VERSION ""

NS_ :

BS_:

BU_: ETH

BO_ 946 BMS_log2: 8 Vector__XXX
 SG_ BMS_log2MuxId M : 0|7@1+ (1,0) [0|0] "" Vector__XXX
 SG_ BMS_acRippleConfigNvramValid m18 : 7|1@1+ (1,0) [0|0] "" Vector__XXX
 SG_ BMS_acRippleHeatingDesired m28 : 7|1@1+ (1,0) [0|0] "" Vector__XXX
 SG_ BMS_acRippleStopTemperatureMax m19 : 7|9@1+ (0.25,-25) [0|0] "" Vector__XXX
 SG_ BMS_alphaAlertLimitingEnabled m68 : 7|1@1+ (1,0) [0|0] "" Vector__XXX
 SG_ BMS_alphaSoc1SnapshotState m34 : 7|1@1+ (1,0) [0|0] "" Vector__XXX
 SG_ BMS_lifeModelNoCurrentStorageCapacityLoss m54 : 7|9@1+ (0.1,0) [0|0] "" Vector__XXX
 SG_ BMS_maxChargeRestartNeededByVoltage m0 : 7|1@1+ (1,0) [0|0] "" Vector__XXX
 SG_ BMS_spmeElyteModelValidFlag m48 : 7|1@1+ (1,0) [0|0] "" Vector__XXX
 SG_ BMS_tempVsSocTotalChgEnergy m31 : 7|25@1+ (0.0001490116163793688,0) [0|0] "" Vector__XXX
 SG_ BMS_tempVsSocTotalTime m30 : 7|25@1+ (0.01,0) [0|0] "" Vector__XXX
 SG_ BMS_tempVsVoltageTotalDcChgEnergy m32 : 7|25@1+ (0.0001490116163793688,0) [0|0] "" Vector__XXX
 SG_ BMS_unexpectedLossOfLvPcsMia m57 : 7|1@1+ (1,0) [0|0] "" Vector__XXX
 SG_ BMS_100HzTask_avgExecTime m8 : 8|14@1+ (1,0) [0|0] "" Vector__XXX
 SG_ BMS_10HzTask_avgExecTime m7 : 8|17@1+ (1,0) [0|0] "" Vector__XXX
 SG_ BMS_1HzTask_avgExecTime m6 : 8|20@1+ (1,0) [0|0] "" Vector__XXX
 SG_ BMS_ahChargeTotal m5 : 8|24@1+ (0.1,0) [0|0] "" Vector__XXX
 SG_ BMS_alphaConfigNvramValid m68 : 8|1@1+ (1,0) [0|0] "" Vector__XXX
 SG_ BMS_avgRawCacForSpread m62 : 8|12@1+ (0.1,0) [0|0] "" Vector__XXX
 SG_ BMS_brick1SocCorrectionMagnitude m74 : 8|11@1- (0.1,0) [0|0] "" Vector__XXX
 SG_ BMS_brickBleedByAhTarget m36 : 8|13@1+ (0.1,0) [0|0] "" Vector__XXX
 SG_ BMS_brickBleedChargeMin m34 : 8|16@1+ (0.1,0) [0|0] "" Vector__XXX
 SG_ BMS_brickBleedChargeRef m35 : 8|16@1+ (0.1,0) [0|0] "" Vector__XXX
 SG_ BMS_brickBleedExcessChargeMin m37 : 8|16@1+ (0.1,0) [0|0] "" Vector__XXX
 SG_ BMS_brickCacSpreadErrorStdDeviation m61 : 8|10@1+ (0.01,0) [0|0] "" Vector__XXX
 SG_ BMS_cacAgedLowerBoundEstBrick1 m59 : 8|13@1+ (0.1,0) [0|0] "" Vector__XXX
 SG_ BMS_cacAgedUpdateShuntAhError m58 : 8|9@1+ (0.1,-10) [0|0] "" Vector__XXX
 SG_ BMS_cacAvg m0 : 8|13@1+ (0.1,0) [0|0] "" Vector__XXX
 SG_ BMS_cacMetadataNvramIsValid m2 : 8|1@1+ (1,0) [0|0] "" Vector__XXX
 SG_ BMS_cacMinLowerBoundEst m1 : 8|13@1+ (0.1,0) [0|0] "" Vector__XXX
 SG_ BMS_cacMinSocByOcvStart m22 : 8|10@1+ (0.1,0) [0|0] "" Vector__XXX
 SG_ BMS_cacRawImbalanceEstimate m44 : 8|10@1+ (0.1,0) [0|0] "" Vector__XXX
 SG_ BMS_cellAttributesGeneralAttributes m85 : 8|32@1+ (1,0) [0|0] "" Vector__XXX
 SG_ BMS_chargeEnergyCounter m86 : 8|8@1+ (1,0) [0|0] "" Vector__XXX
 SG_ BMS_cumulativeBleedTime m39 : 8|24@1+ (1,0) [0|0] "" Vector__XXX
 SG_ BMS_cumulativeBleedTimeDaily m47 : 8|24@1+ (1,0) [0|0] "" Vector__XXX
 SG_ BMS_cumulativeBrickBleedTimeMax m41 : 8|32@1+ (1,0) [0|0] "" Vector__XXX
 SG_ BMS_cumulativeBrickBleedTimeMin m40 : 8|32@1+ (1,0) [0|0] "" Vector__XXX
 SG_ BMS_dSocMaxAlphaSocBleedMargin m42 : 8|12@1+ (0.0030517578125,0) [0|0] "" Vector__XXX
 SG_ BMS_dSocNormalizedMin m33 : 8|12@1+ (0.0030517578125,-12.4969482421875) [0|0] "" Vector__XXX
 SG_ BMS_energyLowestChgBrickSoc m87 : 8|10@1+ (0.1,0) [0|0] "" Vector__XXX
 SG_ BMS_energyVariableChgRequested m21 : 8|1@1+ (1,0) [0|0] "" Vector__XXX
 SG_ BMS_energyWalkCounter m83 : 8|8@1+ (1,0) [0|0] "" Vector__XXX
 SG_ BMS_epochTimeEstimate m29 : 8|32@1+ (1,0) [0|0] "" Vector__XXX
 SG_ BMS_fcLinkTestDecayTime m20 : 8|10@1+ (2,0) [0|0] "" Vector__XXX
 SG_ BMS_histStartEpochTime m28 : 8|32@1+ (1,0) [0|0] "" Vector__XXX
 SG_ BMS_hvChain_useLeakyBucket m18 : 8|1@1+ (1,0) [0|0] "" Vector__XXX
 SG_ BMS_hvacCoolingChargeCurrentLimit m88 : 8|10@1+ (1,0) [0|0] "" Vector__XXX
 SG_ BMS_isoResistanceIntPositive m43 : 8|10@1+ (10,0) [0|0] "" Vector__XXX
 SG_ BMS_largestCacSpreadErrorBrickId m63 : 8|7@1+ (1,1) [0|0] "" Vector__XXX
 SG_ BMS_largestCacSpreadErrorLower m64 : 8|12@1+ (0.1,0) [0|0] "" Vector__XXX
 SG_ BMS_largestDerivedCacErrorBrickId m67 : 8|8@1+ (1,1) [0|0] "" Vector__XXX
 SG_ BMS_largestSynchronizedCacErrorPctInWindow m81 : 8|8@1+ (0.1,0) [0|0] "" Vector__XXX
 SG_ BMS_lifeModelAvgTempSeverity m55 : 8|5@1+ (0.1,0) [0|0] "" Vector__XXX
 SG_ BMS_lifeModelMaxCacBrickId m65 : 8|8@1+ (1,1) [0|0] "" Vector__XXX
 SG_ BMS_lifeModelSpreadMinOffset m60 : 8|10@1- (0.1,0) [0|0] "" Vector__XXX
 SG_ BMS_lifeModelStorageTemperatureSeverityMax m78 : 8|7@1+ (0.1,0) [0|0] "" Vector__XXX
 SG_ BMS_limpChargeCurrentLimit m89 : 8|10@1+ (1,0) [0|0] "" Vector__XXX
 SG_ BMS_loadReg_output m4 : 8|11@1- (0.1,0) [0|0] "" Vector__XXX
 SG_ BMS_maxSocChange m24 : 8|11@1- (0.1,0) [0|0] "" Vector__XXX
 SG_ BMS_maxSpreadCacChange m75 : 8|10@1- (0.1,0) [0|0] "" Vector__XXX
 SG_ BMS_maxSpreadChangeSocEnd m76 : 8|10@1+ (0.1,0) [0|0] "" Vector__XXX
 SG_ BMS_minBrickAhDischargedAfterZero m70 : 8|16@1+ (0.1,0) [0|0] "" Vector__XXX
 SG_ BMS_minCapacityLoss m38 : 8|10@1+ (0.1,0) [0|0] "" Vector__XXX
 SG_ BMS_negCtrCommonModeRejError m17 : 8|13@1- (2.442592959e-05,0) [0|0] "" Vector__XXX
 SG_ BMS_negCtrDeviationFiltMin m15 : 8|13@1- (0.001221299164314,0) [0|0] "" Vector__XXX
 SG_ BMS_negCtrDeviationMin m14 : 8|13@1- (0.001221299164314,0) [0|0] "" Vector__XXX
 SG_ BMS_negCtrDropCorrectedMin m16 : 8|13@1- (0.001221299164314,0) [0|0] "" Vector__XXX
 SG_ BMS_nominalFullPackEnergyRaw m56 : 8|16@1+ (0.02,0) [0|0] "" Vector__XXX
 SG_ BMS_posCtrCommonModeRejError m13 : 8|13@1- (2.4425983286e-05,0) [0|0] "" Vector__XXX
 SG_ BMS_posCtrDeviationFiltMin m11 : 8|13@1- (0.001221299164314,0) [0|0] "" Vector__XXX
 SG_ BMS_posCtrDeviationMin m10 : 8|13@1- (0.001221299164314,0) [0|0] "" Vector__XXX
 SG_ BMS_posCtrDropCorrectedMin m12 : 8|13@1- (0.001221299164314,0) [0|0] "" Vector__XXX
 SG_ BMS_posCtrResistance m9 : 8|13@1- (2.442598329e-06,0) [0|0] "" Vector__XXX
 SG_ BMS_restingPointCacMaxBrickId m66 : 8|8@1+ (1,1) [0|0] "" Vector__XXX
 SG_ BMS_rubberBandingConfigMaxBlendRate m72 : 8|13@1+ (0.01,0) [0|0] "" Vector__XXX
 SG_ BMS_sleepCurrentSampleMin m84 : 8|15@1- (0.2,0) [0|0] "" Vector__XXX
 SG_ BMS_socByDeltaVEnabled m90 : 8|1@1+ (1,0) [0|0] "" Vector__XXX
 SG_ BMS_socByDvMaxSocByAhRaw m91 : 8|10@1+ (0.1,0) [0|0] "" Vector__XXX
 SG_ BMS_socByOcvEst m69 : 8|10@1+ (0.1,0) [0|0] "" Vector__XXX
 SG_ BMS_socCorrectionCycleFlag m73 : 8|1@1+ (1,0) [0|0] "" Vector__XXX
 SG_ BMS_sohEnergy m79 : 8|11@1+ (0.1,0) [0|0] "" Vector__XXX
 SG_ BMS_sohLowSocPointMinPackTemp m82 : 8|9@1+ (0.25,-25) [0|0] "" Vector__XXX
 SG_ BMS_sohTestStateInternal m45 : 8|4@1+ (1,0) [0|0] "" Vector__XXX
 SG_ BMS_spmeBrick1BrickSocNominal m50 : 8|10@1+ (0.1,0) [0|0] "" Vector__XXX
 SG_ BMS_spmeBrick1ElectrolyteVoltage m49 : 8|13@1- (0.001,0) [0|0] "" Vector__XXX
 SG_ BMS_spmeMaxSocBrickId m53 : 8|8@1+ (1,1) [0|0] "" Vector__XXX
 SG_ BMS_spmeMinBrickModel0Cost m51 : 8|12@1+ (1e-05,0) [0|0] "" Vector__XXX
 SG_ BMS_spmeMinSocBrickId m52 : 8|8@1+ (1,1) [0|0] "" Vector__XXX
 SG_ BMS_spmeModelRunning m48 : 8|1@1+ (1,0) [0|0] "" Vector__XXX
 SG_ BMS_stateOfHealthAvgCacByFreshOcv m77 : 8|13@1+ (0.1,0) [0|0] "" Vector__XXX
 SG_ BMS_stateOfHealthMinCac m80 : 8|13@1+ (0.1,0) [0|0] "" Vector__XXX
 SG_ BMS_synchronizedCacMaxRaw m71 : 8|12@1+ (0.1,0) [0|0] "" Vector__XXX
 SG_ BMS_tempVsSocTimeWeightedAvgSoc m46 : 8|14@1+ (0.01,0) [0|0] "" Vector__XXX
 SG_ BMS_unexpectedLossOfLvPcsDcDcLvSupportStatus m57 : 8|2@1+ (1,0) [0|0] "" Vector__XXX
 SG_ BMS_vChangeWindowMaxVChange m23 : 8|7@1- (0.0025,0) [0|0] "" Vector__XXX
 SG_ BMS_vshResMaxIndex1 m25 : 8|6@1+ (1,0) [0|0] "" Vector__XXX
 SG_ BMS_vshResMaxIndex4 m27 : 8|6@1+ (1,0) [0|0] "" Vector__XXX
 SG_ BMS_vshResMinIndex2 m26 : 8|6@1+ (1,0) [0|0] "" Vector__XXX
 SG_ BMS_vshTestMaxDeltaV m3 : 8|16@1- (0.0002,0) [0|0] "" Vector__XXX
 SG_ BMS_alphaAlertThreshold m68 : 9|12@1+ (0.0030517578125,-12.4969482421875) [0|0] "" Vector__XXX
 SG_ BMS_cacNvramIsValid m2 : 9|1@1+ (1,0) [0|0] "" Vector__XXX
 SG_ BMS_hvChain_iLimit m18 : 9|14@1+ (0.2,0) [0|0] "" Vector__XXX
 SG_ BMS_minBrickSocCorrectionType m73 : 9|2@1+ (1,0) [0|0] "" Vector__XXX
 SG_ BMS_packRestTime m21 : 9|12@1+ (0.01758241758,0) [0|0] "" Vector__XXX
 SG_ BMS_socByDvMaxSocLimit m90 : 9|10@1+ (0.1,0) [0|0] "" Vector__XXX
 SG_ BMS_spmeNominalAhThroughput m48 : 9|16@1+ (0.1,0) [0|0] "" Vector__XXX
 SG_ BMS_floodPortState1 m2 : 10|3@1+ (1,0) [0|0] "" Vector__XXX
 SG_ BMS_stateOfHealthAvgCac m57 : 10|13@1+ (0.1,0) [0|0] "" Vector__XXX
 SG_ BMS_minBrickSocCorrectionMagnitude m73 : 11|11@1- (0.1,0) [0|0] "" Vector__XXX
 SG_ BMS_kwhDchAtSohCapture m45 : 12|32@1+ (1,0) [0|0] "" Vector__XXX
 SG_ BMS_floodPortState2 m2 : 13|3@1+ (1,0) [0|0] "" Vector__XXX
 SG_ BMS_vshResMinIndex4 m27 : 14|6@1+ (1,0) [0|0] "" Vector__XXX
 SG_ BMS_energyLatchedMaxChargePower m86 : 16|9@1+ (1,0) [0|0] "" Vector__XXX
 SG_ BMS_energyReserveMin m19 : 16|16@1+ (0.001,0) [0|0] "" Vector__XXX
 SG_ BMS_energyWalkTimeoutCounter m83 : 16|8@1+ (1,0) [0|0] "" Vector__XXX
 SG_ BMS_floodPortV1 m2 : 16|16@1+ (0.001,0) [0|0] "" Vector__XXX
 SG_ BMS_largestCacSpreadErrorBrickStartSoc m63 : 16|10@1+ (0.1,0) [0|0] "" Vector__XXX
 SG_ BMS_largestDerivedCacError m67 : 16|10@1- (0.01,0) [0|0] "" Vector__XXX
 SG_ BMS_lifeModelDepthOfDischargeSeverity m55 : 16|8@1+ (0.01,0) [0|0] "" Vector__XXX
 SG_ BMS_lifeModelMaxCac m65 : 16|12@1+ (0.1,0) [0|0] "" Vector__XXX
 SG_ BMS_lifeModelShortDcr m54 : 16|8@1+ (0.01,0) [0|0] "" Vector__XXX
 SG_ BMS_lifeModelStorageDcr1TemperatureSeverityMax m78 : 16|7@1+ (0.1,0) [0|0] "" Vector__XXX
 SG_ BMS_maxZScoreInTimeWindow m81 : 16|6@1+ (0.1,0) [0|0] "" Vector__XXX
 SG_ BMS_restingPointCacMax m66 : 16|12@1+ (0.1,0) [0|0] "" Vector__XXX
 SG_ BMS_spmeMaxSocLowestCost m53 : 16|10@1+ (0.1,0) [0|0] "" Vector__XXX
 SG_ BMS_spmeMinSocLowestCost m52 : 16|10@1+ (0.1,0) [0|0] "" Vector__XXX
 SG_ BMS_vChangeWindowMaxVChangeId m23 : 16|7@1+ (1,1) [0|0] "" Vector__XXX
 SG_ BMS_vshResMax1 m25 : 16|12@1+ (0.002,0) [0|0] "" Vector__XXX
 SG_ BMS_vshResMin2 m26 : 16|12@1+ (0.002,0) [0|0] "" Vector__XXX
 SG_ BMS_cacMinAgedLowerBoundEst m58 : 17|13@1+ (0.1,0) [0|0] "" Vector__XXX
 SG_ BMS_sohHighSocPointMinPackTemp m82 : 17|9@1+ (0.25,-25) [0|0] "" Vector__XXX
 SG_ BMS_cacMinSocByOcvEnd m22 : 18|10@1+ (0.1,0) [0|0] "" Vector__XXX
 SG_ BMS_cacRawImbalanceUpperBound m44 : 18|10@1+ (0.1,0) [0|0] "" Vector__XXX
 SG_ BMS_configChargeCurrentLimit m88 : 18|10@1+ (1,0) [0|0] "" Vector__XXX
 SG_ BMS_energyLowestChgBrickCac m87 : 18|13@1+ (0.1,0) [0|0] "" Vector__XXX
 SG_ BMS_energyRemainingDisplayError m89 : 18|10@1- (0.1,0) [0|0] "" Vector__XXX
 SG_ BMS_fcLinkTestTimeSinceLastRun m20 : 18|12@1+ (0.01758241758,0) [0|0] "" Vector__XXX
 SG_ BMS_firstSynchronizedCacUpdateTime m76 : 18|32@1+ (1,0) [0|0] "" Vector__XXX
 SG_ BMS_isoResistanceIntNegative m43 : 18|10@1+ (10,0) [0|0] "" Vector__XXX
 SG_ BMS_lifeModelSpreadMaxOffset m60 : 18|10@1- (0.1,0) [0|0] "" Vector__XXX
 SG_ BMS_maxCapacityLoss m38 : 18|10@1+ (0.1,0) [0|0] "" Vector__XXX
 SG_ BMS_maxSpreadChangeBrickId m75 : 18|8@1+ (1,1) [0|0] "" Vector__XXX
 SG_ BMS_minCacBrickBiasedSpreadAhError m61 : 18|10@1+ (0.01,0) [0|0] "" Vector__XXX
 SG_ BMS_socByOcvMax m69 : 18|10@1+ (0.1,0) [0|0] "" Vector__XXX
 SG_ BMS_spmeBrick1SocLowestCost m50 : 18|10@1+ (0.1,0) [0|0] "" Vector__XXX
 SG_ BMS_voltageInstabilityExcessNoiseLog m91 : 18|12@1+ (0.1,0) [0|0] "" Vector__XXX
 SG_ BMS_brick1SocCorrectionFinalSoc m74 : 19|10@1+ (0.1,0) [0|0] "" Vector__XXX
 SG_ BMS_fullCapacitySohEnergy m79 : 19|11@1+ (0.1,0) [0|0] "" Vector__XXX
 SG_ BMS_offsetReg_output m4 : 19|14@1- (0.1,0) [0|0] "" Vector__XXX
 SG_ BMS_socByDvVoltageChangeOverAh m90 : 19|9@1+ (0.002,0) [0|0] "" Vector__XXX
 SG_ BMS_vChangeWindowNumOutlierChanges m24 : 19|5@1+ (1,0) [0|0] "" Vector__XXX
 SG_ BMS_dSocNormalizedFiltMin m33 : 20|12@1+ (0.0030517578125,-12.4969482421875) [0|0] "" Vector__XXX
 SG_ BMS_largestSyncCacErrorBrickId m62 : 20|7@1+ (1,1) [0|0] "" Vector__XXX
 SG_ BMS_lifeModelAverageCac m64 : 20|12@1+ (0.1,0) [0|0] "" Vector__XXX
 SG_ BMS_spmeMinBrickModel5Cost m51 : 20|12@1+ (1e-05,0) [0|0] "" Vector__XXX
 SG_ BMS_synchronizedCacMinRaw m71 : 20|12@1+ (0.1,0) [0|0] "" Vector__XXX
 SG_ BMS_vshResMax4 m27 : 20|12@1+ (0.002,0) [0|0] "" Vector__XXX
 SG_ BMS_alphaSnapshotExpirationTime m68 : 21|4@1+ (1,0) [0|0] "" Vector__XXX
 SG_ BMS_idealEnergyFloor m21 : 21|10@1+ (0.1,0) [0|0] "" Vector__XXX
 SG_ BMS_maxChargeNearComplete m0 : 21|1@1+ (1,0) [0|0] "" Vector__XXX
 SG_ BMS_rubberBandingConfigMaxPctErrorForReset m72 : 21|10@1+ (0.1,0) [0|0] "" Vector__XXX
 SG_ BMS_spmeBrick1AnodeBulkConcentration m49 : 21|10@1+ (0.001,0) [0|0] "" Vector__XXX
 SG_ BMS_stateOfHealthByFreshOcv m77 : 21|13@1+ (0.1,0) [0|0] "" Vector__XXX
 SG_ BMS_minBrickSocCorrectionFinalSoc m73 : 22|10@1+ (0.1,0) [0|0] "" Vector__XXX
 SG_ BMS_tempVsSocTimeWeightedAvgTemp m46 : 22|14@1- (0.1,0) [0|0] "" Vector__XXX
 SG_ BMS_hvChain_limitingState m18 : 23|9@1+ (1,1) [0|0] "" Vector__XXX
 SG_ BMS_sleepCurrentSampleMax m84 : 23|15@1- (0.2,0) [0|0] "" Vector__XXX
 SG_ BMS_1kHzTask_avgExecTime m8 : 24|11@1+ (1,0) [0|0] "" Vector__XXX
 SG_ BMS_balanceTimeThisCycle m35 : 24|16@1+ (0.5,0) [0|0] "" Vector__XXX
 SG_ BMS_brick1AhDischargedAfterZero m70 : 24|16@1+ (0.1,0) [0|0] "" Vector__XXX
 SG_ BMS_brickBleedByAhMin m36 : 24|13@1+ (0.1,0) [0|0] "" Vector__XXX
 SG_ BMS_brickBleedChargeMax m34 : 24|16@1+ (0.1,0) [0|0] "" Vector__XXX
 SG_ BMS_brickBleedExcessChargeMax m37 : 24|16@1+ (0.1,0) [0|0] "" Vector__XXX
 SG_ BMS_cacAgedRawEstimateBrick1 m59 : 24|13@1+ (0.1,0) [0|0] "" Vector__XXX
 SG_ BMS_cacMin m0 : 24|13@1+ (0.1,0) [0|0] "" Vector__XXX
 SG_ BMS_cacMinRawEstimate m1 : 24|13@1+ (0.1,0) [0|0] "" Vector__XXX
 SG_ BMS_cacMinSocByAgedOcvStart m57 : 24|10@1+ (0.1,0) [0|0] "" Vector__XXX
 SG_ BMS_dSocMaxAlphaBrickID m42 : 24|7@1+ (1,1) [0|0] "" Vector__XXX
 SG_ BMS_dynamicCcvEnabled m83 : 24|1@1+ (1,0) [0|0] "" Vector__XXX
 SG_ BMS_lifeModelHistogramCapacityLoss m55 : 24|9@1+ (0.1,0) [0|0] "" Vector__XXX
 SG_ BMS_lifeModelLongDcr m54 : 24|13@1- (0.1,309.6) [0|0] "" Vector__XXX
 SG_ BMS_lifeModelStorageDcr2TemperatureSeverityMin m78 : 24|7@1+ (0.025,0) [0|0] "" Vector__XXX
 SG_ BMS_lifeModelStorageLossPackAge m80 : 24|14@1+ (1,0) [0|0] "" Vector__XXX
 SG_ BMS_maxSocChangeBrickId m24 : 24|7@1+ (1,1) [0|0] "" Vector__XXX
 SG_ BMS_minZScoreInTimeWindow m81 : 24|6@1+ (0.1,0) [0|0] "" Vector__XXX
 SG_ BMS_negCtrCommonModeRejErrorConf m17 : 24|13@1+ (1.221001071916841,0) [0|0] "" Vector__XXX
 SG_ BMS_negCtrDeviationFiltMax m15 : 24|13@1- (0.001221299164314,0) [0|0] "" Vector__XXX
 SG_ BMS_negCtrDeviationMax m14 : 24|13@1- (0.001221299164314,0) [0|0] "" Vector__XXX
 SG_ BMS_negCtrDropCorrectedMax m16 : 24|13@1- (0.001221299164314,0) [0|0] "" Vector__XXX
 SG_ BMS_nominalEnergyRemainingBuffered m56 : 24|16@1+ (0.02,0) [0|0] "" Vector__XXX
 SG_ BMS_posCtrCommonModeRejErrorConf m13 : 24|13@1+ (1.221001071916841,0) [0|0] "" Vector__XXX
 SG_ BMS_posCtrDeviationFiltMax m11 : 24|13@1- (0.001221299164314,0) [0|0] "" Vector__XXX
 SG_ BMS_posCtrDeviationMax m10 : 24|13@1- (0.001221299164314,0) [0|0] "" Vector__XXX
 SG_ BMS_posCtrDropCorrectedMax m12 : 24|13@1- (0.001221299164314,0) [0|0] "" Vector__XXX
 SG_ BMS_posCtrResistanceConfidence m9 : 24|13@1+ (12.21001071916841,0) [0|0] "" Vector__XXX
 SG_ BMS_vChangeWindowMinBrickVId m23 : 24|7@1+ (1,1) [0|0] "" Vector__XXX
 SG_ BMS_vshTestMaxDeltaVBrickID m3 : 24|7@1+ (1,1) [0|0] "" Vector__XXX
 SG_ BMS_chargeTargetLookupSoc m83 : 25|10@1+ (0.1,0) [0|0] "" Vector__XXX
 SG_ BMS_energyLatchedMaxChargeCurrent m86 : 25|12@1+ (1,0) [0|0] "" Vector__XXX
 SG_ BMS_socChangeByAgedOcvTempCorrectedVoltage m68 : 25|12@1+ (0.001,1) [0|0] "" Vector__XXX
 SG_ BMS_spmeRestAhThroughput m48 : 25|16@1+ (0.1,0) [0|0] "" Vector__XXX
 SG_ BMS_largestCacSpreadErrorBrickEndSoc m63 : 26|10@1+ (0.1,0) [0|0] "" Vector__XXX
 SG_ BMS_maxSpreadChangeCacRaw m75 : 26|12@1+ (0.1,0) [0|0] "" Vector__XXX
 SG_ BMS_packCalibrationBirthDateBinned m67 : 26|32@1+ (1,0) [0|0] "" Vector__XXX
 SG_ BMS_sohCacMinSocByOcvEnd m82 : 26|10@1+ (0.1,0) [0|0] "" Vector__XXX
 SG_ BMS_spmeMaxSocLowerBound m53 : 26|10@1+ (0.1,0) [0|0] "" Vector__XXX
 SG_ BMS_spmeMinSocLowerBound m52 : 26|10@1+ (0.1,0) [0|0] "" Vector__XXX
 SG_ BMS_largestSyncCacErrorRaw m62 : 27|12@1+ (0.1,0) [0|0] "" Vector__XXX
 SG_ BMS_avgCapacityLoss m38 : 28|10@1+ (0.1,0) [0|0] "" Vector__XXX
 SG_ BMS_cacMinDeltaAh m22 : 28|11@1- (0.5,0) [0|0] "" Vector__XXX
 SG_ BMS_cacRawImbalanceLowerBound m44 : 28|10@1+ (0.1,0) [0|0] "" Vector__XXX
 SG_ BMS_cacsSynchronizedForAvgUpdate m61 : 28|1@1+ (1,0) [0|0] "" Vector__XXX
 SG_ BMS_energyRemainingTDisplayError m89 : 28|10@1- (0.1,0) [0|0] "" Vector__XXX
 SG_ BMS_fuseChargeCurrentLimit m88 : 28|10@1+ (1,0) [0|0] "" Vector__XXX
 SG_ BMS_isoResistanceExtPositive m43 : 28|10@1+ (10,0) [0|0] "" Vector__XXX
 SG_ BMS_lifeModelMinCacBrickId m65 : 28|8@1+ (1,1) [0|0] "" Vector__XXX
 SG_ BMS_lifeModelSpreadAvgOffset m60 : 28|10@1- (0.1,0) [0|0] "" Vector__XXX
 SG_ BMS_socByDvMaxSocByAhCorrected m90 : 28|10@1+ (0.1,0) [0|0] "" Vector__XXX
 SG_ BMS_socByOcvMin m69 : 28|10@1+ (0.1,0) [0|0] "" Vector__XXX
 SG_ BMS_spmeBrick1SocLowerBound m50 : 28|10@1+ (0.1,0) [0|0] "" Vector__XXX
 SG_ BMS_vshResMaxIndex3 m26 : 28|6@1+ (1,0) [0|0] "" Vector__XXX
 SG_ BMS_vshResMinIndex1 m25 : 28|6@1+ (1,0) [0|0] "" Vector__XXX
 SG_ BMS_cacsSynchronizedForSpreadUpdate m61 : 29|1@1+ (1,0) [0|0] "" Vector__XXX
 SG_ BMS_cacMinAgedRawEstimate m58 : 30|13@1+ (0.1,0) [0|0] "" Vector__XXX
 SG_ BMS_cacStartPointSocSpread m61 : 30|10@1+ (0.1,0) [0|0] "" Vector__XXX
 SG_ BMS_calibratedCapacitySohEnergy m79 : 30|11@1+ (0.1,0) [0|0] "" Vector__XXX
 SG_ BMS_maxModelThermistorTempDelta m91 : 30|10@1- (0.1,0) [0|0] "" Vector__XXX
 SG_ BMS_pcsPrechargeRequest m20 : 30|2@1+ (1,0) [0|0] "" Vector__XXX
 SG_ BMS_percentCacAvgOffsetUpdatesInTimeWindow m81 : 30|10@1+ (0.1,0) [0|0] "" Vector__XXX
 SG_ BMS_energyLowestDchBrickSoc m87 : 31|10@1+ (0.1,0) [0|0] "" Vector__XXX
 SG_ BMS_thmGradientSlopeCondition m21 : 31|1@1+ (1,0) [0|0] "" Vector__XXX
 SG_ BMS_10HzTask_maxExecTime m7 : 32|17@1+ (1,0) [0|0] "" Vector__XXX
 SG_ BMS_1HzTask_maxExecTime m6 : 32|20@1+ (1,0) [0|0] "" Vector__XXX
 SG_ BMS_ahDischargeTotal m5 : 32|24@1+ (0.1,0) [0|0] "" Vector__XXX
 SG_ BMS_brick1SocCorrectionSpmeCost m74 : 32|12@1+ (1e-05,0) [0|0] "" Vector__XXX
 SG_ BMS_cumulativeAvailableBleedTime m39 : 32|24@1+ (1,0) [0|0] "" Vector__XXX
 SG_ BMS_cumulativeAvailableBleedTimeDaily m47 : 32|24@1+ (1,0) [0|0] "" Vector__XXX
 SG_ BMS_cumulativeBrickBleedTimeAvg m42 : 32|32@1+ (1,0) [0|0] "" Vector__XXX
 SG_ BMS_dSocMinAlpha m33 : 32|12@1+ (0.0030517578125,-12.4969482421875) [0|0] "" Vector__XXX
 SG_ BMS_energyReserveMax m19 : 32|16@1+ (0.001,0) [0|0] "" Vector__XXX
 SG_ BMS_floodPortV2 m2 : 32|16@1+ (0.001,0) [0|0] "" Vector__XXX
 SG_ BMS_hvChain_limitingStateTemperature m18 : 32|13@1- (0.1,367.6) [0|0] "" Vector__XXX
 SG_ BMS_largestSyncCacErrorStartSoc m71 : 32|10@1+ (0.1,0) [0|0] "" Vector__XXX
 SG_ BMS_lifeModelCacBrick1 m64 : 32|12@1+ (0.1,0) [0|0] "" Vector__XXX
 SG_ BMS_lifeModelThroughputTemperatureSeverityMax m78 : 32|6@1+ (0.1,0) [0|0] "" Vector__XXX
 SG_ BMS_minBrickSocCorrectionSpmeCost m73 : 32|12@1+ (1e-05,0) [0|0] "" Vector__XXX
 SG_ BMS_pcsPrechargeTargetVoltage m20 : 32|16@1- (0.1,0) [0|0] "" Vector__XXX
 SG_ BMS_powerVsVoltageTotalChgEnergy m31 : 32|25@1+ (0.0001490116163793688,0) [0|0] "" Vector__XXX
 SG_ BMS_recentSlopeConditon m21 : 32|1@1+ (1,0) [0|0] "" Vector__XXX
 SG_ BMS_restingPointCacMinBrickId m66 : 32|8@1+ (1,1) [0|0] "" Vector__XXX
 SG_ BMS_runtimeSocResetThresholdInSupport m72 : 32|10@1+ (0.1,0) [0|0] "" Vector__XXX
 SG_ BMS_socChangeSocByOcvMin m24 : 32|10@1+ (0.1,0) [0|0] "" Vector__XXX
 SG_ BMS_socTopVsSocBottomTotalDchEnergy m32 : 32|25@1+ (0.0001490116163793688,0) [0|0] "" Vector__XXX
 SG_ BMS_spmeBrick1AnodeSurfaceConcentration m49 : 32|10@1+ (0.001,0) [0|0] "" Vector__XXX
 SG_ BMS_spmeMinBrickModel10Cost m51 : 32|12@1+ (1e-05,0) [0|0] "" Vector__XXX
 SG_ BMS_tempVsSocTotalDchEnergy m30 : 32|25@1+ (0.0001490116163793688,0) [0|0] "" Vector__XXX
 SG_ BMS_vChangeWindowChangeInitV m23 : 32|12@1+ (0.002,0) [0|0] "" Vector__XXX
 SG_ BMS_vshResMin4 m27 : 32|12@1+ (0.002,0) [0|0] "" Vector__XXX
 SG_ BMS_vshTestMinDeltaV m3 : 32|16@1+ (0.0002,0) [0|0] "" Vector__XXX
 SG_ BMS_chargeNeededState m4 : 33|3@1+ (1,0) [0|0] "" Vector__XXX
 SG_ BMS_dynamicEnergyBuffer m21 : 33|10@1+ (0.1,0) [0|0] "" Vector__XXX
 SG_ BMS_lifeModelHistogramBrickCapacity m55 : 33|13@1+ (0.1,0) [0|0] "" Vector__XXX
 SG_ BMS_cacMinSocByAgedOcvEnd m57 : 34|10@1+ (0.1,0) [0|0] "" Vector__XXX
 SG_ BMS_lifeModelStorageDcrGrowthPercent m77 : 34|14@1- (0.1,200) [0|0] "" Vector__XXX
 SG_ BMS_vshResMax3 m26 : 34|12@1+ (0.002,0) [0|0] "" Vector__XXX
 SG_ BMS_vshResMin1 m25 : 34|12@1+ (0.002,0) [0|0] "" Vector__XXX
 SG_ BMS_100HzTask_maxExecTime m8 : 35|14@1+ (1,0) [0|0] "" Vector__XXX
 SG_ BMS_stateOfHealth m83 : 35|10@1+ (0.1,0) [0|0] "" Vector__XXX
 SG_ BMS_largestCacSpreadErrorRaw m63 : 36|12@1+ (0.1,0) [0|0] "" Vector__XXX
 SG_ BMS_lifeModelMinCac m65 : 36|12@1+ (0.1,0) [0|0] "" Vector__XXX
 SG_ BMS_maxDcCurrentAvailable m4 : 36|11@1+ (0.5,0) [0|0] "" Vector__XXX
 SG_ BMS_sohCacMinSocByOcvStart m82 : 36|10@1+ (0.1,0) [0|0] "" Vector__XXX
 SG_ BMS_spmeMaxSocUpperBound m53 : 36|10@1+ (0.1,0) [0|0] "" Vector__XXX
 SG_ BMS_spmeMinSocUpperBound m52 : 36|10@1+ (0.1,0) [0|0] "" Vector__XXX
 SG_ BMS_tempVsSocChgAndDchWeightedAvgTemp m46 : 36|14@1- (0.1,0) [0|0] "" Vector__XXX
 SG_ BMS_acRippleCurrentAmplitudeIdeal m68 : 37|10@1+ (1,0) [0|0] "" Vector__XXX
 SG_ BMS_cacAgedUpperBoundEstBrick1 m59 : 37|13@1+ (0.1,0) [0|0] "" Vector__XXX
 SG_ BMS_cacMinBrickId m0 : 37|7@1+ (1,1) [0|0] "" Vector__XXX
 SG_ BMS_lifeModelStorageCapacityLoss m54 : 37|9@1+ (0.1,0) [0|0] "" Vector__XXX
 SG_ BMS_negCtrDeviationConfidenceMin m14 : 37|13@1+ (0.000122100107192,0) [0|0] "" Vector__XXX
 SG_ BMS_negCtrDeviationFiltConfMin m15 : 37|13@1+ (0.000122100107192,0) [0|0] "" Vector__XXX
 SG_ BMS_negCtrDropCorrectedFiltMin m16 : 37|13@1- (0.001221299164314,0) [0|0] "" Vector__XXX
 SG_ BMS_negCtrOffsetError m17 : 37|13@1- (0.001221299164314,0) [0|0] "" Vector__XXX
 SG_ BMS_negCtrResistance m9 : 37|13@1- (2.442598329e-06,0) [0|0] "" Vector__XXX
 SG_ BMS_posCtrDeviationConfidenceMin m10 : 37|13@1+ (0.000122100107192,0) [0|0] "" Vector__XXX
 SG_ BMS_posCtrDeviationFiltConfMin m11 : 37|13@1+ (0.000122100107192,0) [0|0] "" Vector__XXX
 SG_ BMS_posCtrDropCorrectedFiltMin m12 : 37|13@1- (0.001221299164314,0) [0|0] "" Vector__XXX
 SG_ BMS_posCtrOffsetError m13 : 37|13@1- (0.001221299164314,0) [0|0] "" Vector__XXX
 SG_ BMS_predictedEnergyCharged m86 : 37|11@1+ (0.1,0) [0|0] "" Vector__XXX
 SG_ BMS_isoResistanceExtNegative m43 : 38|10@1+ (10,0) [0|0] "" Vector__XXX
 SG_ BMS_maxSpreadChangeCacPrev m75 : 38|12@1+ (0.1,0) [0|0] "" Vector__XXX
 SG_ BMS_missingCellCurrentLimit m88 : 38|10@1+ (1,0) [0|0] "" Vector__XXX
 SG_ BMS_numOfThermistors m89 : 38|5@1+ (1,0) [0|0] "" Vector__XXX
 SG_ BMS_shuntAsicCurrentOffset m84 : 38|15@1- (0.2,0) [0|0] "" Vector__XXX
 SG_ BMS_spmeBrick1SocUpperBound m50 : 38|10@1+ (0.1,0) [0|0] "" Vector__XXX
 SG_ BMS_cacMinUpdateAhError m22 : 39|9@1- (0.05,0) [0|0] "" Vector__XXX
 SG_ BMS_largestSyncCacErrorUpper m62 : 39|12@1+ (0.1,0) [0|0] "" Vector__XXX
 SG_ BMS_activeCoolCellTargetT m91 : 40|9@1+ (0.25,-25) [0|0] "" Vector__XXX
 SG_ BMS_brickBleedByAhTargetBrickId m36 : 40|7@1+ (1,1) [0|0] "" Vector__XXX
 SG_ BMS_brickBleedByVoltageTarget m35 : 40|16@1+ (0.0001,0) [0|0] "" Vector__XXX
 SG_ BMS_brickBleedChargeMinBrickId m34 : 40|7@1+ (1,1) [0|0] "" Vector__XXX
 SG_ BMS_brickBleedExcessChargeMinBrickId m37 : 40|7@1+ (1,1) [0|0] "" Vector__XXX
 SG_ BMS_cacAvgOffsetUpdateStartPointSocSpread m81 : 40|10@1+ (0.1,0) [0|0] "" Vector__XXX
 SG_ BMS_cacEndPointSocSpread m61 : 40|10@1+ (0.1,0) [0|0] "" Vector__XXX
 SG_ BMS_cacMinUpperBoundEst m1 : 40|13@1+ (0.1,0) [0|0] "" Vector__XXX
 SG_ BMS_cellAttributesPackManufacturingLocation m85 : 40|3@1+ (1,0) [0|0] "" Vector__XXX
 SG_ BMS_cumulativeBrickBleedTimeMaxBrickId m41 : 40|10@1+ (1,1) [0|0] "" Vector__XXX
 SG_ BMS_cumulativeBrickBleedTimeMinBrickId m40 : 40|10@1+ (1,1) [0|0] "" Vector__XXX
 SG_ BMS_energyChgWhWhPerDayTotalTime m28 : 40|24@1+ (0.05,0) [0|0] "" Vector__XXX
 SG_ BMS_energyDcChgWhWhPerDayTotalTime m29 : 40|24@1+ (0.05,0) [0|0] "" Vector__XXX
 SG_ BMS_idealEnergyRemainingBuffered m56 : 40|16@1+ (0.02,0) [0|0] "" Vector__XXX
 SG_ BMS_lifeModelThroughputCycleCount m80 : 40|12@1+ (1,0) [0|0] "" Vector__XXX
 SG_ BMS_lifeModelThroughputDcrTemperatureSeverityMax m78 : 40|7@1+ (0.1,0) [0|0] "" Vector__XXX
 SG_ BMS_minCapacityLossModuleId m38 : 40|5@1+ (1,1) [0|0] "" Vector__XXX
 SG_ BMS_pctTimeAtHighSoc m70 : 40|14@1+ (0.01,0) [0|0] "" Vector__XXX
 SG_ BMS_restingPointCacMin m66 : 40|12@1+ (0.1,0) [0|0] "" Vector__XXX
 SG_ BMS_shuntMeasurementSoloWakeCount m44 : 40|12@1+ (1,0) [0|0] "" Vector__XXX
 SG_ BMS_socByDvMaxBrickVoltage m90 : 40|12@1+ (0.002,0) [0|0] "" Vector__XXX
 SG_ BMS_synchronizedCacRawAverage m60 : 40|13@1+ (0.1,0) [0|0] "" Vector__XXX
 SG_ BMS_tempVsVoltageDcChgWeightedAvgTemp m69 : 40|14@1- (0.1,0) [0|0] "" Vector__XXX
 SG_ BMS_energyLowestDchBrickCac m87 : 41|13@1+ (0.1,0) [0|0] "" Vector__XXX
 SG_ BMS_estimatedCapacitySohEnergy m79 : 41|11@1+ (0.1,0) [0|0] "" Vector__XXX
 SG_ BMS_spmeAhDischargedAfterZero m48 : 41|16@1+ (0.1,0) [0|0] "" Vector__XXX
 SG_ BMS_largestSyncCacErrorEndSoc m71 : 42|10@1+ (0.1,0) [0|0] "" Vector__XXX
 SG_ BMS_runtimeSocMinCorrectionThresholdInDrive m72 : 42|10@1+ (0.1,0) [0|0] "" Vector__XXX
 SG_ BMS_socChangeSocByOcvMax m24 : 42|10@1+ (0.1,0) [0|0] "" Vector__XXX
 SG_ BMS_spmeBrick1CathodeBulkConcentration m49 : 42|10@1+ (0.001,0) [0|0] "" Vector__XXX
 SG_ BMS_cacMinAgedUpperBoundEst m58 : 43|13@1+ (0.1,0) [0|0] "" Vector__XXX
 SG_ BMS_cellAttributesRemanufacturedPack m85 : 43|1@1+ (1,0) [0|0] "" Vector__XXX
 SG_ BMS_numOfBricks m89 : 43|8@1+ (1,0) [0|0] "" Vector__XXX
 SG_ BMS_temperatureCondition m21 : 43|1@1+ (1,0) [0|0] "" Vector__XXX
 SG_ BMS_brick1SocCorrectionSpmeUpperBound m74 : 44|10@1+ (0.1,0) [0|0] "" Vector__XXX
 SG_ BMS_brick1SocCorrectionType m73 : 44|2@1+ (1,0) [0|0] "" Vector__XXX
 SG_ BMS_cacBlendPercentPerDayLowerBound m27 : 44|10@1+ (0.001,0) [0|0] "" Vector__XXX
 SG_ BMS_cacMax m0 : 44|13@1+ (0.1,0) [0|0] "" Vector__XXX
 SG_ BMS_cellAttributesConfigNvramValid m85 : 44|1@1+ (1,0) [0|0] "" Vector__XXX
 SG_ BMS_dSocMaxLowAlphaCounter m33 : 44|4@1+ (1,0) [0|0] "" Vector__XXX
 SG_ BMS_lifeModelAverageOffset m64 : 44|10@1- (0.1,0) [0|0] "" Vector__XXX
 SG_ BMS_sohTestEndMode m45 : 44|4@1+ (1,0) [0|0] "" Vector__XXX
 SG_ BMS_spmeBrick1ModelVsNominalSocOffset m51 : 44|11@1- (0.1,0) [0|0] "" Vector__XXX
 SG_ BMS_thmGradientSlope m21 : 44|10@1- (0.01,0) [0|0] "" Vector__XXX
 SG_ BMS_userChargeCalibratingReason m57 : 44|2@1+ (1,0) [0|0] "" Vector__XXX
 SG_ BMS_vChangeWindowMinBrickV m23 : 44|12@1+ (0.002,0) [0|0] "" Vector__XXX
 SG_ BMS_acRippleIsSupported m18 : 45|1@1+ (1,0) [0|0] "" Vector__XXX
 SG_ BMS_acRippleStartTemperatureMax m18 : 46|9@1+ (0.25,-25) [0|0] "" Vector__XXX
 SG_ BMS_lifeModelThroughputCapacityLoss m54 : 46|9@1+ (0.1,0) [0|0] "" Vector__XXX
 SG_ BMS_sohMinCacConfidenceBound m82 : 46|10@1+ (0.1,0) [0|0] "" Vector__XXX
 SG_ BMS_spmeMaxSocBestFitCost m53 : 46|12@1+ (1e-05,0) [0|0] "" Vector__XXX
 SG_ BMS_spmeMinSocBestFitCost m52 : 46|12@1+ (1e-05,0) [0|0] "" Vector__XXX
 SG_ BMS_vshResMaxIndex2 m25 : 46|6@1+ (1,0) [0|0] "" Vector__XXX
 SG_ BMS_vshResMinIndex3 m26 : 46|6@1+ (1,0) [0|0] "" Vector__XXX
 SG_ BMS_brickBleedByAhMinBrickId m36 : 47|7@1+ (1,1) [0|0] "" Vector__XXX
 SG_ BMS_brickBleedChargeMaxBrickId m34 : 47|7@1+ (1,1) [0|0] "" Vector__XXX
 SG_ BMS_brickBleedExcessChargeMaxBrickId m37 : 47|7@1+ (1,1) [0|0] "" Vector__XXX
 SG_ BMS_currentReg_targetI m4 : 47|11@1+ (0.5,0) [0|0] "" Vector__XXX
 SG_ BMS_powerVsVoltageChgEnergyWeightedAvgPower m68 : 47|9@1+ (0.01,0) [0|0] "" Vector__XXX
 SG_ BMS_avgShuntAsicCurrentOffset m83 : 48|15@1- (0.2,0) [0|0] "" Vector__XXX
 SG_ BMS_capacityImbalancePct m22 : 48|10@1+ (0.1,0) [0|0] "" Vector__XXX
 SG_ BMS_cellAttributesCellType m85 : 48|6@1+ (1,0) [0|0] "" Vector__XXX
 SG_ BMS_chargeTimeEstimate m86 : 48|14@1+ (0.1,0) [0|0] "" Vector__XXX
 SG_ BMS_dSocMinAlphaBrickID m33 : 48|7@1+ (1,1) [0|0] "" Vector__XXX
 SG_ BMS_dcrBlendingEnabled m43 : 48|1@1+ (1,0) [0|0] "" Vector__XXX
 SG_ BMS_energyReserveAvg m19 : 48|16@1+ (0.001,0) [0|0] "" Vector__XXX
 SG_ BMS_largestCacSpreadErrorUpper m63 : 48|12@1+ (0.1,0) [0|0] "" Vector__XXX
 SG_ BMS_latchedFullPackEnergyError m88 : 48|10@1- (0.1,0) [0|0] "" Vector__XXX
 SG_ BMS_lifeModelDcrGrowthPercent m55 : 48|14@1- (0.1,200) [0|0] "" Vector__XXX
 SG_ BMS_lifeModelThroughputDcrGrowthPercent m77 : 48|14@1- (0.1,200) [0|0] "" Vector__XXX
 SG_ BMS_maxCapacityLossModuleId m38 : 48|5@1+ (1,1) [0|0] "" Vector__XXX
 SG_ BMS_maxPossibleDcChargePower m2 : 48|8@1+ (1,0) [0|0] "" Vector__XXX
 SG_ BMS_maxSocChangeWindowed m73 : 48|11@1- (0.1,0) [0|0] "" Vector__XXX
 SG_ BMS_recentOvUvAlert m20 : 48|1@1+ (1,0) [0|0] "" Vector__XXX
 SG_ BMS_restingPointCacAvg m65 : 48|12@1+ (0.1,0) [0|0] "" Vector__XXX
 SG_ BMS_sohTestBlockReason m45 : 48|3@1+ (1,0) [0|0] "" Vector__XXX
 SG_ BMS_spmeBrick1BestFitCost m50 : 48|12@1+ (1e-05,0) [0|0] "" Vector__XXX
 SG_ BMS_stateOfHealthMinCacLowerBound m78 : 48|13@1+ (0.1,0) [0|0] "" Vector__XXX
 SG_ BMS_unexpectedLossOfLvCounter m57 : 48|6@1+ (1,0) [0|0] "" Vector__XXX
 SG_ BMS_vshTestMinDeltaVBrickID m3 : 48|7@1+ (1,1) [0|0] "" Vector__XXX
 SG_ BMS_1kHzTask_maxExecTime m8 : 49|11@1+ (1,0) [0|0] "" Vector__XXX
 SG_ BMS_cellTempTargetMode m91 : 49|4@1+ (1,0) [0|0] "" Vector__XXX
 SG_ BMS_dcrBlendFactorPerCycle m43 : 49|10@1+ (0.001,0) [0|0] "" Vector__XXX
 SG_ BMS_recentIsoAlert m20 : 49|1@1+ (1,0) [0|0] "" Vector__XXX
 SG_ BMS_cacAvgAgedRawEstimate m59 : 50|13@1+ (0.1,0) [0|0] "" Vector__XXX
 SG_ BMS_cacAvgOffsetUpdateEndPointSocSpread m81 : 50|10@1+ (0.1,0) [0|0] "" Vector__XXX
 SG_ BMS_cacTransitionBlendOffset m40 : 50|10@1- (0.1,0) [0|0] "" Vector__XXX
 SG_ BMS_cacUpdateDeltaSocByAhSpread m61 : 50|11@1- (0.01,0) [0|0] "" Vector__XXX
 SG_ BMS_dSocMinAlphaSocBleedMargin m41 : 50|12@1+ (0.0030517578125,0) [0|0] "" Vector__XXX
 SG_ BMS_maxSpreadChangeSocStart m75 : 50|10@1+ (0.1,0) [0|0] "" Vector__XXX
 SG_ BMS_negCtrDeviationConfidenceMax m14 : 50|13@1+ (0.000122100107192,0) [0|0] "" Vector__XXX
 SG_ BMS_negCtrDeviationFiltConfMax m15 : 50|13@1+ (0.000122100107192,0) [0|0] "" Vector__XXX
 SG_ BMS_negCtrDropCorrectedFiltMax m16 : 50|13@1- (0.001221299164314,0) [0|0] "" Vector__XXX
 SG_ BMS_negCtrOffsetErrorConf m17 : 50|13@1+ (0.000122100107192,0) [0|0] "" Vector__XXX
 SG_ BMS_negCtrResistanceConfidence m9 : 50|13@1+ (12.21001071916841,0) [0|0] "" Vector__XXX
 SG_ BMS_posCtrDeviationConfidenceMax m10 : 50|13@1+ (0.000122100107192,0) [0|0] "" Vector__XXX
 SG_ BMS_posCtrDeviationFiltConfMax m11 : 50|13@1+ (0.000122100107192,0) [0|0] "" Vector__XXX
 SG_ BMS_posCtrDropCorrectedFiltMax m12 : 50|13@1- (0.001221299164314,0) [0|0] "" Vector__XXX
 SG_ BMS_posCtrOffsetErrorConf m13 : 50|13@1+ (0.000122100107192,0) [0|0] "" Vector__XXX
 SG_ BMS_recentBmbMiaAlert m20 : 50|1@1+ (1,0) [0|0] "" Vector__XXX
 SG_ BMS_rubberBandingConfigDischargeTargetPct m76 : 50|10@1+ (0.1,0) [0|0] "" Vector__XXX
 SG_ BMS_socTopVsSocBtmDchWeightedAvgDepthOfDischarge m46 : 50|14@1+ (0.01,0) [0|0] "" Vector__XXX
 SG_ BMS_cacBlendingConfigNvramValid m20 : 51|1@1+ (1,0) [0|0] "" Vector__XXX
 SG_ BMS_cellChargeDcCurrentLimit m89 : 51|12@1+ (0.5,0) [0|0] "" Vector__XXX
 SG_ BMS_largestSyncCacErrorLower m62 : 51|12@1+ (0.1,0) [0|0] "" Vector__XXX
 SG_ BMS_lowCurrentInterruptionReason m45 : 51|2@1+ (1,0) [0|0] "" Vector__XXX
 SG_ BMS_cacBlendingEnabled m20 : 52|1@1+ (1,0) [0|0] "" Vector__XXX
 SG_ BMS_dSocNoiseMargin m24 : 52|10@1+ (0.0030517578125,0) [0|0] "" Vector__XXX
 SG_ BMS_lifeModelThroughputDcrCycleCount m80 : 52|12@1+ (1,0) [0|0] "" Vector__XXX
 SG_ BMS_prevUserFacingSohEnergy m79 : 52|11@1+ (0.1,0) [0|0] "" Vector__XXX
 SG_ BMS_restingPointCacBrick1 m66 : 52|12@1+ (0.1,0) [0|0] "" Vector__XXX
 SG_ BMS_runtimeSocConfigNvramValid m71 : 52|1@1+ (1,0) [0|0] "" Vector__XXX
 SG_ BMS_runtimeSocElectrolyteVoltageResetThreshold m72 : 52|10@1- (0.001,-0.5) [0|0] "" Vector__XXX
 SG_ BMS_soloWakeCount m44 : 52|12@1+ (1,0) [0|0] "" Vector__XXX
 SG_ BMS_spmeBrick1CathodeSurfaceConcentration m49 : 52|10@1+ (0.001,0) [0|0] "" Vector__XXX
 SG_ BMS_vshResMax2 m25 : 52|12@1+ (0.002,0) [0|0] "" Vector__XXX
 SG_ BMS_vshResMin3 m26 : 52|12@1+ (0.002,0) [0|0] "" Vector__XXX
 SG_ BMS_cacBlendPercentPerCycle m20 : 53|10@1+ (0.001,0) [0|0] "" Vector__XXX
 SG_ BMS_cacImbalanceCurrentAdjustmentPct m38 : 53|10@1+ (0.1,0) [0|0] "" Vector__XXX
 SG_ BMS_cacMaxKalmanError m1 : 53|10@1+ (0.01,0) [0|0] "" Vector__XXX
 SG_ BMS_diNodeModelTemp m60 : 53|11@1+ (0.1,-50) [0|0] "" Vector__XXX
 SG_ BMS_lowCurrentInterruptionCurrent m45 : 53|9@1- (0.1,0) [0|0] "" Vector__XXX
 SG_ BMS_runtimeSocCorrectionsEnabled m71 : 53|1@1+ (1,0) [0|0] "" Vector__XXX
 SG_ BMS_shuntOffsetCalibrationTemp m84 : 53|11@1- (0.05,0) [0|0] "" Vector__XXX
 SG_ BMS_acRippleMaxSocAllowed m36 : 54|10@1+ (0.1,0) [0|0] "" Vector__XXX
 SG_ BMS_acRippleMinSocAllowed m37 : 54|10@1+ (0.1,0) [0|0] "" Vector__XXX
 SG_ BMS_brick1SocCorrectionSpmeLowerBound m74 : 54|10@1+ (0.1,0) [0|0] "" Vector__XXX
 SG_ BMS_cacBlendPercentPerDayUpperBound m27 : 54|10@1+ (0.001,0) [0|0] "" Vector__XXX
 SG_ BMS_cellAttributesAutocloseAndScrapPackOnFieldReturn m85 : 54|1@1+ (1,0) [0|0] "" Vector__XXX
 SG_ BMS_continuousDcrBlendFactor m34 : 54|10@1+ (0.001,0) [0|0] "" Vector__XXX
 SG_ BMS_dcrBlendFactorPerDayUpperBound m57 : 54|10@1+ (0.001,0) [0|0] "" Vector__XXX
 SG_ BMS_energyChargeSocTarget m87 : 54|10@1+ (0.1,0) [0|0] "" Vector__XXX
 SG_ BMS_percentCacUpdatesInTimeWindow m64 : 54|10@1+ (0.1,0) [0|0] "" Vector__XXX
 SG_ BMS_rubberBandingEnabled m71 : 54|1@1+ (1,0) [0|0] "" Vector__XXX
 SG_ BMS_acRippleStartTemperatureMin m18 : 55|9@1+ (0.25,-25) [0|0] "" Vector__XXX
 SG_ BMS_cellAttributesShipPackForFailureAnalysis m85 : 55|1@1+ (1,0) [0|0] "" Vector__XXX
 SG_ BMS_dSocCacMargin m33 : 55|9@1+ (0.0030517578125,0) [0|0] "" Vector__XXX
 SG_ BMS_passiveCoolCellTargetT m54 : 55|9@1+ (0.25,-25) [0|0] "" Vector__XXX
 SG_ BMS_rubberBandingConfigNvramValid m71 : 55|1@1+ (1,0) [0|0] "" Vector__XXX
 SG_ BMS_spmeInitCountSinceReset m51 : 55|8@1+ (1,0) [0|0] "" Vector__XXX
 SG_ BMS_brickBleedByVoltageTargetBrickId m35 : 56|7@1+ (1,1) [0|0] "" Vector__XXX
 SG_ BMS_cacNvramEstimationSource m2 : 56|2@1+ (1,0) [0|0] "" Vector__XXX
 SG_ BMS_largestSynchronizedCacErrorPct m56 : 56|8@1+ (0.1,0) [0|0] "" Vector__XXX
 SG_ BMS_minPackTempForChargeToStart m91 : 56|7@1+ (0.5,-40) [0|0] "" Vector__XXX
 SG_ BMS_numBricksRestingForCac m58 : 56|8@1+ (1,0) [0|0] "" Vector__XXX
 SG_ BMS_peakRegenCurrentLimitMode m3 : 56|4@1+ (1,0) [0|0] "" Vector__XXX
 SG_ BMS_powerVsVoltageChgEnergyWeightedAvgVoltage m68 : 56|8@1+ (0.01,2) [0|0] "" Vector__XXX
 SG_ BMS_runtimeSocMinTempForModel m71 : 56|6@1+ (0.5,0) [0|0] "" Vector__XXX
 SG_ BMS_socByDvMaxBrickId m90 : 56|8@1+ (1,1) [0|0] "" Vector__XXX
 SG_ BMS_socImbalancePct m82 : 56|8@1+ (0.1,0) [0|0] "" Vector__XXX
 SG_ BMS_tempVsVoltageDcChgWeightedAvgVoltage m69 : 56|8@1+ (0.01,2) [0|0] "" Vector__XXX
 SG_ BMS_thmGradient m21 : 56|8@1+ (0.1,0) [0|0] "" Vector__XXX
 SG_ BMS_vChangeWindowTimeAfterWake m23 : 56|7@1+ (0.1,0) [0|0] "" Vector__XXX
 SG_ BMS_cacMaxBrickId m0 : 57|7@1+ (1,1) [0|0] "" Vector__XXX
 SG_ BMS_histogramStartTimeIrrational m30 : 57|1@1+ (1,0) [0|0] "" Vector__XXX
 SG_ BMS_lifeModelOutputsAreTrustworthy m31 : 57|1@1+ (1,0) [0|0] "" Vector__XXX
 SG_ BMS_spmeLastReInitReason m48 : 57|2@1+ (1,0) [0|0] "" Vector__XXX
 SG_ BMS_cpUserChargeStatus m4 : 58|3@1+ (1,0) [0|0] "" Vector__XXX
 SG_ BMS_histogramDischargeThroughputIrrational m30 : 58|1@1+ (1,0) [0|0] "" Vector__XXX
 SG_ BMS_hvChainConfig m2 : 58|3@1+ (1,0) [0|0] "" Vector__XXX
 SG_ BMS_packCalibrationBirthDateBinnedValid m67 : 58|1@1+ (1,0) [0|0] "" Vector__XXX
 SG_ BMS_spmeMaxSocLowestCostIndex m53 : 58|4@1+ (1,0) [0|0] "" Vector__XXX
 SG_ BMS_spmeMinSocLowestCostIndex m52 : 58|4@1+ (1,0) [0|0] "" Vector__XXX
 SG_ BMS_histogramChargeThroughputIrrational m30 : 59|1@1+ (1,0) [0|0] "" Vector__XXX
 SG_ BMS_maxSocCorrectionTypeWindowed m73 : 59|2@1+ (1,0) [0|0] "" Vector__XXX
 SG_ BMS_cacEstimationSource m65 : 60|2@1+ (1,0) [0|0] "" Vector__XXX
 SG_ BMS_histogramTotalTimeIrrational m30 : 60|1@1+ (1,0) [0|0] "" Vector__XXX
 SG_ BMS_lifeModelNvramIsValid m63 : 60|1@1+ (1,0) [0|0] "" Vector__XXX
 SG_ BMS_spmeBrick1LowestCostIndex m50 : 60|4@1+ (1,0) [0|0] "" Vector__XXX
 SG_ BMS_histogramStorageDataIsLow m30 : 61|1@1+ (1,0) [0|0] "" Vector__XXX
 SG_ BMS_sampleChargePower m4 : 61|1@1+ (1,0) [0|0] "" Vector__XXX
 SG_ BMS_energyBufferConfigNvramValid m71 : 62|1@1+ (1,0) [0|0] "" Vector__XXX
 SG_ BMS_histogramTemperatureIrrational m30 : 62|1@1+ (1,0) [0|0] "" Vector__XXX
 SG_ BMS_spmeMaxBrickValidForCorrection m53 : 62|1@1+ (1,0) [0|0] "" Vector__XXX
 SG_ BMS_spmeMinBrickValidForCorrection m52 : 62|1@1+ (1,0) [0|0] "" Vector__XXX
 SG_ BMS_cacAgedMinRawIsValid m1 : 63|1@1+ (1,0) [0|0] "" Vector__XXX
 SG_ BMS_spmeBrick1ValidForCorrection m51 : 63|1@1+ (1,0) [0|0] "" Vector__XXX
 SG_ BMS_thermalEvent1pDetectConfigDisabled m71 : 63|1@1+ (1,0) [0|0] "" Vector__XXX
 SG_ BMS_vChangeWindowChangeIsOutlier m23 : 63|1@1+ (1,0) [0|0] "" Vector__XXX

BO_ 947 UI_vehicleControl2: 8 Vector__XXX
 SG_ UI_gloveboxRequest : 0|1@1+ (1,0) [0|0] "" Vector__XXX
 SG_ UI_trunkRequest : 1|1@1+ (1,0) [0|0] "" Vector__XXX
 SG_ UI_UMCUpdateInhibit : 2|1@1+ (1,0) [0|0] "" Vector__XXX
 SG_ UI_WCUpdateInhibit : 3|1@1+ (1,0) [0|0] "" Vector__XXX
 SG_ UI_soundHornOnLock : 4|1@1+ (1,0) [0|0] "" Vector__XXX
 SG_ UI_locksPanelActive : 5|1@1+ (1,0) [0|0] "" Vector__XXX
 SG_ UI_PINToDriveEnabled : 6|1@1+ (1,0) [0|0] "" Vector__XXX
 SG_ UI_PINToDrivePassed : 7|1@1+ (1,0) [0|0] "" Vector__XXX
 SG_ UI_disableMirrorAutoDim : 8|1@1+ (1,0) [0|0] "" Vector__XXX
 SG_ UI_lightSwitch : 9|3@1+ (1,0) [0|0] "" Vector__XXX
 SG_ UI_readyToAddKey : 12|1@1+ (1,0) [0|0] "" Vector__XXX
 SG_ UI_alarmTriggerRequest : 13|1@1+ (1,0) [0|0] "" Vector__XXX
 SG_ UI_VCSECFeature1 : 14|1@1+ (1,0) [0|0] "" Vector__XXX
 SG_ UI_VCLEFTFeature1 : 15|1@1+ (1,0) [0|0] "" Vector__XXX
 SG_ UI_summonState : 16|2@1+ (1,0) [0|0] "" Vector__XXX
 SG_ UI_displayOnForUser : 18|1@1+ (1,0) [0|0] "" Vector__XXX
 SG_ UI_freeRollModeRequest : 19|1@1+ (1,0) [0|0] "" Vector__XXX
 SG_ UI_BLEPushNotificationRequest : 20|1@1+ (1,0) [0|0] "" Vector__XXX
 SG_ UI_pairKeyQRCodeDisplaying : 21|1@1+ (1,0) [0|0] "" Vector__XXX
 SG_ UI_keepAutopilotAwake : 22|1@1+ (1,0) [0|0] "" Vector__XXX
 SG_ UI_batteryPreconditioningRequest : 23|1@1+ (1,0) [0|0] "" Vector__XXX
 SG_ UI_coastDownMode : 24|1@1+ (1,0) [0|0] "" Vector__XXX
 SG_ UI_autopilotPowerStateRequest : 25|2@1+ (1,0) [0|0] "" Vector__XXX
 SG_ UI_shorted12VCellTestMode : 27|2@1+ (1,0) [0|0] "" Vector__XXX
 SG_ UI_autoRollWindowsOnLockEnable : 29|1@1+ (1,0) [0|0] "" Vector__XXX
 SG_ UI_virtualPitchSensorOverrideOKForAim : 30|1@1+ (1,0) [0|0] "" Vector__XXX
 SG_ UI_conditionalLoggingEnabledVCSEC : 31|1@1+ (1,0) [0|0] "" Vector__XXX
 SG_ UI_WC3UpdateInhibit : 32|1@1+ (1,0) [0|0] "" Vector__XXX
 SG_ UI_steeringWheelHeatReq : 33|1@1+ (1,0) [0|0] "" Vector__XXX
 SG_ UI_disableHorn : 34|1@1+ (1,0) [0|0] "" Vector__XXX
 SG_ UI_frontRightSeatAutoClimateReq : 39|1@1+ (1,0) [0|0] "" Vector__XXX
 SG_ UI_sleepFeature1 : 51|1@1+ (1,0) [0|0] "" Vector__XXX
 SG_ UI_dcr12VThreshold : 52|4@1+ (1,0) [0|0] "" Vector__XXX
 SG_ UI_frontLeftSeatAutoClimateReq : 56|1@1+ (1,0) [0|0] "" Vector__XXX
 SG_ UI_wiperHeaterReq : 57|1@1+ (1,0) [0|0] "" Vector__XXX
 SG_ UI_tireSeason : 59|1@1+ (1,0) [0|0] "" Vector__XXX
 SG_ UI_saveTireConfigReq : 60|1@1+ (1,0) [0|0] "" Vector__XXX
 SG_ UI_silentAlarm : 61|1@1+ (1,0) [0|0] "" Vector__XXX
 SG_ UI_sleepFeature2 : 63|1@1+ (1,0) [0|0] "" Vector__XXX

BO_ 949 DIR_alertMatrix2: 8 Vector__XXX
 SG_ DIR_a065_canHardwareBusB : 0|1@1+ (1,0) [0|0] "" Vector__XXX
 SG_ DIR_a066_canDataBusB : 1|1@1+ (1,0) [0|0] "" Vector__XXX
 SG_ DIR_a067_canOverrunBusB : 2|1@1+ (1,0) [0|0] "" Vector__XXX
 SG_ DIR_a069_rotorTempLimit : 4|1@1+ (1,0) [0|0] "" Vector__XXX
 SG_ DIR_a070_udsTransactionInitiated : 5|1@1+ (1,0) [0|0] "" Vector__XXX
 SG_ DIR_a071_busDisconnected : 6|1@1+ (1,0) [0|0] "" Vector__XXX
 SG_ DIR_a072_gateDriveFaultCounter : 7|1@1+ (1,0) [0|0] "" Vector__XXX
 SG_ DIR_a073_motorSpeed : 8|1@1+ (1,0) [0|0] "" Vector__XXX
 SG_ DIR_a074_motorEncoder : 9|1@1+ (1,0) [0|0] "" Vector__XXX
 SG_ DIR_a075_motorSpeedMismatch : 10|1@1+ (1,0) [0|0] "" Vector__XXX
 SG_ DIR_a076_lvSupplyOV : 11|1@1+ (1,0) [0|0] "" Vector__XXX
 SG_ DIR_a077_lvSupplyUV : 12|1@1+ (1,0) [0|0] "" Vector__XXX
 SG_ DIR_a078_adcRefLow : 13|1@1+ (1,0) [0|0] "" Vector__XXX
 SG_ DIR_a079_adcRefHigh : 14|1@1+ (1,0) [0|0] "" Vector__XXX
 SG_ DIR_a084_eccTestData0 : 19|1@1+ (1,0) [0|0] "" Vector__XXX
 SG_ DIR_a086_activeDischargeOn : 21|1@1+ (1,0) [0|0] "" Vector__XXX
 SG_ DIR_a087_gtwMIA : 22|1@1+ (1,0) [0|0] "" Vector__XXX
 SG_ DIR_a088_uiMIA : 23|1@1+ (1,0) [0|0] "" Vector__XXX
 SG_ DIR_a090_pmMIA : 25|1@1+ (1,0) [0|0] "" Vector__XXX
 SG_ DIR_a091_espMIA : 26|1@1+ (1,0) [0|0] "" Vector__XXX
 SG_ DIR_a092_bmsMIA : 27|1@1+ (1,0) [0|0] "" Vector__XXX
 SG_ DIR_a093_canHardwareBusA : 28|1@1+ (1,0) [0|0] "" Vector__XXX
 SG_ DIR_a094_canDataBusA : 29|1@1+ (1,0) [0|0] "" Vector__XXX
 SG_ DIR_a095_canOverrunBusA : 30|1@1+ (1,0) [0|0] "" Vector__XXX
 SG_ DIR_a096_memoryError : 31|1@1+ (1,0) [0|0] "" Vector__XXX
 SG_ DIR_a097_eepromError : 32|1@1+ (1,0) [0|0] "" Vector__XXX
 SG_ DIR_a098_intTimeTooLong : 33|1@1+ (1,0) [0|0] "" Vector__XXX
 SG_ DIR_a099_threadOverrun : 34|1@1+ (1,0) [0|0] "" Vector__XXX
 SG_ DIR_a100_assertion : 35|1@1+ (1,0) [0|0] "" Vector__XXX
 SG_ DIR_a101_eccTestData1 : 36|1@1+ (1,0) [0|0] "" Vector__XXX
 SG_ DIR_a103_lowFlow : 38|1@1+ (1,0) [0|0] "" Vector__XXX
 SG_ DIR_a107_fpgaError : 42|1@1+ (1,0) [0|0] "" Vector__XXX
 SG_ DIR_a108_stateTrans : 43|1@1+ (1,0) [0|0] "" Vector__XXX
 SG_ DIR_a110_brakeMIA : 45|1@1+ (1,0) [0|0] "" Vector__XXX
 SG_ DIR_a111_badPhaseSensorCalib : 46|1@1+ (1,0) [0|0] "" Vector__XXX
 SG_ DIR_a112_noPhaseCurrent : 47|1@1+ (1,0) [0|0] "" Vector__XXX
 SG_ DIR_a113_noFuncHeatsinkSensor : 48|1@1+ (1,0) [0|0] "" Vector__XXX
 SG_ DIR_a117_diMIA : 52|1@1+ (1,0) [0|0] "" Vector__XXX
 SG_ DIR_a119_hvpMIA : 54|1@1+ (1,0) [0|0] "" Vector__XXX
 SG_ DIR_a120_hvlinkMIA : 55|1@1+ (1,0) [0|0] "" Vector__XXX
 SG_ DIR_a121_motorControlRegulation : 56|1@1+ (1,0) [0|0] "" Vector__XXX
 SG_ DIR_a122_highStackUsage : 57|1@1+ (1,0) [0|0] "" Vector__XXX
 SG_ DIR_a123_lossMotorControl : 58|1@1+ (1,0) [0|0] "" Vector__XXX
 SG_ DIR_a126_limpMode : 61|1@1+ (1,0) [0|0] "" Vector__XXX
 SG_ DIR_a127_gracefulPowerOff : 62|1@1+ (1,0) [0|0] "" Vector__XXX
 SG_ DIR_a128_fpgaVersionMismatch : 63|1@1+ (1,0) [0|0] "" Vector__XXX

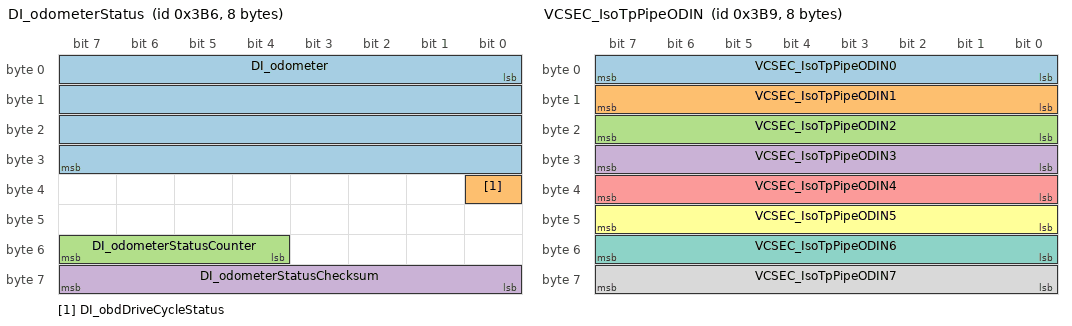
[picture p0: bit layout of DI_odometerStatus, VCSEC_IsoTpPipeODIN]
BO_ 950 DI_odometerStatus: 8 Vector__XXX
 SG_ DI_odometer : 0|32@1+ (0.001,0) [0|0] "" Vector__XXX
 SG_ DI_obdDriveCycleStatus : 32|1@1+ (1,0) [0|0] "" Vector__XXX
 SG_ DI_odometerStatusCounter : 52|4@1+ (1,0) [0|0] "" Vector__XXX
 SG_ DI_odometerStatusChecksum : 56|8@1+ (1,0) [0|0] "" Vector__XXX

BO_ 953 VCSEC_IsoTpPipeODIN: 8 Vector__XXX
 SG_ VCSEC_IsoTpPipeODIN0 : 0|8@1+ (1,0) [0|0] "" Vector__XXX
 SG_ VCSEC_IsoTpPipeODIN1 : 8|8@1+ (1,0) [0|0] "" Vector__XXX
 SG_ VCSEC_IsoTpPipeODIN2 : 16|8@1+ (1,0) [0|0] "" Vector__XXX
 SG_ VCSEC_IsoTpPipeODIN3 : 24|8@1+ (1,0) [0|0] "" Vector__XXX
 SG_ VCSEC_IsoTpPipeODIN4 : 32|8@1+ (1,0) [0|0] "" Vector__XXX
 SG_ VCSEC_IsoTpPipeODIN5 : 40|8@1+ (1,0) [0|0] "" Vector__XXX
 SG_ VCSEC_IsoTpPipeODIN6 : 48|8@1+ (1,0) [0|0] "" Vector__XXX
 SG_ VCSEC_IsoTpPipeODIN7 : 56|8@1+ (1,0) [0|0] "" Vector__XXX

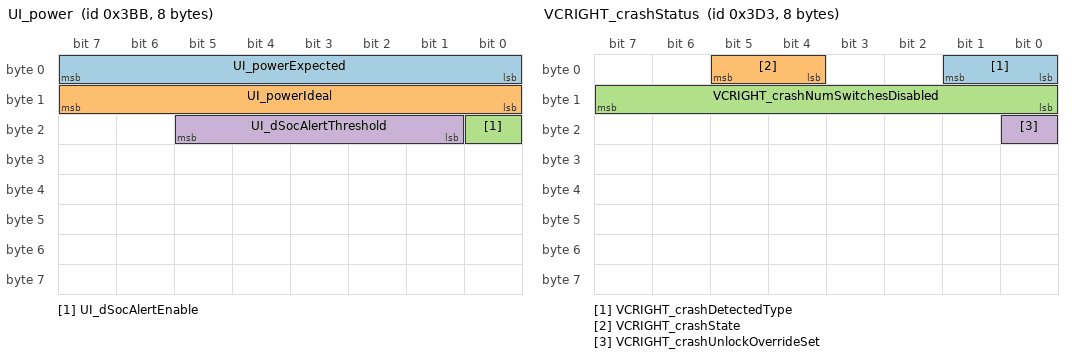
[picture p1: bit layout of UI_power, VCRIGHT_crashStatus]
BO_ 955 UI_power: 8 Vector__XXX
 SG_ UI_powerExpected : 0|8@1+ (1,0) [0|0] "" Vector__XXX
 SG_ UI_powerIdeal : 8|8@1+ (1,0) [0|0] "" Vector__XXX
 SG_ UI_dSocAlertEnable : 16|1@1+ (1,0) [0|0] "" Vector__XXX
 SG_ UI_dSocAlertThreshold : 17|5@1+ (0.1,-3) [0|0] "" Vector__XXX

BO_ 956 UI_tpmsRCPsetting: 8 Vector__XXX
 SG_ UI_setRCPFront : 16|8@1+ (0.025,0) [0|0] "" Vector__XXX
 SG_ UI_setRCPRear : 24|8@1+ (0.025,0) [0|0] "" Vector__XXX

BO_ 957 VCFRONT_parkedEnergyLoss: 8 Vector__XXX
 SG_ VCFRONT_energyLossIndex M : 0|3@1+ (1,0) [0|0] "" Vector__XXX
 SG_ VCFRONT_parkedEnergyLossState m0 : 3|3@1+ (1,0) [0|0] "" Vector__XXX
 SG_ VCFRONT_currentEnergyLossReason m0 : 8|3@1+ (1,0) [0|0] "" Vector__XXX
 SG_ VCFRONT_summonStandbyEnergyLossSinceCharge m4 : 8|14@1+ (0.01,0) [0|0] "" Vector__XXX
 SG_ VCFRONT_summonStandbyEnergyLossSinceDrive m2 : 8|14@1+ (0.01,0) [0|0] "" Vector__XXX
 SG_ VCFRONT_userEnergyLossSinceCharge m3 : 8|14@1+ (0.01,0) [0|0] "" Vector__XXX
 SG_ VCFRONT_userEnergyLossSinceDrive m1 : 8|14@1+ (0.01,0) [0|0] "" Vector__XXX
 SG_ VCFRONT_preconditioningEnergyLossSinceCharge m3 : 22|14@1+ (0.01,0) [0|0] "" Vector__XXX
 SG_ VCFRONT_preconditioningEnergyLossSinceDrive m1 : 22|14@1+ (0.01,0) [0|0] "" Vector__XXX
 SG_ VCFRONT_sentryModeEnergyLossSinceCharge m4 : 22|14@1+ (0.01,0) [0|0] "" Vector__XXX
 SG_ VCFRONT_sentryModeEnergyLossSinceDrive m2 : 22|14@1+ (0.01,0) [0|0] "" Vector__XXX
 SG_ VCFRONT_backgroundEnergyLossSinceCharge m4 : 36|14@1+ (0.01,0) [0|0] "" Vector__XXX
 SG_ VCFRONT_backgroundEnergyLossSinceDrive m2 : 36|14@1+ (0.01,0) [0|0] "" Vector__XXX
 SG_ VCFRONT_cabinOverheatEnergyLossSinceCharge m3 : 36|14@1+ (0.01,0) [0|0] "" Vector__XXX
 SG_ VCFRONT_cabinOverheatEnergyLossSinceDrive m1 : 36|14@1+ (0.01,0) [0|0] "" Vector__XXX
 SG_ VCFRONT_evapDryingEnergyLossSinceCharge m4 : 50|14@1+ (0.01,0) [0|0] "" Vector__XXX
 SG_ VCFRONT_evapDryingEnergyLossSinceDrive m2 : 50|14@1+ (0.01,0) [0|0] "" Vector__XXX
 SG_ VCFRONT_mobileAppEnergyLossSinceCharge m3 : 50|14@1+ (0.01,0) [0|0] "" Vector__XXX
 SG_ VCFRONT_mobileAppEnergyLossSinceDrive m1 : 50|14@1+ (0.01,0) [0|0] "" Vector__XXX

BO_ 958 FC_alertMatrix5: 8 Vector__XXX
 SG_ FC_a257_GB_bmsMia : 0|1@1+ (1,0) [0|0] "" Vector__XXX
 SG_ FC_a258_GB_evseMia : 1|1@1+ (1,0) [0|0] "" Vector__XXX
 SG_ FC_a259_GB_vehTxBufOvf : 2|1@1+ (1,0) [0|0] "" Vector__XXX
 SG_ FC_a260_GB_vehRxBufOvf : 3|1@1+ (1,0) [0|0] "" Vector__XXX
 SG_ FC_a261_GB_evseTxBufOvf : 4|1@1+ (1,0) [0|0] "" Vector__XXX
 SG_ FC_a262_GB_evseRxBufOvf : 5|1@1+ (1,0) [0|0] "" Vector__XXX
 SG_ FC_a263_GB_hwProxTrip : 6|1@1+ (1,0) [0|0] "" Vector__XXX
 SG_ FC_a264_GB_timeoutCHM : 7|1@1+ (1,0) [0|0] "" Vector__XXX
 SG_ FC_a265_GB_bmsIncompatible : 8|1@1+ (1,0) [0|0] "" Vector__XXX
 SG_ FC_a266_GB_negPin_OT : 9|1@1+ (1,0) [0|0] "" Vector__XXX
 SG_ FC_a267_GB_posPin_OT : 10|1@1+ (1,0) [0|0] "" Vector__XXX
 SG_ FC_a268_GB_pcb_OT : 11|1@1+ (1,0) [0|0] "" Vector__XXX
 SG_ FC_a269_GB_timeoutCRM : 12|1@1+ (1,0) [0|0] "" Vector__XXX
 SG_ FC_a270_GB_timeoutCML : 13|1@1+ (1,0) [0|0] "" Vector__XXX
 SG_ FC_a271_GB_timeoutCRO : 14|1@1+ (1,0) [0|0] "" Vector__XXX
 SG_ FC_a272_GB_negToPosDeltaHi : 15|1@1+ (1,0) [0|0] "" Vector__XXX
 SG_ FC_a273_GB_negToPosDeltaLo : 16|1@1+ (1,0) [0|0] "" Vector__XXX
 SG_ FC_a274_GB_negToPcbDeltaHi : 17|1@1+ (1,0) [0|0] "" Vector__XXX
 SG_ FC_a275_GB_posToPcbDeltaHi : 18|1@1+ (1,0) [0|0] "" Vector__XXX
 SG_ FC_a276_GB_negToPcbDeltaLo : 19|1@1+ (1,0) [0|0] "" Vector__XXX
 SG_ FC_a277_GB_posToPcbDeltaLo : 20|1@1+ (1,0) [0|0] "" Vector__XXX
 SG_ FC_a278_GB_timeoutCCS : 21|1@1+ (1,0) [0|0] "" Vector__XXX
 SG_ FC_a279_GB_evseOverCurrent : 22|1@1+ (1,0) [0|0] "" Vector__XXX
 SG_ FC_a280_GB_retryLimitExceeded : 23|1@1+ (1,0) [0|0] "" Vector__XXX
 SG_ FC_a281_GB_evseOutOfService : 24|1@1+ (1,0) [0|0] "" Vector__XXX
 SG_ FC_a282_GB_negTempHiFoldBk : 25|1@1+ (1,0) [0|0] "" Vector__XXX
 SG_ FC_a283_GB_posTempHiFoldBk : 26|1@1+ (1,0) [0|0] "" Vector__XXX
 SG_ FC_a284_GB_pcbTempHiFoldBk : 27|1@1+ (1,0) [0|0] "" Vector__XXX
 SG_ FC_a285_GB_proxDisconnected : 28|1@1+ (1,0) [0|0] "" Vector__XXX
 SG_ FC_a286_GB_evseConnUnlocked : 29|1@1+ (1,0) [0|0] "" Vector__XXX
 SG_ FC_a287_GB_vehConnUnlocked : 30|1@1+ (1,0) [0|0] "" Vector__XXX
 SG_ FC_a288_GB_evseAbnormalStopReq : 31|1@1+ (1,0) [0|0] "" Vector__XXX
 SG_ FC_a289_GB_proxTimeout : 32|1@1+ (1,0) [0|0] "" Vector__XXX
 SG_ FC_a290_GB_pilotAcceptTimeout : 33|1@1+ (1,0) [0|0] "" Vector__XXX
 SG_ FC_a291_GB_vehDataTimeout : 34|1@1+ (1,0) [0|0] "" Vector__XXX
 SG_ FC_a292_GB_vehConLockTimeout : 35|1@1+ (1,0) [0|0] "" Vector__XXX
 SG_ FC_a293_GB_proxRationality : 36|1@1+ (1,0) [0|0] "" Vector__XXX
 SG_ FC_a294_GB_unused : 37|1@1+ (1,0) [0|0] "" Vector__XXX
 SG_ FC_a295_GB_pilotRationality : 38|1@1+ (1,0) [0|0] "" Vector__XXX
 SG_ FC_a296_GB_invalidPilotTransitio : 39|1@1+ (1,0) [0|0] "" Vector__XXX
 SG_ FC_a297_GB_unused : 40|1@1+ (1,0) [0|0] "" Vector__XXX
 SG_ FC_a298_GB_bmsCtrCloseTimeout : 41|1@1+ (1,0) [0|0] "" Vector__XXX
 SG_ FC_a299_GB_evseReadyTimeout : 42|1@1+ (1,0) [0|0] "" Vector__XXX
 SG_ FC_a300_GB_unused : 43|1@1+ (1,0) [0|0] "" Vector__XXX
 SG_ FC_a301_GB_unused : 44|1@1+ (1,0) [0|0] "" Vector__XXX
 SG_ FC_a302_GB_unused : 45|1@1+ (1,0) [0|0] "" Vector__XXX
 SG_ FC_a303_GB_negRecogTimeout : 46|1@1+ (1,0) [0|0] "" Vector__XXX
 SG_ FC_a304_GB_unused : 47|1@1+ (1,0) [0|0] "" Vector__XXX
 SG_ FC_a305_GB_posRecogTimeout : 48|1@1+ (1,0) [0|0] "" Vector__XXX
 SG_ FC_a306_GB_vehReadyDeasserted : 49|1@1+ (1,0) [0|0] "" Vector__XXX
 SG_ FC_a307_GB_fcContOpenTimeout : 50|1@1+ (1,0) [0|0] "" Vector__XXX
 SG_ FC_a308_GB_evseConLockTimeout : 51|1@1+ (1,0) [0|0] "" Vector__XXX
 SG_ FC_a309_GB_unused : 52|1@1+ (1,0) [0|0] "" Vector__XXX
 SG_ FC_a310_GB_unused : 53|1@1+ (1,0) [0|0] "" Vector__XXX
 SG_ FC_a311_GB_battParamsTimeout : 54|1@1+ (1,0) [0|0] "" Vector__XXX
 SG_ FC_a312_GB_evseLimitsTimeout : 55|1@1+ (1,0) [0|0] "" Vector__XXX
 SG_ FC_a313_GB_inputVoltageRailOv : 56|1@1+ (1,0) [0|0] "" Vector__XXX

BO_ 960 VCRIGHT_alertMatrix: 8 Vector__XXX
 SG_ VCRIGHT_matrixIndex M : 0|4@1+ (1,0) [0|0] "" Vector__XXX
 SG_ VCRIGHT_a001_WatchdogReset m0 : 4|1@1+ (1,0) [0|0] "" Vector__XXX
 SG_ VCRIGHT_a061_XCPConnected m1 : 4|1@1+ (1,0) [0|0] "" Vector__XXX
 SG_ VCRIGHT_a181_rearDoorLatchRehome m3 : 4|1@1+ (1,0) [0|0] "" Vector__XXX
 SG_ VCRIGHT_a241_seatHeatMIAFront m4 : 4|1@1+ (1,0) [0|0] "" Vector__XXX
 SG_ VCRIGHT_a361_stationaryThresholdsIncorrect m6 : 4|1@1+ (1,0) [0|0] "" Vector__XXX
 SG_ VCRIGHT_a002_PowerLossReset m0 : 5|1@1+ (1,0) [0|0] "" Vector__XXX
 SG_ VCRIGHT_a062_XCPWasConnected m1 : 5|1@1+ (1,0) [0|0] "" Vector__XXX
 SG_ VCRIGHT_a122_ICR_MIA m2 : 5|1@1+ (1,0) [0|0] "" Vector__XXX
 SG_ VCRIGHT_a182_emergencyLatchRel m3 : 5|1@1+ (1,0) [0|0] "" Vector__XXX
 SG_ VCRIGHT_a242_seatHeatIRearL m4 : 5|1@1+ (1,0) [0|0] "" Vector__XXX
 SG_ VCRIGHT_a362_movingThresholdsIncorrect m6 : 5|1@1+ (1,0) [0|0] "" Vector__XXX
 SG_ VCRIGHT_a482_NCV77XXFault m8 : 5|1@1+ (1,0) [0|0] "" Vector__XXX
 SG_ VCRIGHT_a542_steeringWheelHeatingInhibited m9 : 5|1@1+ (1,0) [0|0] "" Vector__XXX
 SG_ VCRIGHT_a003_SWAssertion m0 : 6|1@1+ (1,0) [0|0] "" Vector__XXX
 SG_ VCRIGHT_a063_SwitchFault m1 : 6|1@1+ (1,0) [0|0] "" Vector__XXX
 SG_ VCRIGHT_a183_doorStateFactoryTest m3 : 6|1@1+ (1,0) [0|0] "" Vector__XXX
 SG_ VCRIGHT_a243_seatHeatShortRearL m4 : 6|1@1+ (1,0) [0|0] "" Vector__XXX
 SG_ VCRIGHT_a303_eFuseMgmtWindowLift m5 : 6|1@1+ (1,0) [0|0] "" Vector__XXX
 SG_ VCRIGHT_a363_hvacLowerModeWarning m6 : 6|1@1+ (1,0) [0|0] "" Vector__XXX
 SG_ VCRIGHT_a483_rightTurnLightFaultUser m8 : 6|1@1+ (1,0) [0|0] "" Vector__XXX
 SG_ VCRIGHT_a064_busSleepReqTimeout m1 : 7|1@1+ (1,0) [0|0] "" Vector__XXX
 SG_ VCRIGHT_a184_trunkFailedOpening m3 : 7|1@1+ (1,0) [0|0] "" Vector__XXX
 SG_ VCRIGHT_a244_seatHeatMIARearL m4 : 7|1@1+ (1,0) [0|0] "" Vector__XXX
 SG_ VCRIGHT_a304_frontIntHandleUnexpectedVoltage m5 : 7|1@1+ (1,0) [0|0] "" Vector__XXX
 SG_ VCRIGHT_a364_hvacIntakeWarning m6 : 7|1@1+ (1,0) [0|0] "" Vector__XXX
 SG_ VCRIGHT_a484_rightBrakeLightFaultUser m8 : 7|1@1+ (1,0) [0|0] "" Vector__XXX
 SG_ VCRIGHT_a005_CANTXError m0 : 8|1@1+ (1,0) [0|0] "" Vector__XXX
 SG_ VCRIGHT_a065_emiosIsrRateLimitedDbg m1 : 8|1@1+ (1,0) [0|0] "" Vector__XXX
 SG_ VCRIGHT_a185_summonAborted m3 : 8|1@1+ (1,0) [0|0] "" Vector__XXX
 SG_ VCRIGHT_a245_seatHeatIRearC m4 : 8|1@1+ (1,0) [0|0] "" Vector__XXX
 SG_ VCRIGHT_a305_rearIntHandleUnexpectedVoltage m5 : 8|1@1+ (1,0) [0|0] "" Vector__XXX
 SG_ VCRIGHT_a365_pitchUnlatchDisabled m6 : 8|1@1+ (1,0) [0|0] "" Vector__XXX
 SG_ VCRIGHT_a545_LVBatteryTypeUnknown m9 : 8|1@1+ (1,0) [0|0] "" Vector__XXX
 SG_ VCRIGHT_a006_CANTX_cyclicError m0 : 9|1@1+ (1,0) [0|0] "" Vector__XXX
 SG_ VCRIGHT_a066_emiosIsrShortPeriodDetectedDbg m1 : 9|1@1+ (1,0) [0|0] "" Vector__XXX
 SG_ VCRIGHT_a126_hvacActOpenLoadDBG m2 : 9|1@1+ (1,0) [0|0] "" Vector__XXX
 SG_ VCRIGHT_a186_latchReleaseFailedF m3 : 9|1@1+ (1,0) [0|0] "" Vector__XXX
 SG_ VCRIGHT_a246_seatHeatShortRearC m4 : 9|1@1+ (1,0) [0|0] "" Vector__XXX
 SG_ VCRIGHT_a306_handleDisconnectedF m5 : 9|1@1+ (1,0) [0|0] "" Vector__XXX
 SG_ VCRIGHT_a366_trunkLatchUnhomed m6 : 9|1@1+ (1,0) [0|0] "" Vector__XXX
 SG_ VCRIGHT_a426_seatAbuseMotorWarn m7 : 9|1@1+ (1,0) [0|0] "" Vector__XXX
 SG_ VCRIGHT_a486_rightTailLightFaultUser m8 : 9|1@1+ (1,0) [0|0] "" Vector__XXX
 SG_ VCRIGHT_a546_mirrorFoldTypeChanged m9 : 9|1@1+ (1,0) [0|0] "" Vector__XXX
 SG_ VCRIGHT_a127_hvacActOvercurrentDBG m2 : 10|1@1+ (1,0) [0|0] "" Vector__XXX
 SG_ VCRIGHT_a187_latchReleaseFailedR m3 : 10|1@1+ (1,0) [0|0] "" Vector__XXX
 SG_ VCRIGHT_a247_seatHeatMIARearC m4 : 10|1@1+ (1,0) [0|0] "" Vector__XXX
 SG_ VCRIGHT_a307_handleDisconnectedR m5 : 10|1@1+ (1,0) [0|0] "" Vector__XXX
 SG_ VCRIGHT_a367_trunkLatchSwFault m6 : 10|1@1+ (1,0) [0|0] "" Vector__XXX
 SG_ VCRIGHT_a427_seatAbuseMotorStop m7 : 10|1@1+ (1,0) [0|0] "" Vector__XXX
 SG_ VCRIGHT_a128_hvacActDrvFaultDBG m2 : 11|1@1+ (1,0) [0|0] "" Vector__XXX
 SG_ VCRIGHT_a188_latchUnableToRearmF m3 : 11|1@1+ (1,0) [0|0] "" Vector__XXX
 SG_ VCRIGHT_a248_seatHeatIRearR m4 : 11|1@1+ (1,0) [0|0] "" Vector__XXX
 SG_ VCRIGHT_a368_ductLeftLowerTempSns m6 : 11|1@1+ (1,0) [0|0] "" Vector__XXX
 SG_ VCRIGHT_a428_seatAbuseBufferWarn m7 : 11|1@1+ (1,0) [0|0] "" Vector__XXX
 SG_ VCRIGHT_a129_hvacIntakeUncalib m2 : 12|1@1+ (1,0) [0|0] "" Vector__XXX
 SG_ VCRIGHT_a189_latchUnableToRearmR m3 : 12|1@1+ (1,0) [0|0] "" Vector__XXX
 SG_ VCRIGHT_a249_seatHeatShortRearR m4 : 12|1@1+ (1,0) [0|0] "" Vector__XXX
 SG_ VCRIGHT_a369_ductRightLowerTempSns m6 : 12|1@1+ (1,0) [0|0] "" Vector__XXX
 SG_ VCRIGHT_a429_seatAbuseBufferFull m7 : 12|1@1+ (1,0) [0|0] "" Vector__XXX
 SG_ VCRIGHT_a010_ExtSupplyVoltError m0 : 13|1@1+ (1,0) [0|0] "" Vector__XXX
 SG_ VCRIGHT_a130_hvacLHBleedUncalib m2 : 13|1@1+ (1,0) [0|0] "" Vector__XXX
 SG_ VCRIGHT_a190_eFuseMgmtVbatFused m3 : 13|1@1+ (1,0) [0|0] "" Vector__XXX
 SG_ VCRIGHT_a250_seatHeatMIARearR m4 : 13|1@1+ (1,0) [0|0] "" Vector__XXX
 SG_ VCRIGHT_a310_mirrorFoldStall m5 : 13|1@1+ (1,0) [0|0] "" Vector__XXX
 SG_ VCRIGHT_a370_seat2RowPitchUnlatched m6 : 13|1@1+ (1,0) [0|0] "" Vector__XXX
 SG_ VCRIGHT_a490_vehicleOccupiedOnOTAStart m8 : 13|1@1+ (1,0) [0|0] "" Vector__XXX
 SG_ VCRIGHT_a550_ambientTempDelta m9 : 13|1@1+ (1,0) [0|0] "" Vector__XXX
 SG_ VCRIGHT_a131_hvacRHBleedUncalib m2 : 14|1@1+ (1,0) [0|0] "" Vector__XXX
 SG_ VCRIGHT_a191_gloveboxPower m3 : 14|1@1+ (1,0) [0|0] "" Vector__XXX
 SG_ VCRIGHT_a251_seatUncalTrack m4 : 14|1@1+ (1,0) [0|0] "" Vector__XXX
 SG_ VCRIGHT_a311_rightBrakeLightFault m5 : 14|1@1+ (1,0) [0|0] "" Vector__XXX
 SG_ VCRIGHT_a371_seat2RowTrackUnlatched m6 : 14|1@1+ (1,0) [0|0] "" Vector__XXX
 SG_ VCRIGHT_a491_BPillarCameraHeaterFault m8 : 14|1@1+ (1,0) [0|0] "" Vector__XXX
 SG_ VCRIGHT_a551_interiorDoorRequestInhibited m9 : 14|1@1+ (1,0) [0|0] "" Vector__XXX
 SG_ VCRIGHT_a012_CPUReset m0 : 15|1@1+ (1,0) [0|0] "" Vector__XXX
 SG_ VCRIGHT_a132_hvacLHVaneUncalib m2 : 15|1@1+ (1,0) [0|0] "" Vector__XXX
 SG_ VCRIGHT_a192_gloveboxLatchRel m3 : 15|1@1+ (1,0) [0|0] "" Vector__XXX
 SG_ VCRIGHT_a252_seatUncalBack m4 : 15|1@1+ (1,0) [0|0] "" Vector__XXX
 SG_ VCRIGHT_a312_rightTailLightFault m5 : 15|1@1+ (1,0) [0|0] "" Vector__XXX
 SG_ VCRIGHT_a372_seat2RowBackrestUnlatched m6 : 15|1@1+ (1,0) [0|0] "" Vector__XXX
 SG_ VCRIGHT_a013_AlertManagerFault m0 : 16|1@1+ (1,0) [0|0] "" Vector__XXX
 SG_ VCRIGHT_a133_hvacRHVaneUncalib m2 : 16|1@1+ (1,0) [0|0] "" Vector__XXX
 SG_ VCRIGHT_a193_amplifierEFuseFault m3 : 16|1@1+ (1,0) [0|0] "" Vector__XXX
 SG_ VCRIGHT_a253_seatUncalTilt m4 : 16|1@1+ (1,0) [0|0] "" Vector__XXX
 SG_ VCRIGHT_a313_rightFootwellLightFault m5 : 16|1@1+ (1,0) [0|0] "" Vector__XXX
 SG_ VCRIGHT_a373_windowSwOpenReqInDogMode m6 : 16|1@1+ (1,0) [0|0] "" Vector__XXX
 SG_ VCRIGHT_a134_hvacUpprModeUncalib m2 : 17|1@1+ (1,0) [0|0] "" Vector__XXX
 SG_ VCRIGHT_a194_cntctrPwrEFuseFault m3 : 17|1@1+ (1,0) [0|0] "" Vector__XXX
 SG_ VCRIGHT_a254_seatUncalLift m4 : 17|1@1+ (1,0) [0|0] "" Vector__XXX
 SG_ VCRIGHT_a314_rightMapPocketLightFault m5 : 17|1@1+ (1,0) [0|0] "" Vector__XXX
 SG_ VCRIGHT_a015_NVMMError m0 : 18|1@1+ (1,0) [0|0] "" Vector__XXX
 SG_ VCRIGHT_a135_hvacLowrModeUncalib m2 : 18|1@1+ (1,0) [0|0] "" Vector__XXX
 SG_ VCRIGHT_a195_hvcEFuseFault m3 : 18|1@1+ (1,0) [0|0] "" Vector__XXX
 SG_ VCRIGHT_a255_PTCOverTemp m4 : 18|1@1+ (1,0) [0|0] "" Vector__XXX
 SG_ VCRIGHT_a315_rightInteriorTrunkLightFault m5 : 18|1@1+ (1,0) [0|0] "" Vector__XXX
 SG_ VCRIGHT_a375_windowPinchOverrideNudge m6 : 18|1@1+ (1,0) [0|0] "" Vector__XXX
 SG_ VCRIGHT_a555_RCM2_MIA m9 : 18|1@1+ (1,0) [0|0] "" Vector__XXX
 SG_ VCRIGHT_a016_NVMMRecordError m0 : 19|1@1+ (1,0) [0|0] "" Vector__XXX
 SG_ VCRIGHT_a136_hvacIntakeFault m2 : 19|1@1+ (1,0) [0|0] "" Vector__XXX
 SG_ VCRIGHT_a196_VEHCANOverterminate m3 : 19|1@1+ (1,0) [0|0] "" Vector__XXX
 SG_ VCRIGHT_a256_PTCCurrentDrawNoReq m4 : 19|1@1+ (1,0) [0|0] "" Vector__XXX
 SG_ VCRIGHT_a316_mirrorPrematureFoldStall m5 : 19|1@1+ (1,0) [0|0] "" Vector__XXX
 SG_ VCRIGHT_a376_seat2RowBridgeCurrentExceeded m6 : 19|1@1+ (1,0) [0|0] "" Vector__XXX
 SG_ VCRIGHT_a496_gloveboxOpenFailed m8 : 19|1@1+ (1,0) [0|0] "" Vector__XXX
 SG_ VCRIGHT_a556_rcmReportedOCSError m9 : 19|1@1+ (1,0) [0|0] "" Vector__XXX
 SG_ VCRIGHT_a017_NVMMStatusDbg m0 : 20|1@1+ (1,0) [0|0] "" Vector__XXX
 SG_ VCRIGHT_a137_hvacLHBleedFault m2 : 20|1@1+ (1,0) [0|0] "" Vector__XXX
 SG_ VCRIGHT_a197_VEHCANUndertrminate m3 : 20|1@1+ (1,0) [0|0] "" Vector__XXX
 SG_ VCRIGHT_a257_THSMIA m4 : 20|1@1+ (1,0) [0|0] "" Vector__XXX
 SG_ VCRIGHT_a317_epbmLimpModeEnabled m5 : 20|1@1+ (1,0) [0|0] "" Vector__XXX
 SG_ VCRIGHT_a377_ambientTempSns m6 : 20|1@1+ (1,0) [0|0] "" Vector__XXX
 SG_ VCRIGHT_a617_APP_MIA m10 : 20|1@1+ (1,0) [0|0] "" Vector__XXX
 SG_ VCRIGHT_a138_hvacRHBleedFault m2 : 21|1@1+ (1,0) [0|0] "" Vector__XXX
 SG_ VCRIGHT_a198_PRVCANOverterminate m3 : 21|1@1+ (1,0) [0|0] "" Vector__XXX
 SG_ VCRIGHT_a258_PTCStuckInBoot m4 : 21|1@1+ (1,0) [0|0] "" Vector__XXX
 SG_ VCRIGHT_a318_leftExteriorTrunkLightFault m5 : 21|1@1+ (1,0) [0|0] "" Vector__XXX
 SG_ VCRIGHT_a378_ductLeftUpperTempSns m6 : 21|1@1+ (1,0) [0|0] "" Vector__XXX
 SG_ VCRIGHT_a139_hvacLHVaneFault m2 : 22|1@1+ (1,0) [0|0] "" Vector__XXX
 SG_ VCRIGHT_a199_PRVCANUndertrminate m3 : 22|1@1+ (1,0) [0|0] "" Vector__XXX
 SG_ VCRIGHT_a259_latchDisarmDelayF m4 : 22|1@1+ (1,0) [0|0] "" Vector__XXX
 SG_ VCRIGHT_a319_rightExteriorTrunkLightFault m5 : 22|1@1+ (1,0) [0|0] "" Vector__XXX
 SG_ VCRIGHT_a379_ductRightUpperTempSns m6 : 22|1@1+ (1,0) [0|0] "" Vector__XXX
 SG_ VCRIGHT_a499_epbmInvalidateCdp m8 : 22|1@1+ (1,0) [0|0] "" Vector__XXX
 SG_ VCRIGHT_a140_hvacRHVaneFault m2 : 23|1@1+ (1,0) [0|0] "" Vector__XXX
 SG_ VCRIGHT_a200_motorPhantomEncoder m3 : 23|1@1+ (1,0) [0|0] "" Vector__XXX
 SG_ VCRIGHT_a260_latchDisarmDelayR m4 : 23|1@1+ (1,0) [0|0] "" Vector__XXX
 SG_ VCRIGHT_a320_windowReportCrackedAtTrimClear m5 : 23|1@1+ (1,0) [0|0] "" Vector__XXX
 SG_ VCRIGHT_a380_reverseLightFault m6 : 23|1@1+ (1,0) [0|0] "" Vector__XXX
 SG_ VCRIGHT_a021_TaskSchedulerError m0 : 24|1@1+ (1,0) [0|0] "" Vector__XXX
 SG_ VCRIGHT_a141_hvacUpperModeFault m2 : 24|1@1+ (1,0) [0|0] "" Vector__XXX
 SG_ VCRIGHT_a201_motorDutyEncDisabl m3 : 24|1@1+ (1,0) [0|0] "" Vector__XXX
 SG_ VCRIGHT_a261_emergencyLatchRelRear m4 : 24|1@1+ (1,0) [0|0] "" Vector__XXX
 SG_ VCRIGHT_a321_windowRezeroedDebugF m5 : 24|1@1+ (1,0) [0|0] "" Vector__XXX
 SG_ VCRIGHT_a381_rearFogLightFault m6 : 24|1@1+ (1,0) [0|0] "" Vector__XXX
 SG_ VCRIGHT_a022_TaskInitError m0 : 25|1@1+ (1,0) [0|0] "" Vector__XXX
 SG_ VCRIGHT_a082_VCRIGHT_IPC_MIA m1 : 25|1@1+ (1,0) [0|0] "" Vector__XXX
 SG_ VCRIGHT_a142_hvacLowerModeFault m2 : 25|1@1+ (1,0) [0|0] "" Vector__XXX
 SG_ VCRIGHT_a202_epbmUnderIStatic m3 : 25|1@1+ (1,0) [0|0] "" Vector__XXX
 SG_ VCRIGHT_a262_PTCFaulted m4 : 25|1@1+ (1,0) [0|0] "" Vector__XXX
 SG_ VCRIGHT_a322_windowRezeroedDebugR m5 : 25|1@1+ (1,0) [0|0] "" Vector__XXX
 SG_ VCRIGHT_a382_leftLiftgateTailLightFault m6 : 25|1@1+ (1,0) [0|0] "" Vector__XXX
 SG_ VCRIGHT_a083_VCLEFT_IPC_MIA m1 : 26|1@1+ (1,0) [0|0] "" Vector__XXX
 SG_ VCRIGHT_a143_mirrorManuallyFolded m2 : 26|1@1+ (1,0) [0|0] "" Vector__XXX
 SG_ VCRIGHT_a203_epbmOverIStatic m3 : 26|1@1+ (1,0) [0|0] "" Vector__XXX
 SG_ VCRIGHT_a263_seatTrackStallDebug m4 : 26|1@1+ (1,0) [0|0] "" Vector__XXX
 SG_ VCRIGHT_a323_mirrorCalibrated m5 : 26|1@1+ (1,0) [0|0] "" Vector__XXX
 SG_ VCRIGHT_a084_TPMS_MIA m1 : 27|1@1+ (1,0) [0|0] "" Vector__XXX
 SG_ VCRIGHT_a144_evaporatorTempSns m2 : 27|1@1+ (1,0) [0|0] "" Vector__XXX
 SG_ VCRIGHT_a204_epbmUnderIDyn m3 : 27|1@1+ (1,0) [0|0] "" Vector__XXX
 SG_ VCRIGHT_a264_seatBackStallDebug m4 : 27|1@1+ (1,0) [0|0] "" Vector__XXX
 SG_ VCRIGHT_a324_mirrorHeatFault m5 : 27|1@1+ (1,0) [0|0] "" Vector__XXX
 SG_ VCRIGHT_a444_drv8703Fault m7 : 27|1@1+ (1,0) [0|0] "" Vector__XXX
 SG_ VCRIGHT_a085_CCCM_MIA m1 : 28|1@1+ (1,0) [0|0] "" Vector__XXX
 SG_ VCRIGHT_a145_ductLeftTempSns m2 : 28|1@1+ (1,0) [0|0] "" Vector__XXX
 SG_ VCRIGHT_a205_epbmOverIDyn m3 : 28|1@1+ (1,0) [0|0] "" Vector__XXX
 SG_ VCRIGHT_a265_seatTiltStallDebug m4 : 28|1@1+ (1,0) [0|0] "" Vector__XXX
 SG_ VCRIGHT_a445_drv8703SpiFaultDBG m7 : 28|1@1+ (1,0) [0|0] "" Vector__XXX
 SG_ VCRIGHT_a086_VCBATT_MIA m1 : 29|1@1+ (1,0) [0|0] "" Vector__XXX
 SG_ VCRIGHT_a146_ductRightTempSns m2 : 29|1@1+ (1,0) [0|0] "" Vector__XXX
 SG_ VCRIGHT_a206_epbWrongDirection m3 : 29|1@1+ (1,0) [0|0] "" Vector__XXX
 SG_ VCRIGHT_a266_seatLiftStallDebug m4 : 29|1@1+ (1,0) [0|0] "" Vector__XXX
 SG_ VCRIGHT_a446_cabinHVACUnavailableContext m7 : 29|1@1+ (1,0) [0|0] "" Vector__XXX
 SG_ VCRIGHT_a087_DIREL_MIA m1 : 30|1@1+ (1,0) [0|0] "" Vector__XXX
 SG_ VCRIGHT_a147_incarProbeTempSns m2 : 30|1@1+ (1,0) [0|0] "" Vector__XXX
 SG_ VCRIGHT_a207_epbmEnableWrong m3 : 30|1@1+ (1,0) [0|0] "" Vector__XXX
 SG_ VCRIGHT_a267_seatTrackHCEncStlDbg m4 : 30|1@1+ (1,0) [0|0] "" Vector__XXX
 SG_ VCRIGHT_a088_DIRER_MIA m1 : 31|1@1+ (1,0) [0|0] "" Vector__XXX
 SG_ VCRIGHT_a148_incarMidTempSns m2 : 31|1@1+ (1,0) [0|0] "" Vector__XXX
 SG_ VCRIGHT_a208_epbFaulted m3 : 31|1@1+ (1,0) [0|0] "" Vector__XXX
 SG_ VCRIGHT_a268_seatBackHCEncStlDbg m4 : 31|1@1+ (1,0) [0|0] "" Vector__XXX
 SG_ VCRIGHT_a448_manualHVACAlert m7 : 31|1@1+ (1,0) [0|0] "" Vector__XXX
 SG_ VCRIGHT_a029_CoreDump m0 : 32|1@1+ (1,0) [0|0] "" Vector__XXX
 SG_ VCRIGHT_a089_IBST_MIA m1 : 32|1@1+ (1,0) [0|0] "" Vector__XXX
 SG_ VCRIGHT_a149_incarDeepTempSns m2 : 32|1@1+ (1,0) [0|0] "" Vector__XXX
 SG_ VCRIGHT_a209_epbStateMisTime m3 : 32|1@1+ (1,0) [0|0] "" Vector__XXX
 SG_ VCRIGHT_a269_seatTiltHCEncStlDbg m4 : 32|1@1+ (1,0) [0|0] "" Vector__XXX
 SG_ VCRIGHT_a030_ECULogUploadRequest m0 : 33|1@1+ (1,0) [0|0] "" Vector__XXX
 SG_ VCRIGHT_a090_APS_MIA m1 : 33|1@1+ (1,0) [0|0] "" Vector__XXX
 SG_ VCRIGHT_a150_windowPinchFront m2 : 33|1@1+ (1,0) [0|0] "" Vector__XXX
 SG_ VCRIGHT_a210_epbStateTime m3 : 33|1@1+ (1,0) [0|0] "" Vector__XXX
 SG_ VCRIGHT_a270_seatLiftHCEncStlDbg m4 : 33|1@1+ (1,0) [0|0] "" Vector__XXX
 SG_ VCRIGHT_a330_shortDropFailedF m5 : 33|1@1+ (1,0) [0|0] "" Vector__XXX
 SG_ VCRIGHT_a450_ptcForcedOutOfSeqRod m7 : 33|1@1+ (1,0) [0|0] "" Vector__XXX
 SG_ VCRIGHT_a570_seatHeatDisabledF m9 : 33|1@1+ (1,0) [0|0] "" Vector__XXX
 SG_ VCRIGHT_a031_UDSActive m0 : 34|1@1+ (1,0) [0|0] "" Vector__XXX
 SG_ VCRIGHT_a091_CMPD_MIA m1 : 34|1@1+ (1,0) [0|0] "" Vector__XXX
 SG_ VCRIGHT_a151_windowPinchRear m2 : 34|1@1+ (1,0) [0|0] "" Vector__XXX
 SG_ VCRIGHT_a211_epbmUnderIStaticNew m3 : 34|1@1+ (1,0) [0|0] "" Vector__XXX
 SG_ VCRIGHT_a271_THSSensorFault m4 : 34|1@1+ (1,0) [0|0] "" Vector__XXX
 SG_ VCRIGHT_a331_shortDropFailedR m5 : 34|1@1+ (1,0) [0|0] "" Vector__XXX
 SG_ VCRIGHT_a451_ptcSeqRodOutOfRetries m7 : 34|1@1+ (1,0) [0|0] "" Vector__XXX
 SG_ VCRIGHT_a571_seatHeatDisabledRearL m9 : 34|1@1+ (1,0) [0|0] "" Vector__XXX
 SG_ VCRIGHT_a092_VCSEATD_MIA m1 : 35|1@1+ (1,0) [0|0] "" Vector__XXX
 SG_ VCRIGHT_a152_windowUncalFront m2 : 35|1@1+ (1,0) [0|0] "" Vector__XXX
 SG_ VCRIGHT_a212_epbmOverIStaticNew m3 : 35|1@1+ (1,0) [0|0] "" Vector__XXX
 SG_ VCRIGHT_a272_vhclPwrStateMsmtch m4 : 35|1@1+ (1,0) [0|0] "" Vector__XXX
 SG_ VCRIGHT_a572_seatHeatDisabledRearC m9 : 35|1@1+ (1,0) [0|0] "" Vector__XXX
 SG_ VCRIGHT_a093_VCSEATP_MIA m1 : 36|1@1+ (1,0) [0|0] "" Vector__XXX
 SG_ VCRIGHT_a153_windowUncalRear m2 : 36|1@1+ (1,0) [0|0] "" Vector__XXX
 SG_ VCRIGHT_a213_epbmUnderIDynNew m3 : 36|1@1+ (1,0) [0|0] "" Vector__XXX
 SG_ VCRIGHT_a273_handleStuckActiveF m4 : 36|1@1+ (1,0) [0|0] "" Vector__XXX
 SG_ VCRIGHT_a573_seatHeatDisabledRearR m9 : 36|1@1+ (1,0) [0|0] "" Vector__XXX
 SG_ VCRIGHT_a094_EPAS3P_MIA m1 : 37|1@1+ (1,0) [0|0] "" Vector__XXX
 SG_ VCRIGHT_a154_windowThermalFront m2 : 37|1@1+ (1,0) [0|0] "" Vector__XXX
 SG_ VCRIGHT_a214_epbmOverIDynNew m3 : 37|1@1+ (1,0) [0|0] "" Vector__XXX
 SG_ VCRIGHT_a274_handleStuckActiveR m4 : 37|1@1+ (1,0) [0|0] "" Vector__XXX
 SG_ VCRIGHT_a454_ptcHeaterBadRodDetected m7 : 37|1@1+ (1,0) [0|0] "" Vector__XXX
 SG_ VCRIGHT_a095_CHG_MIA m1 : 38|1@1+ (1,0) [0|0] "" Vector__XXX
 SG_ VCRIGHT_a155_windowThermalRear m2 : 38|1@1+ (1,0) [0|0] "" Vector__XXX
 SG_ VCRIGHT_a215_currentDesyncWarning m3 : 38|1@1+ (1,0) [0|0] "" Vector__XXX
 SG_ VCRIGHT_a275_rightTurnLightFault m4 : 38|1@1+ (1,0) [0|0] "" Vector__XXX
 SG_ VCRIGHT_a096_OCS1P_MIA m1 : 39|1@1+ (1,0) [0|0] "" Vector__XXX
 SG_ VCRIGHT_a156_windowNoInputFront m2 : 39|1@1+ (1,0) [0|0] "" Vector__XXX
 SG_ VCRIGHT_a216_SPI_MIA_debugData1 m3 : 39|1@1+ (1,0) [0|0] "" Vector__XXX
 SG_ VCRIGHT_a276_mirrorDebug m4 : 39|1@1+ (1,0) [0|0] "" Vector__XXX
 SG_ VCRIGHT_a336_windowDropRevThermalF m5 : 39|1@1+ (1,0) [0|0] "" Vector__XXX
 SG_ VCRIGHT_a097_CMP_MIA m1 : 40|1@1+ (1,0) [0|0] "" Vector__XXX
 SG_ VCRIGHT_a157_windowNoInputRear m2 : 40|1@1+ (1,0) [0|0] "" Vector__XXX
 SG_ VCRIGHT_a217_SPI_MIA_debugData2 m3 : 40|1@1+ (1,0) [0|0] "" Vector__XXX
 SG_ VCRIGHT_a277_BLERightUnderVoltage m4 : 40|1@1+ (1,0) [0|0] "" Vector__XXX
 SG_ VCRIGHT_a337_windowDropRevThermalR m5 : 40|1@1+ (1,0) [0|0] "" Vector__XXX
 SG_ VCRIGHT_a098_DIR_MIA m1 : 41|1@1+ (1,0) [0|0] "" Vector__XXX
 SG_ VCRIGHT_a158_windowPinchOverideF m2 : 41|1@1+ (1,0) [0|0] "" Vector__XXX
 SG_ VCRIGHT_a218_motorDriverFault m3 : 41|1@1+ (1,0) [0|0] "" Vector__XXX
 SG_ VCRIGHT_a278_hvacPtcHeatingUnavailable m4 : 41|1@1+ (1,0) [0|0] "" Vector__XXX
 SG_ VCRIGHT_a099_PARK_MIA m1 : 42|1@1+ (1,0) [0|0] "" Vector__XXX
 SG_ VCRIGHT_a159_windowPinchOverideR m2 : 42|1@1+ (1,0) [0|0] "" Vector__XXX
 SG_ VCRIGHT_a219_motorCurrentDropout m3 : 42|1@1+ (1,0) [0|0] "" Vector__XXX
 SG_ VCRIGHT_a279_trunkFailedToClose m4 : 42|1@1+ (1,0) [0|0] "" Vector__XXX
 SG_ VCRIGHT_a100_CANbus_MIA m1 : 43|1@1+ (1,0) [0|0] "" Vector__XXX
 SG_ VCRIGHT_a160_windowUndercurrentF m2 : 43|1@1+ (1,0) [0|0] "" Vector__XXX
 SG_ VCRIGHT_a280_latchDidNotDisarmF m4 : 43|1@1+ (1,0) [0|0] "" Vector__XXX
 SG_ VCRIGHT_a520_configMismatch m8 : 43|1@1+ (1,0) [0|0] "" Vector__XXX
 SG_ VCRIGHT_a041_HighCPULoad m0 : 44|1@1+ (1,0) [0|0] "" Vector__XXX
 SG_ VCRIGHT_a101_PM_MIA m1 : 44|1@1+ (1,0) [0|0] "" Vector__XXX
 SG_ VCRIGHT_a161_windowUndercurrentR m2 : 44|1@1+ (1,0) [0|0] "" Vector__XXX
 SG_ VCRIGHT_a281_latchDidNotDisarmR m4 : 44|1@1+ (1,0) [0|0] "" Vector__XXX
 SG_ VCRIGHT_a042_HighStackUsage m0 : 45|1@1+ (1,0) [0|0] "" Vector__XXX
 SG_ VCRIGHT_a102_PTC_MIA m1 : 45|1@1+ (1,0) [0|0] "" Vector__XXX
 SG_ VCRIGHT_a162_windowEncoderStallF m2 : 45|1@1+ (1,0) [0|0] "" Vector__XXX
 SG_ VCRIGHT_a282_latchUnexpectedArmF m4 : 45|1@1+ (1,0) [0|0] "" Vector__XXX
 SG_ VCRIGHT_a342_rearDefrostDisabled m5 : 45|1@1+ (1,0) [0|0] "" Vector__XXX
 SG_ VCRIGHT_a043_Task1msError m0 : 46|1@1+ (1,0) [0|0] "" Vector__XXX
 SG_ VCRIGHT_a103_CP_MIA m1 : 46|1@1+ (1,0) [0|0] "" Vector__XXX
 SG_ VCRIGHT_a163_windowEncoderStallR m2 : 46|1@1+ (1,0) [0|0] "" Vector__XXX
 SG_ VCRIGHT_a283_latchUnexpectedArmR m4 : 46|1@1+ (1,0) [0|0] "" Vector__XXX
 SG_ VCRIGHT_a343_rearDefrostUndercurrent m5 : 46|1@1+ (1,0) [0|0] "" Vector__XXX
 SG_ VCRIGHT_a583_doorRemoteUnlatchedFront m9 : 46|1@1+ (1,0) [0|0] "" Vector__XXX
 SG_ VCRIGHT_a044_Task10msError m0 : 47|1@1+ (1,0) [0|0] "" Vector__XXX
 SG_ VCRIGHT_a104_DAS_MIA m1 : 47|1@1+ (1,0) [0|0] "" Vector__XXX
 SG_ VCRIGHT_a164_windowFactoryTest m2 : 47|1@1+ (1,0) [0|0] "" Vector__XXX
 SG_ VCRIGHT_a224_seatEncStallTrack m3 : 47|1@1+ (1,0) [0|0] "" Vector__XXX
 SG_ VCRIGHT_a284_gloveboxUnderCurrentDetected m4 : 47|1@1+ (1,0) [0|0] "" Vector__XXX
 SG_ VCRIGHT_a344_rearDefrostOvercurrent m5 : 47|1@1+ (1,0) [0|0] "" Vector__XXX
 SG_ VCRIGHT_a584_doorRemoteUnlatchedRear m9 : 47|1@1+ (1,0) [0|0] "" Vector__XXX
 SG_ VCRIGHT_a045_Task100msError m0 : 48|1@1+ (1,0) [0|0] "" Vector__XXX
 SG_ VCRIGHT_a105_TAS_MIA m1 : 48|1@1+ (1,0) [0|0] "" Vector__XXX
 SG_ VCRIGHT_a165_windowFactoryTest2 m2 : 48|1@1+ (1,0) [0|0] "" Vector__XXX
 SG_ VCRIGHT_a225_seatEncStallBack m3 : 48|1@1+ (1,0) [0|0] "" Vector__XXX
 SG_ VCRIGHT_a285_gloveboxOverCurrentDetected m4 : 48|1@1+ (1,0) [0|0] "" Vector__XXX
 SG_ VCRIGHT_a345_HVACPTCHeaterPwrEFuseFault m5 : 48|1@1+ (1,0) [0|0] "" Vector__XXX
 SG_ VCRIGHT_a525_LVBatterySWMisconfiguration m8 : 48|1@1+ (1,0) [0|0] "" Vector__XXX
 SG_ VCRIGHT_a585_doorRemoteUnlatchFailedFront m9 : 48|1@1+ (1,0) [0|0] "" Vector__XXX
 SG_ VCRIGHT_a046_Task1000msError m0 : 49|1@1+ (1,0) [0|0] "" Vector__XXX
 SG_ VCRIGHT_a106_PCS_MIA m1 : 49|1@1+ (1,0) [0|0] "" Vector__XXX
 SG_ VCRIGHT_a166_windowDebug m2 : 49|1@1+ (1,0) [0|0] "" Vector__XXX
 SG_ VCRIGHT_a226_seatEncStallTilt m3 : 49|1@1+ (1,0) [0|0] "" Vector__XXX
 SG_ VCRIGHT_a286_windowSpeedInvalidF m4 : 49|1@1+ (1,0) [0|0] "" Vector__XXX
 SG_ VCRIGHT_a346_cabinRadarEFuseFault m5 : 49|1@1+ (1,0) [0|0] "" Vector__XXX
 SG_ VCRIGHT_a526_pcbaOverTemperature m8 : 49|1@1+ (1,0) [0|0] "" Vector__XXX
 SG_ VCRIGHT_a586_doorRemoteUnlatchFailedRear m9 : 49|1@1+ (1,0) [0|0] "" Vector__XXX
 SG_ VCRIGHT_a107_BMS_MIA m1 : 50|1@1+ (1,0) [0|0] "" Vector__XXX
 SG_ VCRIGHT_a167_windowDebugPinchF m2 : 50|1@1+ (1,0) [0|0] "" Vector__XXX
 SG_ VCRIGHT_a227_seatEncStallLift m3 : 50|1@1+ (1,0) [0|0] "" Vector__XXX
 SG_ VCRIGHT_a287_windowSpeedInvalidR m4 : 50|1@1+ (1,0) [0|0] "" Vector__XXX
 SG_ VCRIGHT_a347_nonContMonitorClearedDBG m5 : 50|1@1+ (1,0) [0|0] "" Vector__XXX
 SG_ VCRIGHT_a527_continuousFeedUnexpectedVoltage m8 : 50|1@1+ (1,0) [0|0] "" Vector__XXX
 SG_ VCRIGHT_a108_DIF_MIA m1 : 51|1@1+ (1,0) [0|0] "" Vector__XXX
 SG_ VCRIGHT_a168_windowDebugPinchR m2 : 51|1@1+ (1,0) [0|0] "" Vector__XXX
 SG_ VCRIGHT_a228_seatEncOverTrack m3 : 51|1@1+ (1,0) [0|0] "" Vector__XXX
 SG_ VCRIGHT_a288_handlePWMPeriodF m4 : 51|1@1+ (1,0) [0|0] "" Vector__XXX
 SG_ VCRIGHT_a528_unableToRunStuckOnTest m8 : 51|1@1+ (1,0) [0|0] "" Vector__XXX
 SG_ VCRIGHT_a109_RCM_MIA m1 : 52|1@1+ (1,0) [0|0] "" Vector__XXX
 SG_ VCRIGHT_a169_windowCurrentPeakF m2 : 52|1@1+ (1,0) [0|0] "" Vector__XXX
 SG_ VCRIGHT_a229_seatEncOverBack m3 : 52|1@1+ (1,0) [0|0] "" Vector__XXX
 SG_ VCRIGHT_a289_handlePWMPeriodR m4 : 52|1@1+ (1,0) [0|0] "" Vector__XXX
 SG_ VCRIGHT_a589_defogSysDriverlessSelfTest m9 : 52|1@1+ (1,0) [0|0] "" Vector__XXX
 SG_ VCRIGHT_a110_GTW_MIA m1 : 53|1@1+ (1,0) [0|0] "" Vector__XXX
 SG_ VCRIGHT_a170_windowCurrentPeakR m2 : 53|1@1+ (1,0) [0|0] "" Vector__XXX
 SG_ VCRIGHT_a230_seatEncOverTilt m3 : 53|1@1+ (1,0) [0|0] "" Vector__XXX
 SG_ VCRIGHT_a290_occupancyFaultedFront m4 : 53|1@1+ (1,0) [0|0] "" Vector__XXX
 SG_ VCRIGHT_a111_EPBR_MIA m1 : 54|1@1+ (1,0) [0|0] "" Vector__XXX
 SG_ VCRIGHT_a231_seatEncOverLift m3 : 54|1@1+ (1,0) [0|0] "" Vector__XXX
 SG_ VCRIGHT_a291_buckleFaultedFront m4 : 54|1@1+ (1,0) [0|0] "" Vector__XXX
 SG_ VCRIGHT_a112_EPBL_MIA m1 : 55|1@1+ (1,0) [0|0] "" Vector__XXX
 SG_ VCRIGHT_a172_SPI_MIA m2 : 55|1@1+ (1,0) [0|0] "" Vector__XXX
 SG_ VCRIGHT_a232_seatCurrUnderTrack m3 : 55|1@1+ (1,0) [0|0] "" Vector__XXX
 SG_ VCRIGHT_a292_buckleFaultedRearC m4 : 55|1@1+ (1,0) [0|0] "" Vector__XXX
 SG_ VCRIGHT_a352_audioCurrentSpikeData m5 : 55|1@1+ (1,0) [0|0] "" Vector__XXX
 SG_ VCRIGHT_a113_UI_MIA m1 : 56|1@1+ (1,0) [0|0] "" Vector__XXX
 SG_ VCRIGHT_a173_windowBtnDoorOpen m2 : 56|1@1+ (1,0) [0|0] "" Vector__XXX
 SG_ VCRIGHT_a233_seatCurrUnderBack m3 : 56|1@1+ (1,0) [0|0] "" Vector__XXX
 SG_ VCRIGHT_a293_buckleFaultedRearR m4 : 56|1@1+ (1,0) [0|0] "" Vector__XXX
 SG_ VCRIGHT_a533_cabinModelDebug m8 : 56|1@1+ (1,0) [0|0] "" Vector__XXX
 SG_ VCRIGHT_a114_ESP_MIA m1 : 57|1@1+ (1,0) [0|0] "" Vector__XXX
 SG_ VCRIGHT_a174_BLERightPowerCycled m2 : 57|1@1+ (1,0) [0|0] "" Vector__XXX
 SG_ VCRIGHT_a234_seatCurrUnderTilt m3 : 57|1@1+ (1,0) [0|0] "" Vector__XXX
 SG_ VCRIGHT_a294_occupancyFaultedRearR m4 : 57|1@1+ (1,0) [0|0] "" Vector__XXX
 SG_ VCRIGHT_a115_VCSEC_MIA m1 : 58|1@1+ (1,0) [0|0] "" Vector__XXX
 SG_ VCRIGHT_a175_windowSealDefectFront m2 : 58|1@1+ (1,0) [0|0] "" Vector__XXX
 SG_ VCRIGHT_a235_seatCurrUnderLift m3 : 58|1@1+ (1,0) [0|0] "" Vector__XXX
 SG_ VCRIGHT_a295_occupancyFaulted3RowL m4 : 58|1@1+ (1,0) [0|0] "" Vector__XXX
 SG_ VCRIGHT_a355_hvacLHBleedWarning m5 : 58|1@1+ (1,0) [0|0] "" Vector__XXX
 SG_ VCRIGHT_a116_VCRIGHT_MIA m1 : 59|1@1+ (1,0) [0|0] "" Vector__XXX
 SG_ VCRIGHT_a176_windowSealDefectRear m2 : 59|1@1+ (1,0) [0|0] "" Vector__XXX
 SG_ VCRIGHT_a236_lumbarOverPresA m3 : 59|1@1+ (1,0) [0|0] "" Vector__XXX
 SG_ VCRIGHT_a296_occupancyFaulted3RowR m4 : 59|1@1+ (1,0) [0|0] "" Vector__XXX
 SG_ VCRIGHT_a356_hvacRHBleedWarning m5 : 59|1@1+ (1,0) [0|0] "" Vector__XXX
 SG_ VCRIGHT_a057_HVP_MIA m0 : 60|1@1+ (1,0) [0|0] "" Vector__XXX
 SG_ VCRIGHT_a117_VCLEFT_MIA m1 : 60|1@1+ (1,0) [0|0] "" Vector__XXX
 SG_ VCRIGHT_a237_lumbarOverPresB m3 : 60|1@1+ (1,0) [0|0] "" Vector__XXX
 SG_ VCRIGHT_a297_seatBelowMinPumpTmp m4 : 60|1@1+ (1,0) [0|0] "" Vector__XXX
 SG_ VCRIGHT_a357_hvacLHVaneWarning m5 : 60|1@1+ (1,0) [0|0] "" Vector__XXX
 SG_ VCRIGHT_a537_solarCalcsNotNominal m8 : 60|1@1+ (1,0) [0|0] "" Vector__XXX
 SG_ VCRIGHT_a058_inputRHighSyncDebug m0 : 61|1@1+ (1,0) [0|0] "" Vector__XXX
 SG_ VCRIGHT_a118_VCFRONT_MIA m1 : 61|1@1+ (1,0) [0|0] "" Vector__XXX
 SG_ VCRIGHT_a178_trunkSwitchVCBATTMIA m2 : 61|1@1+ (1,0) [0|0] "" Vector__XXX
 SG_ VCRIGHT_a238_lumbarValveMIA m3 : 61|1@1+ (1,0) [0|0] "" Vector__XXX
 SG_ VCRIGHT_a298_buckleFaulted3RowL m4 : 61|1@1+ (1,0) [0|0] "" Vector__XXX
 SG_ VCRIGHT_a358_hvacRHVaneWarning m5 : 61|1@1+ (1,0) [0|0] "" Vector__XXX
 SG_ VCRIGHT_a538_hvacSystemNotNominal m8 : 61|1@1+ (1,0) [0|0] "" Vector__XXX
 SG_ VCRIGHT_a598_childModeMonitorTrip m9 : 61|1@1+ (1,0) [0|0] "" Vector__XXX
 SG_ VCRIGHT_a059_inputResistanceHigh m0 : 62|1@1+ (1,0) [0|0] "" Vector__XXX
 SG_ VCRIGHT_a119_SCCM_MIA m1 : 62|1@1+ (1,0) [0|0] "" Vector__XXX
 SG_ VCRIGHT_a179_trunkSwitchVCFRONTMIA m2 : 62|1@1+ (1,0) [0|0] "" Vector__XXX
 SG_ VCRIGHT_a239_seatHeatIFront m3 : 62|1@1+ (1,0) [0|0] "" Vector__XXX
 SG_ VCRIGHT_a299_buckleFaulted3RowR m4 : 62|1@1+ (1,0) [0|0] "" Vector__XXX
 SG_ VCRIGHT_a359_hvacUpperModeWarning m5 : 62|1@1+ (1,0) [0|0] "" Vector__XXX
 SG_ VCRIGHT_a539_dogModeMonitorTrip m8 : 62|1@1+ (1,0) [0|0] "" Vector__XXX
 SG_ VCRIGHT_a599_LVBatteryTypeUnsupported m9 : 62|1@1+ (1,0) [0|0] "" Vector__XXX
 SG_ VCRIGHT_a060_engineeringBuild m0 : 63|1@1+ (1,0) [0|0] "" Vector__XXX
 SG_ VCRIGHT_a120_DI_DRIVE_MIA m1 : 63|1@1+ (1,0) [0|0] "" Vector__XXX
 SG_ VCRIGHT_a180_frontDoorLatchRehome m2 : 63|1@1+ (1,0) [0|0] "" Vector__XXX
 SG_ VCRIGHT_a240_seatHeatShortFront m3 : 63|1@1+ (1,0) [0|0] "" Vector__XXX
 SG_ VCRIGHT_a360_detectedStationaryWhileMoving m5 : 63|1@1+ (1,0) [0|0] "" Vector__XXX
 SG_ VCRIGHT_a540_hvacActuatorDitherDebug m8 : 63|1@1+ (1,0) [0|0] "" Vector__XXX

BO_ 962 VCLEFT_switchStatus: 8 Vector__XXX
 SG_ VCLEFT_switchStatusIndex M : 0|1@1+ (1,0) [0|0] "" Vector__XXX
 SG_ VCLEFT_hornSwitchPressed m0 : 2|1@1+ (1,0) [0|0] "" Vector__XXX
 SG_ VCLEFT_isAlcoholInterlockSet m1 : 2|1@1+ (1,0) [0|0] "" Vector__XXX
 SG_ VCLEFT_hazardButtonPressed m0 : 3|1@1+ (1,0) [0|0] "" Vector__XXX
 SG_ VCLEFT_swcLeftTiltRight m1 : 3|2@1+ (1,0) [0|0] "" Vector__XXX
 SG_ VCLEFT_brakeSwitchPressed m0 : 4|1@1+ (1,0) [0|0] "" Vector__XXX
 SG_ VCLEFT_rightMirrorTilt m0 : 5|3@1+ (1,0) [0|0] "" Vector__XXX
 SG_ VCLEFT_swcLeftPressed m1 : 5|2@1+ (1,0) [0|0] "" Vector__XXX
 SG_ VCLEFT_frontSeatTrackBack m0 : 8|2@1+ (1,0) [0|0] "" Vector__XXX
 SG_ VCLEFT_swcRightTiltLeft m1 : 8|2@1+ (1,0) [0|0] "" Vector__XXX
 SG_ VCLEFT_frontSeatTrackForward m0 : 10|2@1+ (1,0) [0|0] "" Vector__XXX
 SG_ VCLEFT_swcRightTiltRight m1 : 10|2@1+ (1,0) [0|0] "" Vector__XXX
 SG_ VCLEFT_frontSeatTiltDown m0 : 12|2@1+ (1,0) [0|0] "" Vector__XXX
 SG_ VCLEFT_swcRightPressed m1 : 12|2@1+ (1,0) [0|0] "" Vector__XXX
 SG_ VCLEFT_frontSeatTiltUp m0 : 14|2@1+ (1,0) [0|0] "" Vector__XXX
 SG_ VCLEFT_swcLeftTiltLeft m1 : 14|2@1+ (1,0) [0|0] "" Vector__XXX
 SG_ VCLEFT_frontSeatLiftDown m0 : 16|2@1+ (1,0) [0|0] "" Vector__XXX
 SG_ VCLEFT_swcLeftScrollTicks m1 : 16|6@1- (1,0) [0|0] "" Vector__XXX
 SG_ VCLEFT_frontSeatLiftUp m0 : 18|2@1+ (1,0) [0|0] "" Vector__XXX
 SG_ VCLEFT_frontSeatBackrestBack m0 : 20|2@1+ (1,0) [0|0] "" Vector__XXX
 SG_ VCLEFT_frontSeatBackrestForward m0 : 22|2@1+ (1,0) [0|0] "" Vector__XXX
 SG_ VCLEFT_frontSeatLumbarDown m0 : 24|2@1+ (1,0) [0|0] "" Vector__XXX
 SG_ VCLEFT_swcRightScrollTicks m1 : 24|6@1- (1,0) [0|0] "" Vector__XXX
 SG_ VCLEFT_frontSeatLumbarUp m0 : 26|2@1+ (1,0) [0|0] "" Vector__XXX
 SG_ VCLEFT_frontSeatLumbarIn m0 : 28|2@1+ (1,0) [0|0] "" Vector__XXX
 SG_ VCLEFT_frontSeatLumbarOut m0 : 30|2@1+ (1,0) [0|0] "" Vector__XXX
 SG_ VCLEFT_btnWindowSwPackUpLF m0 : 32|1@1+ (1,0) [0|0] "" Vector__XXX
 SG_ VCLEFT_btnWindowUpLR m1 : 32|1@1+ (1,0) [0|0] "" Vector__XXX
 SG_ VCLEFT_btnWindowAutoUpLR m1 : 33|1@1+ (1,0) [0|0] "" Vector__XXX
 SG_ VCLEFT_btnWindowSwPackAutoUpLF m0 : 33|1@1+ (1,0) [0|0] "" Vector__XXX
 SG_ VCLEFT_btnWindowDownLR m1 : 34|1@1+ (1,0) [0|0] "" Vector__XXX
 SG_ VCLEFT_btnWindowSwPackDownLF m0 : 34|1@1+ (1,0) [0|0] "" Vector__XXX
 SG_ VCLEFT_btnWindowAutoDownLR m1 : 35|1@1+ (1,0) [0|0] "" Vector__XXX
 SG_ VCLEFT_btnWindowSwPackAutoDownLF m0 : 35|1@1+ (1,0) [0|0] "" Vector__XXX
 SG_ VCLEFT_2RowSeatReclineSwitch m1 : 36|1@1+ (1,0) [0|0] "" Vector__XXX
 SG_ VCLEFT_btnWindowSwPackUpLR m0 : 36|1@1+ (1,0) [0|0] "" Vector__XXX
 SG_ VCLEFT_2RowSeatCenterSwitch m1 : 37|1@1+ (1,0) [0|0] "" Vector__XXX
 SG_ VCLEFT_btnWindowSwPackAutoUpLR m0 : 37|1@1+ (1,0) [0|0] "" Vector__XXX
 SG_ VCLEFT_2RowSeatLeftFoldFlatSwitch m1 : 38|1@1+ (1,0) [0|0] "" Vector__XXX
 SG_ VCLEFT_btnWindowSwPackDownLR m0 : 38|1@1+ (1,0) [0|0] "" Vector__XXX
 SG_ VCLEFT_2RowSeatRightFoldFlatSwitch m1 : 39|1@1+ (1,0) [0|0] "" Vector__XXX
 SG_ VCLEFT_btnWindowSwPackAutoDownLR m0 : 39|1@1+ (1,0) [0|0] "" Vector__XXX
 SG_ VCLEFT_2RowSeatBothFoldFlatSwitch m1 : 40|1@1+ (1,0) [0|0] "" Vector__XXX
 SG_ VCLEFT_btnWindowSwPackUpRF m0 : 40|1@1+ (1,0) [0|0] "" Vector__XXX
 SG_ VCLEFT_btnWindowSwPackAutoUpRF m0 : 41|1@1+ (1,0) [0|0] "" Vector__XXX
 SG_ VCLEFT_swcLeftDoublePress m1 : 41|1@1+ (1,0) [0|0] "" Vector__XXX
 SG_ VCLEFT_btnWindowSwPackDownRF m0 : 42|1@1+ (1,0) [0|0] "" Vector__XXX
 SG_ VCLEFT_swcRightDoublePress m1 : 42|1@1+ (1,0) [0|0] "" Vector__XXX
 SG_ VCLEFT_2RowSeatBackrestFoldSwitch m1 : 43|1@1+ (1,0) [0|0] "" Vector__XXX
 SG_ VCLEFT_btnWindowSwPackAutoDownRF m0 : 43|1@1+ (1,0) [0|0] "" Vector__XXX
 SG_ VCLEFT_btnWindowSwPackUpRR m0 : 44|1@1+ (1,0) [0|0] "" Vector__XXX
 SG_ VCLEFT_btnWindowSwPackAutoUpRR m0 : 45|1@1+ (1,0) [0|0] "" Vector__XXX
 SG_ VCLEFT_btnWindowSwPackDownRR m0 : 46|1@1+ (1,0) [0|0] "" Vector__XXX
 SG_ VCLEFT_btnWindowSwPackAutoDownRR m0 : 47|1@1+ (1,0) [0|0] "" Vector__XXX
 SG_ VCLEFT_frontBuckleSwitch m0 : 48|2@1+ (1,0) [0|0] "" Vector__XXX
 SG_ VCLEFT_frontOccupancySwitch m0 : 50|2@1+ (1,0) [0|0] "" Vector__XXX
 SG_ VCLEFT_rearLeftBuckleSwitch m0 : 52|2@1+ (1,0) [0|0] "" Vector__XXX
 SG_ VCLEFT_rearCenterOccupancySwitch m0 : 54|2@1+ (1,0) [0|0] "" Vector__XXX
 SG_ VCLEFT_rearLeftOccupancySwitch m0 : 56|2@1+ (1,0) [0|0] "" Vector__XXX
 SG_ VCLEFT_rearRightOccupancySwitch m0 : 58|2@1+ (1,0) [0|0] "" Vector__XXX
 SG_ VCLEFT_brakePressed m0 : 60|1@1+ (1,0) [0|0] "" Vector__XXX
 SG_ VCLEFT_rearHVACButtonPressed m0 : 61|1@1+ (1,0) [0|0] "" Vector__XXX
 SG_ VCLEFT_frontSeatResistiveOccupancy m1 : 62|2@1+ (1,0) [0|0] "" Vector__XXX
 SG_ VCLEFT_rearCenterBuckleSwitch m0 : 62|2@1+ (1,0) [0|0] "" Vector__XXX

BO_ 963 VCRIGHT_switchStatus: 8 Vector__XXX
 SG_ VCRIGHT_switchStatusIndex M : 0|1@1+ (1,0) [0|0] "" Vector__XXX
 SG_ VCRIGHT_trunkExtReleasePressedPersist m1 : 1|1@1+ (1,0) [0|0] "" Vector__XXX
 SG_ VCRIGHT_frontSeatTrackBack m1 : 2|2@1+ (1,0) [0|0] "" Vector__XXX
 SG_ VCRIGHT_frontSeatTrackForward m1 : 4|2@1+ (1,0) [0|0] "" Vector__XXX
 SG_ VCRIGHT_frontSeatTiltDown m1 : 6|2@1+ (1,0) [0|0] "" Vector__XXX
 SG_ VCRIGHT_frontSeatTiltUp m1 : 8|2@1+ (1,0) [0|0] "" Vector__XXX
 SG_ VCRIGHT_frontSeatLiftDown m1 : 10|2@1+ (1,0) [0|0] "" Vector__XXX
 SG_ VCRIGHT_frontSeatLiftUp m1 : 12|2@1+ (1,0) [0|0] "" Vector__XXX
 SG_ VCRIGHT_frontSeatBackrestBack m1 : 14|2@1+ (1,0) [0|0] "" Vector__XXX
 SG_ VCRIGHT_frontSeatBackrestForward m1 : 16|2@1+ (1,0) [0|0] "" Vector__XXX
 SG_ VCRIGHT_frontSeatLumbarDown m1 : 18|2@1+ (1,0) [0|0] "" Vector__XXX
 SG_ VCRIGHT_frontSeatLumbarUp m1 : 20|2@1+ (1,0) [0|0] "" Vector__XXX
 SG_ VCRIGHT_frontSeatLumbarIn m1 : 22|2@1+ (1,0) [0|0] "" Vector__XXX
 SG_ VCRIGHT_btnWindowUpRF m0 : 24|1@1+ (1,0) [0|0] "" Vector__XXX
 SG_ VCRIGHT_frontSeatLumbarOut m1 : 24|2@1+ (1,0) [0|0] "" Vector__XXX
 SG_ VCRIGHT_btnWindowAutoUpRF m0 : 25|1@1+ (1,0) [0|0] "" Vector__XXX
 SG_ VCRIGHT_2RowSeatReclineSwitch m1 : 26|1@1+ (1,0) [0|0] "" Vector__XXX
 SG_ VCRIGHT_btnWindowDownRF m0 : 26|1@1+ (1,0) [0|0] "" Vector__XXX
 SG_ VCRIGHT_2RowSeatBackrestFoldSwitch m1 : 27|1@1+ (1,0) [0|0] "" Vector__XXX
 SG_ VCRIGHT_btnWindowAutoDownRF m0 : 27|1@1+ (1,0) [0|0] "" Vector__XXX
 SG_ VCRIGHT_btnWindowUpRR m0 : 28|1@1+ (1,0) [0|0] "" Vector__XXX
 SG_ VCRIGHT_btnWindowAutoUpRR m0 : 29|1@1+ (1,0) [0|0] "" Vector__XXX
 SG_ VCRIGHT_btnWindowDownRR m0 : 30|1@1+ (1,0) [0|0] "" Vector__XXX
 SG_ VCRIGHT_btnWindowAutoDownRR m0 : 31|1@1+ (1,0) [0|0] "" Vector__XXX
 SG_ VCRIGHT_btnWindowSwPackUpLF m0 : 32|1@1+ (1,0) [0|0] "" Vector__XXX
 SG_ VCRIGHT_frontHandlePWM m1 : 32|7@1+ (1,0) [0|0] "" Vector__XXX
 SG_ VCRIGHT_btnWindowSwPackAutoUpLF m0 : 33|1@1+ (1,0) [0|0] "" Vector__XXX
 SG_ VCRIGHT_btnWindowSwPackDownLF m0 : 34|1@1+ (1,0) [0|0] "" Vector__XXX
 SG_ VCRIGHT_btnWindowSwPackAutoDwnLF m0 : 35|1@1+ (1,0) [0|0] "" Vector__XXX
 SG_ VCRIGHT_btnWindowSwPackUpLR m0 : 36|1@1+ (1,0) [0|0] "" Vector__XXX
 SG_ VCRIGHT_btnWindowSwPackAutoUpLR m0 : 37|1@1+ (1,0) [0|0] "" Vector__XXX
 SG_ VCRIGHT_btnWindowSwPackDownLR m0 : 38|1@1+ (1,0) [0|0] "" Vector__XXX
 SG_ VCRIGHT_btnWindowSwPackAutoDwnLR m0 : 39|1@1+ (1,0) [0|0] "" Vector__XXX
 SG_ VCRIGHT_hvacHeatingAllowedLeft m1 : 39|1@1+ (1,0) [0|0] "" Vector__XXX
 SG_ VCRIGHT_frontBuckleSwitch m0 : 40|2@1+ (1,0) [0|0] "" Vector__XXX
 SG_ VCRIGHT_rearHandlePWM m1 : 40|7@1+ (1,0) [0|0] "" Vector__XXX
 SG_ VCRIGHT_frontOccupancySwitch m0 : 42|2@1+ (1,0) [0|0] "" Vector__XXX
 SG_ VCRIGHT_rearCenterBuckleSwitch m0 : 44|2@1+ (1,0) [0|0] "" Vector__XXX
 SG_ VCRIGHT_rearRightBuckleSwitch m0 : 46|2@1+ (1,0) [0|0] "" Vector__XXX
 SG_ VCRIGHT_gloveboxLightCurrent m1 : 47|5@1+ (2,0) [0|0] "" Vector__XXX
 SG_ VCRIGHT_trunkExtReleasePressed m0 : 48|1@1+ (1,0) [0|0] "" Vector__XXX
 SG_ VCRIGHT_btnWindowSwPackUpRR m0 : 49|1@1+ (1,0) [0|0] "" Vector__XXX
 SG_ VCRIGHT_btnWindowSwPackAutoUpRR m0 : 50|1@1+ (1,0) [0|0] "" Vector__XXX
 SG_ VCRIGHT_btnWindowSwPackDownRR m0 : 51|1@1+ (1,0) [0|0] "" Vector__XXX
 SG_ VCRIGHT_btnWindowSwPackAutoDwnRR m0 : 52|1@1+ (1,0) [0|0] "" Vector__XXX
 SG_ VCRIGHT_liftgateShutfaceSwitchPressed m0 : 53|1@1+ (1,0) [0|0] "" Vector__XXX
 SG_ VCRIGHT_frontSeatResistiveOccupancy m1 : 54|2@1+ (1,0) [0|0] "" Vector__XXX
 SG_ VCRIGHT_rearRightOccupancySwitch m0 : 54|2@1+ (1,0) [0|0] "" Vector__XXX
 SG_ VCRIGHT_3RowLeftOccupancySwitch m0 : 56|2@1+ (1,0) [0|0] "" Vector__XXX
 SG_ VCRIGHT_3RowRightOccupancySwitch m0 : 58|2@1+ (1,0) [0|0] "" Vector__XXX
 SG_ VCRIGHT_hvacHeatingAllowedRight m1 : 59|1@1+ (1,0) [0|0] "" Vector__XXX
 SG_ VCRIGHT_3RowLeftBuckleSwitch m0 : 60|2@1+ (1,0) [0|0] "" Vector__XXX
 SG_ VCRIGHT_3RowRightBuckleSwitch m0 : 62|2@1+ (1,0) [0|0] "" Vector__XXX

BO_ 964 PCS_info: 8 Vector__XXX
 SG_ PCS_infoIndex M : 0|8@1+ (1,0) [0|0] "" Vector__XXX
 SG_ PCS_appGitHash m17 : 8|56@1+ (1,0) [0|0] "" Vector__XXX
 SG_ PCS_bootGitHash m18 : 8|56@1+ (1,0) [0|0] "" Vector__XXX
 SG_ PCS_bootUdsProtoVersion m20 : 8|8@1+ (1,0) [0|0] "" Vector__XXX
 SG_ PCS_buildType m10 : 8|8@1+ (1,0) [0|0] "" Vector__XXX
 SG_ PCS_partNumChar01 m25 : 8|8@1+ (1,0) [0|0] "" Vector__XXX
 SG_ PCS_partNumChar08 m26 : 8|8@1+ (1,0) [0|0] "" Vector__XXX
 SG_ PCS_partNumChar15 m27 : 8|8@1+ (1,0) [0|0] "" Vector__XXX
 SG_ PCS_platformType m13 : 8|8@1+ (1,0) [0|0] "" Vector__XXX
 SG_ PCS_serialNumChar01 m29 : 8|8@1+ (1,0) [0|0] "" Vector__XXX
 SG_ PCS_serialNumChar08 m30 : 8|8@1+ (1,0) [0|0] "" Vector__XXX
 SG_ PCS_buildConfigId m10 : 16|16@1+ (1,0) [0|0] "" Vector__XXX
 SG_ PCS_partNumChar02 m25 : 16|8@1+ (1,0) [0|0] "" Vector__XXX
 SG_ PCS_partNumChar09 m26 : 16|8@1+ (1,0) [0|0] "" Vector__XXX
 SG_ PCS_partNumChar16 m27 : 16|8@1+ (1,0) [0|0] "" Vector__XXX
 SG_ PCS_pcbaId m11 : 16|8@1+ (1,0) [0|0] "" Vector__XXX
 SG_ PCS_serialNumChar02 m29 : 16|8@1+ (1,0) [0|0] "" Vector__XXX
 SG_ PCS_serialNumChar09 m30 : 16|8@1+ (1,0) [0|0] "" Vector__XXX
 SG_ PCS_assemblyId m11 : 24|8@1+ (1,0) [0|0] "" Vector__XXX
 SG_ PCS_partNumChar03 m25 : 24|8@1+ (1,0) [0|0] "" Vector__XXX
 SG_ PCS_partNumChar10 m26 : 24|8@1+ (1,0) [0|0] "" Vector__XXX
 SG_ PCS_partNumChar17 m27 : 24|8@1+ (1,0) [0|0] "" Vector__XXX
 SG_ PCS_serialNumChar03 m29 : 24|8@1+ (1,0) [0|0] "" Vector__XXX
 SG_ PCS_serialNumChar10 m30 : 24|8@1+ (1,0) [0|0] "" Vector__XXX
 SG_ PCS_appCrc m13 : 32|32@1+ (1,0) [0|0] "" Vector__XXX
 SG_ PCS_bootCrc m20 : 32|32@1+ (1,0) [0|0] "" Vector__XXX
 SG_ PCS_cpu2AppCrc m16 : 32|32@1+ (1,0) [0|0] "" Vector__XXX
 SG_ PCS_hardwareId m10 : 32|16@1+ (1,0) [0|0] "" Vector__XXX
 SG_ PCS_partNumChar04 m25 : 32|8@1+ (1,0) [0|0] "" Vector__XXX
 SG_ PCS_partNumChar11 m26 : 32|8@1+ (1,0) [0|0] "" Vector__XXX
 SG_ PCS_partNumChar18 m27 : 32|8@1+ (1,0) [0|0] "" Vector__XXX
 SG_ PCS_serialNumChar04 m29 : 32|8@1+ (1,0) [0|0] "" Vector__XXX
 SG_ PCS_serialNumChar11 m30 : 32|8@1+ (1,0) [0|0] "" Vector__XXX
 SG_ PCS_usageId m11 : 32|16@1+ (1,0) [0|0] "" Vector__XXX
 SG_ PCS_partNumChar05 m25 : 40|8@1+ (1,0) [0|0] "" Vector__XXX
 SG_ PCS_partNumChar12 m26 : 40|8@1+ (1,0) [0|0] "" Vector__XXX
 SG_ PCS_partNumChar19 m27 : 40|8@1+ (1,0) [0|0] "" Vector__XXX
 SG_ PCS_serialNumChar05 m29 : 40|8@1+ (1,0) [0|0] "" Vector__XXX
 SG_ PCS_serialNumChar12 m30 : 40|8@1+ (1,0) [0|0] "" Vector__XXX
 SG_ PCS_componentId m10 : 48|16@1+ (1,0) [0|0] "" Vector__XXX
 SG_ PCS_partNumChar06 m25 : 48|8@1+ (1,0) [0|0] "" Vector__XXX
 SG_ PCS_partNumChar13 m26 : 48|8@1+ (1,0) [0|0] "" Vector__XXX
 SG_ PCS_partNumChar20 m27 : 48|8@1+ (1,0) [0|0] "" Vector__XXX
 SG_ PCS_serialNumChar06 m29 : 48|8@1+ (1,0) [0|0] "" Vector__XXX
 SG_ PCS_serialNumChar13 m30 : 48|8@1+ (1,0) [0|0] "" Vector__XXX
 SG_ PCS_subUsageId m11 : 48|16@1+ (1,0) [0|0] "" Vector__XXX
 SG_ PCS_partNumChar07 m25 : 56|8@1+ (1,0) [0|0] "" Vector__XXX
 SG_ PCS_partNumChar14 m26 : 56|8@1+ (1,0) [0|0] "" Vector__XXX
 SG_ PCS_serialNumChar07 m29 : 56|8@1+ (1,0) [0|0] "" Vector__XXX
 SG_ PCS_serialNumChar14 m30 : 56|8@1+ (1,0) [0|0] "" Vector__XXX

BO_ 965 DIR_alertMatrix3: 8 Vector__XXX
 SG_ DIR_a133_capacitorOT : 4|1@1+ (1,0) [0|0] "" Vector__XXX
 SG_ DIR_a134_wheelSpeedIrrational : 5|1@1+ (1,0) [0|0] "" Vector__XXX
 SG_ DIR_a136_spiError : 7|1@1+ (1,0) [0|0] "" Vector__XXX
 SG_ DIR_a142_highLashAngle : 13|1@1+ (1,0) [0|0] "" Vector__XXX
 SG_ DIR_a144_configMismatch : 15|1@1+ (1,0) [0|0] "" Vector__XXX
 SG_ DIR_a147_highTorqueWearLimit : 18|1@1+ (1,0) [0|0] "" Vector__XXX
 SG_ DIR_a148_burnInCycleEnded : 19|1@1+ (1,0) [0|0] "" Vector__XXX
 SG_ DIR_a149_oilPumpFailure : 20|1@1+ (1,0) [0|0] "" Vector__XXX
 SG_ DIR_a150_busVD : 21|1@1+ (1,0) [0|0] "" Vector__XXX
 SG_ DIR_a151_shockTorqueLimiter : 22|1@1+ (1,0) [0|0] "" Vector__XXX
 SG_ DIR_a152_linError : 23|1@1+ (1,0) [0|0] "" Vector__XXX
 SG_ DIR_a153_oilPumpDiagnostics : 24|1@1+ (1,0) [0|0] "" Vector__XXX
 SG_ DIR_a154_resolver : 25|1@1+ (1,0) [0|0] "" Vector__XXX
 SG_ DIR_a155_vcfrontMIA : 26|1@1+ (1,0) [0|0] "" Vector__XXX
 SG_ DIR_a156_currentObserver : 27|1@1+ (1,0) [0|0] "" Vector__XXX
 SG_ DIR_a157_rcmMIA : 28|1@1+ (1,0) [0|0] "" Vector__XXX
 SG_ DIR_a158_ibstMIA : 29|1@1+ (1,0) [0|0] "" Vector__XXX
 SG_ DIR_a160_busVoltageAnomaly : 31|1@1+ (1,0) [0|0] "" Vector__XXX
 SG_ DIR_a161_epas3pMIA : 32|1@1+ (1,0) [0|0] "" Vector__XXX
 SG_ DIR_a162_endOfLifetimeBurnIn : 33|1@1+ (1,0) [0|0] "" Vector__XXX
 SG_ DIR_a172_statorOilTempOT : 43|1@1+ (1,0) [0|0] "" Vector__XXX
 SG_ DIR_a173_ascFdbkDiagnostic : 44|1@1+ (1,0) [0|0] "" Vector__XXX
 SG_ DIR_a174_unitMayNotRestart : 45|1@1+ (1,0) [0|0] "" Vector__XXX
 SG_ DIR_a176_safetyICFault : 47|1@1+ (1,0) [0|0] "" Vector__XXX
 SG_ DIR_a177_fluxReferenceCorrected : 48|1@1+ (1,0) [0|0] "" Vector__XXX

BO_ 968 EPBL_alertMatrix: 8 Vector__XXX
 SG_ EPBL_matrixIndex M : 0|4@1+ (1,0) [0|0] "" Vector__XXX
 SG_ EPBL_a001_WatchdogReset m0 : 4|1@1+ (1,0) [0|0] "" Vector__XXX
 SG_ EPBL_a061_XCPConnected m1 : 4|1@1+ (1,0) [0|0] "" Vector__XXX
 SG_ EPBL_a121_nDriveFault m2 : 4|1@1+ (1,0) [0|0] "" Vector__XXX
 SG_ EPBL_a181_TooSteepGradeToPark m3 : 4|1@1+ (1,0) [0|0] "" Vector__XXX
 SG_ EPBL_a241_diOutputLocked m4 : 4|1@1+ (1,0) [0|0] "" Vector__XXX
 SG_ EPBL_a301_oocSpeedViolation m5 : 4|1@1+ (1,0) [0|0] "" Vector__XXX
 SG_ EPBL_a361_espBrakeSwitchInvalid m6 : 4|1@1+ (1,0) [0|0] "" Vector__XXX
 SG_ EPBL_a002_PowerLossReset m0 : 5|1@1+ (1,0) [0|0] "" Vector__XXX
 SG_ EPBL_a062_XCPWasConnected m1 : 5|1@1+ (1,0) [0|0] "" Vector__XXX
 SG_ EPBL_a122_Oc m2 : 5|1@1+ (1,0) [0|0] "" Vector__XXX
 SG_ EPBL_a182_OneEPBAppliedUnsecEnv m3 : 5|1@1+ (1,0) [0|0] "" Vector__XXX
 SG_ EPBL_a242_hvOutputLocked m4 : 5|1@1+ (1,0) [0|0] "" Vector__XXX
 SG_ EPBL_a302_csmLongRelease m5 : 5|1@1+ (1,0) [0|0] "" Vector__XXX
 SG_ EPBL_a362_ibstPressedEspNotPressedMismatch m6 : 5|1@1+ (1,0) [0|0] "" Vector__XXX
 SG_ EPBL_a003_SWAssertion m0 : 6|1@1+ (1,0) [0|0] "" Vector__XXX
 SG_ EPBL_a063_SwitchFault m1 : 6|1@1+ (1,0) [0|0] "" Vector__XXX
 SG_ EPBL_a123_Uc m2 : 6|1@1+ (1,0) [0|0] "" Vector__XXX
 SG_ EPBL_a183_cdpNotAvailable m3 : 6|1@1+ (1,0) [0|0] "" Vector__XXX
 SG_ EPBL_a243_bdwUnavailable m4 : 6|1@1+ (1,0) [0|0] "" Vector__XXX
 SG_ EPBL_a303_clampingOccuredEarly m5 : 6|1@1+ (1,0) [0|0] "" Vector__XXX
 SG_ EPBL_a363_ibstNotPressedEspPressedMismatch m6 : 6|1@1+ (1,0) [0|0] "" Vector__XXX
 SG_ EPBL_a064_busSleepReqTimeout m1 : 7|1@1+ (1,0) [0|0] "" Vector__XXX
 SG_ EPBL_a124_calOutOfBounds m2 : 7|1@1+ (1,0) [0|0] "" Vector__XXX
 SG_ EPBL_a184_dynamicParkAbort m3 : 7|1@1+ (1,0) [0|0] "" Vector__XXX
 SG_ EPBL_a244_WinchModeActive m4 : 7|1@1+ (1,0) [0|0] "" Vector__XXX
 SG_ EPBL_a304_rearSeatControllerEFuseTrip m5 : 7|1@1+ (1,0) [0|0] "" Vector__XXX
 SG_ EPBL_a364_espMasterCylCompOverThreshold m6 : 7|1@1+ (1,0) [0|0] "" Vector__XXX
 SG_ EPBL_a005_CANTXError m0 : 8|1@1+ (1,0) [0|0] "" Vector__XXX
 SG_ EPBL_a125_IdleVMismatch m2 : 8|1@1+ (1,0) [0|0] "" Vector__XXX
 SG_ EPBL_a185_summonAborted m3 : 8|1@1+ (1,0) [0|0] "" Vector__XXX
 SG_ EPBL_a245_serviceModeActive m4 : 8|1@1+ (1,0) [0|0] "" Vector__XXX
 SG_ EPBL_a305_premiumAmpEFuseTrip m5 : 8|1@1+ (1,0) [0|0] "" Vector__XXX
 SG_ EPBL_a365_TooSteepToParkWithTrailerWarning m6 : 8|1@1+ (1,0) [0|0] "" Vector__XXX
 SG_ EPBL_a006_CANTX_cyclicError m0 : 9|1@1+ (1,0) [0|0] "" Vector__XXX
 SG_ EPBL_a126_MotorNVoltLow m2 : 9|1@1+ (1,0) [0|0] "" Vector__XXX
 SG_ EPBL_a186_externalParkAbort m3 : 9|1@1+ (1,0) [0|0] "" Vector__XXX
 SG_ EPBL_a246_idleFaultApply m4 : 9|1@1+ (1,0) [0|0] "" Vector__XXX
 SG_ EPBL_a366_TooSteepToParkWithTrailerUnSecEnv m6 : 9|1@1+ (1,0) [0|0] "" Vector__XXX
 SG_ EPBL_a127_MotorNVoltHigh m2 : 10|1@1+ (1,0) [0|0] "" Vector__XXX
 SG_ EPBL_a187_cdpDynamic m3 : 10|1@1+ (1,0) [0|0] "" Vector__XXX
 SG_ EPBL_a247_csmDynamicApplyRetry m4 : 10|1@1+ (1,0) [0|0] "" Vector__XXX
 SG_ EPBL_a128_MotorPVoltHigh m2 : 11|1@1+ (1,0) [0|0] "" Vector__XXX
 SG_ EPBL_a188_epbDynamic m3 : 11|1@1+ (1,0) [0|0] "" Vector__XXX
 SG_ EPBL_a248_csmDynamicApplyFailed m4 : 11|1@1+ (1,0) [0|0] "" Vector__XXX
 SG_ EPBL_a129_ICR_MIA m2 : 12|1@1+ (1,0) [0|0] "" Vector__XXX
 SG_ EPBL_a189_epbDynamicParkCanceled m3 : 12|1@1+ (1,0) [0|0] "" Vector__XXX
 SG_ EPBL_a249_idleFaultRelease m4 : 12|1@1+ (1,0) [0|0] "" Vector__XXX
 SG_ EPBL_a190_csmApplyDegraded m3 : 13|1@1+ (1,0) [0|0] "" Vector__XXX
 SG_ EPBL_a250_WinchModeCanceled m4 : 13|1@1+ (1,0) [0|0] "" Vector__XXX
 SG_ EPBL_a370_imposterDetected m6 : 13|1@1+ (1,0) [0|0] "" Vector__XXX
 SG_ EPBL_a191_csmReleaseDegraded m3 : 14|1@1+ (1,0) [0|0] "" Vector__XXX
 SG_ EPBL_a251_currentVarianceHigh m4 : 14|1@1+ (1,0) [0|0] "" Vector__XXX
 SG_ EPBL_a012_CPUReset m0 : 15|1@1+ (1,0) [0|0] "" Vector__XXX
 SG_ EPBL_a252_winchModePending m4 : 15|1@1+ (1,0) [0|0] "" Vector__XXX
 SG_ EPBL_a013_AlertManagerFault m0 : 16|1@1+ (1,0) [0|0] "" Vector__XXX
 SG_ EPBL_a253_esmReleaseBlocked m4 : 16|1@1+ (1,0) [0|0] "" Vector__XXX
 SG_ EPBL_a134_NvOv m2 : 17|1@1+ (1,0) [0|0] "" Vector__XXX
 SG_ EPBL_a254_showStalkParkButtonFaultOnUi m4 : 17|1@1+ (1,0) [0|0] "" Vector__XXX
 SG_ EPBL_a015_NVMMError m0 : 18|1@1+ (1,0) [0|0] "" Vector__XXX
 SG_ EPBL_a135_NvUv m2 : 18|1@1+ (1,0) [0|0] "" Vector__XXX
 SG_ EPBL_a195_parkForDriverIsLeaving m3 : 18|1@1+ (1,0) [0|0] "" Vector__XXX
 SG_ EPBL_a016_NVMMRecordError m0 : 19|1@1+ (1,0) [0|0] "" Vector__XXX
 SG_ EPBL_a136_PvOv m2 : 19|1@1+ (1,0) [0|0] "" Vector__XXX
 SG_ EPBL_a196_freeRollModeActive m3 : 19|1@1+ (1,0) [0|0] "" Vector__XXX
 SG_ EPBL_a256_epbSystemApply m4 : 19|1@1+ (1,0) [0|0] "" Vector__XXX
 SG_ EPBL_a137_PvUv m2 : 20|1@1+ (1,0) [0|0] "" Vector__XXX
 SG_ EPBL_a197_freeRollModeAtSpeed m3 : 20|1@1+ (1,0) [0|0] "" Vector__XXX
 SG_ EPBL_a138_NvmDualFailure m2 : 21|1@1+ (1,0) [0|0] "" Vector__XXX
 SG_ EPBL_a198_holdClampComplete m3 : 21|1@1+ (1,0) [0|0] "" Vector__XXX
 SG_ EPBL_a139_NvmRedundancyLoss m2 : 22|1@1+ (1,0) [0|0] "" Vector__XXX
 SG_ EPBL_a140_NvmSlowWrite m2 : 23|1@1+ (1,0) [0|0] "" Vector__XXX
 SG_ EPBL_a200_PmUnparkNotAllowed m3 : 23|1@1+ (1,0) [0|0] "" Vector__XXX
 SG_ EPBL_a021_TaskSchedulerError m0 : 24|1@1+ (1,0) [0|0] "" Vector__XXX
 SG_ EPBL_a081_APP_MIA m1 : 24|1@1+ (1,0) [0|0] "" Vector__XXX
 SG_ EPBL_a141_invalidState m2 : 24|1@1+ (1,0) [0|0] "" Vector__XXX
 SG_ EPBL_a261_winchModeWithoutSteering m4 : 24|1@1+ (1,0) [0|0] "" Vector__XXX
 SG_ EPBL_a022_TaskInitError m0 : 25|1@1+ (1,0) [0|0] "" Vector__XXX
 SG_ EPBL_a082_VCRIGHT_IPC_MIA m1 : 25|1@1+ (1,0) [0|0] "" Vector__XXX
 SG_ EPBL_a202_remoteEpbConfigIncompatible m3 : 25|1@1+ (1,0) [0|0] "" Vector__XXX
 SG_ EPBL_a262_cannotPrepareWinchMode m4 : 25|1@1+ (1,0) [0|0] "" Vector__XXX
 SG_ EPBL_a083_VCLEFT_IPC_MIA m1 : 26|1@1+ (1,0) [0|0] "" Vector__XXX
 SG_ EPBL_a203_hwBrakeTypeMismatch m3 : 26|1@1+ (1,0) [0|0] "" Vector__XXX
 SG_ EPBL_a263_epbRecoveryPark m4 : 26|1@1+ (1,0) [0|0] "" Vector__XXX
 SG_ EPBL_a084_TPMS_MIA m1 : 27|1@1+ (1,0) [0|0] "" Vector__XXX
 SG_ EPBL_a264_winchModeDeactivated m4 : 27|1@1+ (1,0) [0|0] "" Vector__XXX
 SG_ EPBL_a085_CCCM_MIA m1 : 28|1@1+ (1,0) [0|0] "" Vector__XXX
 SG_ EPBL_a086_VCBATT_MIA m1 : 29|1@1+ (1,0) [0|0] "" Vector__XXX
 SG_ EPBL_a087_DIREL_MIA m1 : 30|1@1+ (1,0) [0|0] "" Vector__XXX
 SG_ EPBL_a088_DIRER_MIA m1 : 31|1@1+ (1,0) [0|0] "" Vector__XXX
 SG_ EPBL_a029_CoreDump m0 : 32|1@1+ (1,0) [0|0] "" Vector__XXX
 SG_ EPBL_a089_IBST_MIA m1 : 32|1@1+ (1,0) [0|0] "" Vector__XXX
 SG_ EPBL_a030_ECULogUploadRequest m0 : 33|1@1+ (1,0) [0|0] "" Vector__XXX
 SG_ EPBL_a090_APS_MIA m1 : 33|1@1+ (1,0) [0|0] "" Vector__XXX
 SG_ EPBL_a210_parkForDriverIsLeavingDebug m3 : 33|1@1+ (1,0) [0|0] "" Vector__XXX
 SG_ EPBL_a330_parkForApIsLeaving m5 : 33|1@1+ (1,0) [0|0] "" Vector__XXX
 SG_ EPBL_a031_UDSActive m0 : 34|1@1+ (1,0) [0|0] "" Vector__XXX
 SG_ EPBL_a091_CMPD_MIA m1 : 34|1@1+ (1,0) [0|0] "" Vector__XXX
 SG_ EPBL_a092_VCSEATD_MIA m1 : 35|1@1+ (1,0) [0|0] "" Vector__XXX
 SG_ EPBL_a272_vhclPwrStateMsmtch m4 : 35|1@1+ (1,0) [0|0] "" Vector__XXX
 SG_ EPBL_a093_VCSEATP_MIA m1 : 36|1@1+ (1,0) [0|0] "" Vector__XXX
 SG_ EPBL_a094_EPAS3P_MIA m1 : 37|1@1+ (1,0) [0|0] "" Vector__XXX
 SG_ EPBL_a095_CHG_MIA m1 : 38|1@1+ (1,0) [0|0] "" Vector__XXX
 SG_ EPBL_a096_OCS1P_MIA m1 : 39|1@1+ (1,0) [0|0] "" Vector__XXX
 SG_ EPBL_a216_SPI_MIA_debugData1 m3 : 39|1@1+ (1,0) [0|0] "" Vector__XXX
 SG_ EPBL_a097_CMP_MIA m1 : 40|1@1+ (1,0) [0|0] "" Vector__XXX
 SG_ EPBL_a217_SPI_MIA_debugData2 m3 : 40|1@1+ (1,0) [0|0] "" Vector__XXX
 SG_ EPBL_a098_DIR_MIA m1 : 41|1@1+ (1,0) [0|0] "" Vector__XXX
 SG_ EPBL_a099_PARK_MIA m1 : 42|1@1+ (1,0) [0|0] "" Vector__XXX
 SG_ EPBL_a100_CANbus_MIA m1 : 43|1@1+ (1,0) [0|0] "" Vector__XXX
 SG_ EPBL_a041_HighCPULoad m0 : 44|1@1+ (1,0) [0|0] "" Vector__XXX
 SG_ EPBL_a101_PM_MIA m1 : 44|1@1+ (1,0) [0|0] "" Vector__XXX
 SG_ EPBL_a042_HighStackUsage m0 : 45|1@1+ (1,0) [0|0] "" Vector__XXX
 SG_ EPBL_a102_PTC_MIA m1 : 45|1@1+ (1,0) [0|0] "" Vector__XXX
 SG_ EPBL_a043_Task1msError m0 : 46|1@1+ (1,0) [0|0] "" Vector__XXX
 SG_ EPBL_a103_CP_MIA m1 : 46|1@1+ (1,0) [0|0] "" Vector__XXX
 SG_ EPBL_a044_Task10msError m0 : 47|1@1+ (1,0) [0|0] "" Vector__XXX
 SG_ EPBL_a104_DAS_MIA m1 : 47|1@1+ (1,0) [0|0] "" Vector__XXX
 SG_ EPBL_a045_Task100msError m0 : 48|1@1+ (1,0) [0|0] "" Vector__XXX
 SG_ EPBL_a105_TAS_MIA m1 : 48|1@1+ (1,0) [0|0] "" Vector__XXX
 SG_ EPBL_a225_epbActiveDecel m3 : 48|1@1+ (1,0) [0|0] "" Vector__XXX
 SG_ EPBL_a046_Task1000msError m0 : 49|1@1+ (1,0) [0|0] "" Vector__XXX
 SG_ EPBL_a106_PCS_MIA m1 : 49|1@1+ (1,0) [0|0] "" Vector__XXX
 SG_ EPBL_a107_BMS_MIA m1 : 50|1@1+ (1,0) [0|0] "" Vector__XXX
 SG_ EPBL_a108_DIF_MIA m1 : 51|1@1+ (1,0) [0|0] "" Vector__XXX
 SG_ EPBL_a109_RCM_MIA m1 : 52|1@1+ (1,0) [0|0] "" Vector__XXX
 SG_ EPBL_a110_GTW_MIA m1 : 53|1@1+ (1,0) [0|0] "" Vector__XXX
 SG_ EPBL_a170_12vOv m2 : 53|1@1+ (1,0) [0|0] "" Vector__XXX
 SG_ EPBL_a350_ensOutOfRange m5 : 53|1@1+ (1,0) [0|0] "" Vector__XXX
 SG_ EPBL_a111_EPBR_MIA m1 : 54|1@1+ (1,0) [0|0] "" Vector__XXX
 SG_ EPBL_a171_12vUv m2 : 54|1@1+ (1,0) [0|0] "" Vector__XXX
 SG_ EPBL_a112_EPBL_MIA m1 : 55|1@1+ (1,0) [0|0] "" Vector__XXX
 SG_ EPBL_a172_SPI_MIA m2 : 55|1@1+ (1,0) [0|0] "" Vector__XXX
 SG_ EPBL_a352_audioCurrentSpikeData m5 : 55|1@1+ (1,0) [0|0] "" Vector__XXX
 SG_ EPBL_a113_UI_MIA m1 : 56|1@1+ (1,0) [0|0] "" Vector__XXX
 SG_ EPBL_a173_hiCurrentMissing m2 : 56|1@1+ (1,0) [0|0] "" Vector__XXX
 SG_ EPBL_a353_missingSpeedUnableToPark m5 : 56|1@1+ (1,0) [0|0] "" Vector__XXX
 SG_ EPBL_a114_ESP_MIA m1 : 57|1@1+ (1,0) [0|0] "" Vector__XXX
 SG_ EPBL_a174_csmReleaseFailed m2 : 57|1@1+ (1,0) [0|0] "" Vector__XXX
 SG_ EPBL_a354_parkedForLowBrakeFluidMode m5 : 57|1@1+ (1,0) [0|0] "" Vector__XXX
 SG_ EPBL_a115_VCSEC_MIA m1 : 58|1@1+ (1,0) [0|0] "" Vector__XXX
 SG_ EPBL_a175_csmReleaseRetry m2 : 58|1@1+ (1,0) [0|0] "" Vector__XXX
 SG_ EPBL_a355_brakeHwAndEpbHwMismatch m5 : 58|1@1+ (1,0) [0|0] "" Vector__XXX
 SG_ EPBL_a116_VCRIGHT_MIA m1 : 59|1@1+ (1,0) [0|0] "" Vector__XXX
 SG_ EPBL_a176_csmApplyFailed m2 : 59|1@1+ (1,0) [0|0] "" Vector__XXX
 SG_ EPBL_a356_parkingForStationaryDetect m5 : 59|1@1+ (1,0) [0|0] "" Vector__XXX
 SG_ EPBL_a057_HVP_MIA m0 : 60|1@1+ (1,0) [0|0] "" Vector__XXX
 SG_ EPBL_a117_VCLEFT_MIA m1 : 60|1@1+ (1,0) [0|0] "" Vector__XXX
 SG_ EPBL_a177_csmApplyRetry m2 : 60|1@1+ (1,0) [0|0] "" Vector__XXX
 SG_ EPBL_a357_brakesTooHotForSlope m5 : 60|1@1+ (1,0) [0|0] "" Vector__XXX
 SG_ EPBL_a058_inputRHighSyncDebug m0 : 61|1@1+ (1,0) [0|0] "" Vector__XXX
 SG_ EPBL_a118_VCFRONT_MIA m1 : 61|1@1+ (1,0) [0|0] "" Vector__XXX
 SG_ EPBL_a178_caliperStateUnknown m2 : 61|1@1+ (1,0) [0|0] "" Vector__XXX
 SG_ EPBL_a358_brakesTooHotForSlopeWithOnlyOneEpb m5 : 61|1@1+ (1,0) [0|0] "" Vector__XXX
 SG_ EPBL_a059_inputResistanceHigh m0 : 62|1@1+ (1,0) [0|0] "" Vector__XXX
 SG_ EPBL_a119_SCCM_MIA m1 : 62|1@1+ (1,0) [0|0] "" Vector__XXX
 SG_ EPBL_a179_epbProblem m2 : 62|1@1+ (1,0) [0|0] "" Vector__XXX
 SG_ EPBL_a060_engineeringBuild m0 : 63|1@1+ (1,0) [0|0] "" Vector__XXX
 SG_ EPBL_a120_DI_DRIVE_MIA m1 : 63|1@1+ (1,0) [0|0] "" Vector__XXX
 SG_ EPBL_a180_dynamicActive m2 : 63|1@1+ (1,0) [0|0] "" Vector__XXX
 SG_ EPBL_a300_leftRightConfusion m4 : 63|1@1+ (1,0) [0|0] "" Vector__XXX
 SG_ EPBL_a360_ibstBrakeSwitchInvalid m5 : 63|1@1+ (1,0) [0|0] "" Vector__XXX

BO_ 969 VCSEC_BLEEndpointInfo: 8 Vector__XXX
 SG_ VCSEC_BLEEndpointInfoIndex M : 0|8@1+ (1,0) [0|0] "" Vector__XXX
 SG_ VCSEC_BLECENTERAppGitHashByte m0 : 8|56@1+ (1,0) [0|0] "" Vector__XXX
 SG_ VCSEC_BLECENTERComponentID m1 : 8|16@1+ (1,0) [0|0] "" Vector__XXX
 SG_ VCSEC_BLECENTERCrc m2 : 8|32@1+ (1,0) [0|0] "" Vector__XXX
 SG_ VCSEC_BLELEFTAppGitHashByte m3 : 8|56@1+ (1,0) [0|0] "" Vector__XXX
 SG_ VCSEC_BLELEFTComponentID m4 : 8|16@1+ (1,0) [0|0] "" Vector__XXX
 SG_ VCSEC_BLELEFTCrc m5 : 8|32@1+ (1,0) [0|0] "" Vector__XXX
 SG_ VCSEC_BLEREARAppGitHashByte m9 : 8|56@1+ (1,0) [0|0] "" Vector__XXX
 SG_ VCSEC_BLEREARComponentID m10 : 8|16@1+ (1,0) [0|0] "" Vector__XXX
 SG_ VCSEC_BLEREARCrc m11 : 8|32@1+ (1,0) [0|0] "" Vector__XXX
 SG_ VCSEC_BLERIGHTAppGitHashByte m6 : 8|56@1+ (1,0) [0|0] "" Vector__XXX
 SG_ VCSEC_BLERIGHTComponentID m7 : 8|16@1+ (1,0) [0|0] "" Vector__XXX
 SG_ VCSEC_BLERIGHTCrc m8 : 8|32@1+ (1,0) [0|0] "" Vector__XXX
 SG_ VCSEC_BLECENTERPcbaID m1 : 24|8@1+ (1,0) [0|0] "" Vector__XXX
 SG_ VCSEC_BLELEFTPcbaID m4 : 24|8@1+ (1,0) [0|0] "" Vector__XXX
 SG_ VCSEC_BLEREARPcbaID m10 : 24|8@1+ (1,0) [0|0] "" Vector__XXX
 SG_ VCSEC_BLERIGHTPcbaID m7 : 24|8@1+ (1,0) [0|0] "" Vector__XXX
 SG_ VCSEC_BLECENTERAssemblyID m1 : 32|8@1+ (1,0) [0|0] "" Vector__XXX
 SG_ VCSEC_BLELEFTAssemblyID m4 : 32|8@1+ (1,0) [0|0] "" Vector__XXX
 SG_ VCSEC_BLEREARAssemblyID m10 : 32|8@1+ (1,0) [0|0] "" Vector__XXX
 SG_ VCSEC_BLERIGHTAssemblyID m7 : 32|8@1+ (1,0) [0|0] "" Vector__XXX
 SG_ VCSEC_BLECENTERUsageID m1 : 40|16@1+ (1,0) [0|0] "" Vector__XXX
 SG_ VCSEC_BLELEFTUsageID m4 : 40|16@1+ (1,0) [0|0] "" Vector__XXX
 SG_ VCSEC_BLEREARUsageID m10 : 40|16@1+ (1,0) [0|0] "" Vector__XXX
 SG_ VCSEC_BLERIGHTUsageID m7 : 40|16@1+ (1,0) [0|0] "" Vector__XXX

BO_ 970 VCBATT_LVBatteryDebug1Hz: 8 Vector__XXX
 SG_ VCBATT_LVBatteryDebug1HzIndex M : 0|4@1+ (1,0) [0|0] "" Vector__XXX
 SG_ VCBATT_LVBatt_impedanceTestBlockedReason m0 : 4|4@1+ (1,0) [0|0] "" Vector__XXX
 SG_ VCBATT_LVBatt_impedanceTestWakeRequest m0 : 8|1@1+ (1,0) [0|0] "" Vector__XXX

BO_ 972 APS_status: 8 Vector__XXX
 SG_ APS_appStatusMonitorState : 0|3@1+ (1,0) [0|0] "" Vector__XXX
 SG_ APS_vehBehaviorState : 4|4@1+ (1,0) [0|0] "" Vector__XXX
 SG_ APS_canMaster : 8|2@1+ (1,0) [0|0] "" Vector__XXX
 SG_ APS_appGpioState : 10|2@1+ (1,0) [0|0] "" Vector__XXX
 SG_ APS_eacInternalState : 12|3@1+ (1,0) [0|0] "" Vector__XXX
 SG_ APS_switchState : 15|1@1+ (1,0) [0|0] "" Vector__XXX
 SG_ APS_apbStatusMonitorState : 16|3@1+ (1,0) [0|0] "" Vector__XXX
 SG_ APS_apbGpioState : 20|2@1+ (1,0) [0|0] "" Vector__XXX
 SG_ APS_statusCounter : 22|4@1+ (1,0) [0|0] "" Vector__XXX
 SG_ APS_locLimitReason : 26|3@1+ (1,0) [0|0] "" Vector__XXX
 SG_ APS_appPowerStateRequest : 29|2@1+ (1,0) [0|0] "" Vector__XXX
 SG_ APS_appPowerStateReason : 31|4@1+ (1,0) [0|0] "" Vector__XXX
 SG_ APS_apbPowerStateRequest : 35|2@1+ (1,0) [0|0] "" Vector__XXX
 SG_ APS_apbPowerStateReason : 37|4@1+ (1,0) [0|0] "" Vector__XXX
 SG_ APS_heaterStateDebug : 41|3@1+ (1,0) [0|0] "" Vector__XXX
 SG_ APS_autosummonCounter : 44|3@1+ (1,0) [0|0] "" Vector__XXX
 SG_ APS_autosummonAlert : 47|1@1+ (1,0) [0|0] "" Vector__XXX
 SG_ APS_gpsAntennaState : 48|2@1+ (1,0) [0|0] "" Vector__XXX
 SG_ APS_arbState : 50|3@1+ (1,0) [0|0] "" Vector__XXX
 SG_ APS_socPowerOperatingMode : 53|2@1+ (1,0) [0|0] "" Vector__XXX
 SG_ APS_otherArbState : 55|3@1+ (1,0) [0|0] "" Vector__XXX
 SG_ APS_appActivePlannerType : 58|3@1+ (1,0) [0|0] "" Vector__XXX
 SG_ APS_apbActivePlannerType : 61|3@1+ (1,0) [0|0] "" Vector__XXX

BO_ 973 VCBATT0_alertMatrix: 8 Vector__XXX
 SG_ VCBATT0_matrixIndex M : 0|4@1+ (1,0) [0|0] "" Vector__XXX
 SG_ VCBATT0_a001_WatchdogReset m0 : 4|1@1+ (1,0) [0|0] "" Vector__XXX
 SG_ VCBATT0_a061_XCPConnected m1 : 4|1@1+ (1,0) [0|0] "" Vector__XXX
 SG_ VCBATT0_a002_PowerLossReset m0 : 5|1@1+ (1,0) [0|0] "" Vector__XXX
 SG_ VCBATT0_a062_XCPWasConnected m1 : 5|1@1+ (1,0) [0|0] "" Vector__XXX
 SG_ VCBATT0_a003_SWAssertion m0 : 6|1@1+ (1,0) [0|0] "" Vector__XXX
 SG_ VCBATT0_a063_SwitchFault m1 : 6|1@1+ (1,0) [0|0] "" Vector__XXX
 SG_ VCBATT0_a423_rtosSleepFailed m7 : 6|1@1+ (1,0) [0|0] "" Vector__XXX
 SG_ VCBATT0_a064_busSleepReqTimeout m1 : 7|1@1+ (1,0) [0|0] "" Vector__XXX
 SG_ VCBATT0_a005_CANTXError m0 : 8|1@1+ (1,0) [0|0] "" Vector__XXX
 SG_ VCBATT0_a006_CANTX_cyclicError m0 : 9|1@1+ (1,0) [0|0] "" Vector__XXX
 SG_ VCBATT0_a012_CPUReset m0 : 15|1@1+ (1,0) [0|0] "" Vector__XXX
 SG_ VCBATT0_a013_AlertManagerFault m0 : 16|1@1+ (1,0) [0|0] "" Vector__XXX
 SG_ VCBATT0_a015_NVMMError m0 : 18|1@1+ (1,0) [0|0] "" Vector__XXX
 SG_ VCBATT0_a016_NVMMRecordError m0 : 19|1@1+ (1,0) [0|0] "" Vector__XXX
 SG_ VCBATT0_a021_TaskSchedulerError m0 : 24|1@1+ (1,0) [0|0] "" Vector__XXX
 SG_ VCBATT0_a022_TaskInitError m0 : 25|1@1+ (1,0) [0|0] "" Vector__XXX
 SG_ VCBATT0_a029_CoreDump m0 : 32|1@1+ (1,0) [0|0] "" Vector__XXX
 SG_ VCBATT0_a030_ECULogUploadRequest m0 : 33|1@1+ (1,0) [0|0] "" Vector__XXX
 SG_ VCBATT0_a031_UDSActive m0 : 34|1@1+ (1,0) [0|0] "" Vector__XXX
 SG_ VCBATT0_a032_ipcWatchdogExpired m0 : 35|1@1+ (1,0) [0|0] "" Vector__XXX
 SG_ VCBATT0_a033_eccNonCorrectableError m0 : 36|1@1+ (1,0) [0|0] "" Vector__XXX
 SG_ VCBATT0_a038_ProtFaultInfo m0 : 41|1@1+ (1,0) [0|0] "" Vector__XXX
 SG_ VCBATT0_a039_ProtFaultAddress m0 : 42|1@1+ (1,0) [0|0] "" Vector__XXX
 SG_ VCBATT0_a040_Backtrace m0 : 43|1@1+ (1,0) [0|0] "" Vector__XXX
 SG_ VCBATT0_a041_HighCPULoad m0 : 44|1@1+ (1,0) [0|0] "" Vector__XXX
 SG_ VCBATT0_a042_HighStackUsage m0 : 45|1@1+ (1,0) [0|0] "" Vector__XXX
 SG_ VCBATT0_a043_Task1msError m0 : 46|1@1+ (1,0) [0|0] "" Vector__XXX
 SG_ VCBATT0_a044_Task10msError m0 : 47|1@1+ (1,0) [0|0] "" Vector__XXX
 SG_ VCBATT0_a045_Task100msError m0 : 48|1@1+ (1,0) [0|0] "" Vector__XXX
 SG_ VCBATT0_a046_Task1000msError m0 : 49|1@1+ (1,0) [0|0] "" Vector__XXX
 SG_ VCBATT0_a047_resetReason m0 : 50|1@1+ (1,0) [0|0] "" Vector__XXX
 SG_ VCBATT0_a058_inputRHighSyncDebug m0 : 61|1@1+ (1,0) [0|0] "" Vector__XXX
 SG_ VCBATT0_a059_inputResistanceHigh m0 : 62|1@1+ (1,0) [0|0] "" Vector__XXX
 SG_ VCBATT0_a060_engineeringBuild m0 : 63|1@1+ (1,0) [0|0] "" Vector__XXX

BO_ 974 VCBATT1_alertMatrix: 8 Vector__XXX
 SG_ VCBATT1_matrixIndex M : 0|4@1+ (1,0) [0|0] "" Vector__XXX
 SG_ VCBATT1_a001_WatchdogReset m0 : 4|1@1+ (1,0) [0|0] "" Vector__XXX
 SG_ VCBATT1_a061_XCPConnected m1 : 4|1@1+ (1,0) [0|0] "" Vector__XXX
 SG_ VCBATT1_a481_LVBridgeCloseDBG m8 : 4|1@1+ (1,0) [0|0] "" Vector__XXX
 SG_ VCBATT1_a541_LVBatteryChargeOCLevel1 m9 : 4|1@1+ (1,0) [0|0] "" Vector__XXX
 SG_ VCBATT1_a601_LVBatteryHeaterNotPresent m10 : 4|1@1+ (1,0) [0|0] "" Vector__XXX
 SG_ VCBATT1_a002_PowerLossReset m0 : 5|1@1+ (1,0) [0|0] "" Vector__XXX
 SG_ VCBATT1_a062_XCPWasConnected m1 : 5|1@1+ (1,0) [0|0] "" Vector__XXX
 SG_ VCBATT1_a122_ICR_MIA m2 : 5|1@1+ (1,0) [0|0] "" Vector__XXX
 SG_ VCBATT1_a182_replaceLVBattery m3 : 5|1@1+ (1,0) [0|0] "" Vector__XXX
 SG_ VCBATT1_a362_TLVBMS_AllSocCorrectionTimeout m6 : 5|1@1+ (1,0) [0|0] "" Vector__XXX
 SG_ VCBATT1_a422_rtosSleepFailed m7 : 5|1@1+ (1,0) [0|0] "" Vector__XXX
 SG_ VCBATT1_a482_lvBridgeEFuseTrip m8 : 5|1@1+ (1,0) [0|0] "" Vector__XXX
 SG_ VCBATT1_a003_SWAssertion m0 : 6|1@1+ (1,0) [0|0] "" Vector__XXX
 SG_ VCBATT1_a063_SwitchFault m1 : 6|1@1+ (1,0) [0|0] "" Vector__XXX
 SG_ VCBATT1_a183_replaceLVBattery2 m3 : 6|1@1+ (1,0) [0|0] "" Vector__XXX
 SG_ VCBATT1_a243_LVOverchargeInstc m4 : 6|1@1+ (1,0) [0|0] "" Vector__XXX
 SG_ VCBATT1_a363_TLVBMS_BleedBasedWeakShort m6 : 6|1@1+ (1,0) [0|0] "" Vector__XXX
 SG_ VCBATT1_a423_TLVBMS_BrickUnderVoltageFault m7 : 6|1@1+ (1,0) [0|0] "" Vector__XXX
 SG_ VCBATT1_a064_busSleepReqTimeout m1 : 7|1@1+ (1,0) [0|0] "" Vector__XXX
 SG_ VCBATT1_a124_BB_MIA m2 : 7|1@1+ (1,0) [0|0] "" Vector__XXX
 SG_ VCBATT1_a244_brakeValveECUEFuseTrip m4 : 7|1@1+ (1,0) [0|0] "" Vector__XXX
 SG_ VCBATT1_a424_TLVBMS_BrickUnderVoltageOcv m7 : 7|1@1+ (1,0) [0|0] "" Vector__XXX
 SG_ VCBATT1_a484_undervoltageSelfTestStuckOn m8 : 7|1@1+ (1,0) [0|0] "" Vector__XXX
 SG_ VCBATT1_a544_LVBatteryCommsBusTurnedOff m9 : 7|1@1+ (1,0) [0|0] "" Vector__XXX
 SG_ VCBATT1_a005_CANTXError m0 : 8|1@1+ (1,0) [0|0] "" Vector__XXX
 SG_ VCBATT1_a125_SCCM_MIA m2 : 8|1@1+ (1,0) [0|0] "" Vector__XXX
 SG_ VCBATT1_a245_sleepBypassFault m4 : 8|1@1+ (1,0) [0|0] "" Vector__XXX
 SG_ VCBATT1_a425_TLVBMS_BusVoltageTooHigh m7 : 8|1@1+ (1,0) [0|0] "" Vector__XXX
 SG_ VCBATT1_a485_uvSelfTestLoadUnattemptedOnDbg m8 : 8|1@1+ (1,0) [0|0] "" Vector__XXX
 SG_ VCBATT1_a545_LVBatteryTypeUnknown m9 : 8|1@1+ (1,0) [0|0] "" Vector__XXX
 SG_ VCBATT1_a006_CANTX_cyclicError m0 : 9|1@1+ (1,0) [0|0] "" Vector__XXX
 SG_ VCBATT1_a126_EPAS3P_MIA m2 : 9|1@1+ (1,0) [0|0] "" Vector__XXX
 SG_ VCBATT1_a426_TLVBMS_BusVoltageTooLow m7 : 9|1@1+ (1,0) [0|0] "" Vector__XXX
 SG_ VCBATT1_a486_undervoltageSelfTestBridgeSyncFailure m8 : 9|1@1+ (1,0) [0|0] "" Vector__XXX
 SG_ VCBATT1_a127_vcleftEFuseTrip m2 : 10|1@1+ (1,0) [0|0] "" Vector__XXX
 SG_ VCBATT1_a427_TLVBMS_CacChange m7 : 10|1@1+ (1,0) [0|0] "" Vector__XXX
 SG_ VCBATT1_a188_sleepFailed m3 : 11|1@1+ (1,0) [0|0] "" Vector__XXX
 SG_ VCBATT1_a428_TLVBMS_CacImbalance m7 : 11|1@1+ (1,0) [0|0] "" Vector__XXX
 SG_ VCBATT1_a548_HVFaultLoadShed m9 : 11|1@1+ (1,0) [0|0] "" Vector__XXX
 SG_ VCBATT1_a608_TLVBMS_BleedFetFailure m10 : 11|1@1+ (1,0) [0|0] "" Vector__XXX
 SG_ VCBATT1_a129_epas1EFuseTrip m2 : 12|1@1+ (1,0) [0|0] "" Vector__XXX
 SG_ VCBATT1_a189_IBSMIA m3 : 12|1@1+ (1,0) [0|0] "" Vector__XXX
 SG_ VCBATT1_a429_TLVBMS_CapacityTestResults m7 : 12|1@1+ (1,0) [0|0] "" Vector__XXX
 SG_ VCBATT1_a489_vnf1248SelfTestDebug m8 : 12|1@1+ (1,0) [0|0] "" Vector__XXX
 SG_ VCBATT1_a130_autopilot1EFuseTrip m2 : 13|1@1+ (1,0) [0|0] "" Vector__XXX
 SG_ VCBATT1_a370_noLVSupportSocTooLow m6 : 13|1@1+ (1,0) [0|0] "" Vector__XXX
 SG_ VCBATT1_a430_TLVBMS_ChargeCurrentLimitExceeded m7 : 13|1@1+ (1,0) [0|0] "" Vector__XXX
 SG_ VCBATT1_a490_vnf1248SelfTestFailure m8 : 13|1@1+ (1,0) [0|0] "" Vector__XXX
 SG_ VCBATT1_a670_TLVBMS_EfuseStateIrrational m11 : 13|1@1+ (1,0) [0|0] "" Vector__XXX
 SG_ VCBATT1_a131_PCSCOMMON_MIA m2 : 14|1@1+ (1,0) [0|0] "" Vector__XXX
 SG_ VCBATT1_a191_exitDriveLowLVBusVoltage m3 : 14|1@1+ (1,0) [0|0] "" Vector__XXX
 SG_ VCBATT1_a371_failureToPrechargeRisk m6 : 14|1@1+ (1,0) [0|0] "" Vector__XXX
 SG_ VCBATT1_a431_TLVBMS_ChargeOverCurrent m7 : 14|1@1+ (1,0) [0|0] "" Vector__XXX
 SG_ VCBATT1_a491_vnf1248ConfigurationMismatch m8 : 14|1@1+ (1,0) [0|0] "" Vector__XXX
 SG_ VCBATT1_a012_CPUReset m0 : 15|1@1+ (1,0) [0|0] "" Vector__XXX
 SG_ VCBATT1_a132_iBoosterEFuseTrip m2 : 15|1@1+ (1,0) [0|0] "" Vector__XXX
 SG_ VCBATT1_a252_controllerWakeup m4 : 15|1@1+ (1,0) [0|0] "" Vector__XXX
 SG_ VCBATT1_a372_TLVBMS_BmbHwOverVoltageFault m6 : 15|1@1+ (1,0) [0|0] "" Vector__XXX
 SG_ VCBATT1_a432_TLVBMS_ChargeRegulationFault m7 : 15|1@1+ (1,0) [0|0] "" Vector__XXX
 SG_ VCBATT1_a492_TLVBMS_SocImbalance m8 : 15|1@1+ (1,0) [0|0] "" Vector__XXX
 SG_ VCBATT1_a013_AlertManagerFault m0 : 16|1@1+ (1,0) [0|0] "" Vector__XXX
 SG_ VCBATT1_a133_BRAKE_MIA m2 : 16|1@1+ (1,0) [0|0] "" Vector__XXX
 SG_ VCBATT1_a253_maxChrgeSssionTmeout m4 : 16|1@1+ (1,0) [0|0] "" Vector__XXX
 SG_ VCBATT1_a433_TLVBMS_ConfigFromBmbModIdFailed m7 : 16|1@1+ (1,0) [0|0] "" Vector__XXX
 SG_ VCBATT1_a493_TLVBMS_SocImbalanceWarning m8 : 16|1@1+ (1,0) [0|0] "" Vector__XXX
 SG_ VCBATT1_a134_hvContactorsEFuseTrip m2 : 17|1@1+ (1,0) [0|0] "" Vector__XXX
 SG_ VCBATT1_a434_TLVBMS_ConfigInitFailed m7 : 17|1@1+ (1,0) [0|0] "" Vector__XXX
 SG_ VCBATT1_a494_LVBatteryTempBlockingOTA m8 : 17|1@1+ (1,0) [0|0] "" Vector__XXX
 SG_ VCBATT1_a015_NVMMError m0 : 18|1@1+ (1,0) [0|0] "" Vector__XXX
 SG_ VCBATT1_a435_TLVBMS_DchgCurrentLimitExceeded m7 : 18|1@1+ (1,0) [0|0] "" Vector__XXX
 SG_ VCBATT1_a495_LVBatteryRecoveryBlocked m8 : 18|1@1+ (1,0) [0|0] "" Vector__XXX
 SG_ VCBATT1_a555_LVBatteryCellRebalancing m9 : 18|1@1+ (1,0) [0|0] "" Vector__XXX
 SG_ VCBATT1_a615_TLVBMS_BatteryHeaterFault m10 : 18|1@1+ (1,0) [0|0] "" Vector__XXX
 SG_ VCBATT1_a016_NVMMRecordError m0 : 19|1@1+ (1,0) [0|0] "" Vector__XXX
 SG_ VCBATT1_a196_discnctdLVBattery m3 : 19|1@1+ (1,0) [0|0] "" Vector__XXX
 SG_ VCBATT1_a376_controllerWakeupDebug m6 : 19|1@1+ (1,0) [0|0] "" Vector__XXX
 SG_ VCBATT1_a436_TLVBMS_DischargeOverCurrent m7 : 19|1@1+ (1,0) [0|0] "" Vector__XXX
 SG_ VCBATT1_a496_LVBatteryExitDriveWarning m8 : 19|1@1+ (1,0) [0|0] "" Vector__XXX
 SG_ VCBATT1_a556_falseTriggerOfDiscnctdBatteryTest m9 : 19|1@1+ (1,0) [0|0] "" Vector__XXX
 SG_ VCBATT1_a017_NVMMStatusDbg m0 : 20|1@1+ (1,0) [0|0] "" Vector__XXX
 SG_ VCBATT1_a077_VCBATT0_MIA m1 : 20|1@1+ (1,0) [0|0] "" Vector__XXX
 SG_ VCBATT1_a437_TLVBMS_NvmRegistrationError m7 : 20|1@1+ (1,0) [0|0] "" Vector__XXX
 SG_ VCBATT1_a497_LVBatteryWarnDisconnect m8 : 20|1@1+ (1,0) [0|0] "" Vector__XXX
 SG_ VCBATT1_a617_APP_MIA m10 : 20|1@1+ (1,0) [0|0] "" Vector__XXX
 SG_ VCBATT1_a018_HardFault m0 : 21|1@1+ (1,0) [0|0] "" Vector__XXX
 SG_ VCBATT1_a078_VCBATT1_MIA m1 : 21|1@1+ (1,0) [0|0] "" Vector__XXX
 SG_ VCBATT1_a258_resistanceEstimationRun m4 : 21|1@1+ (1,0) [0|0] "" Vector__XXX
 SG_ VCBATT1_a438_TLVBMS_PackOverTemperatureFault m7 : 21|1@1+ (1,0) [0|0] "" Vector__XXX
 SG_ VCBATT1_a498_TLVBMS_ImpedanceTestResults m8 : 21|1@1+ (1,0) [0|0] "" Vector__XXX
 SG_ VCBATT1_a019_BusFault m0 : 22|1@1+ (1,0) [0|0] "" Vector__XXX
 SG_ VCBATT1_a079_VCBATT2_MIA m1 : 22|1@1+ (1,0) [0|0] "" Vector__XXX
 SG_ VCBATT1_a259_LVVoltageDropOnHighLoadCurrent m4 : 22|1@1+ (1,0) [0|0] "" Vector__XXX
 SG_ VCBATT1_a379_shortedCellTestRunDebug m6 : 22|1@1+ (1,0) [0|0] "" Vector__XXX
 SG_ VCBATT1_a439_TLVBMS_PackOverTemperatureWarning m7 : 22|1@1+ (1,0) [0|0] "" Vector__XXX
 SG_ VCBATT1_a559_LVBatteryLowSOC m9 : 22|1@1+ (1,0) [0|0] "" Vector__XXX
 SG_ VCBATT1_a080_VCFRONT0_MIA m1 : 23|1@1+ (1,0) [0|0] "" Vector__XXX
 SG_ VCBATT1_a260_deadLVBattery m4 : 23|1@1+ (1,0) [0|0] "" Vector__XXX
 SG_ VCBATT1_a440_TLVBMS_PackSNInvalidForNvm m7 : 23|1@1+ (1,0) [0|0] "" Vector__XXX
 SG_ VCBATT1_a021_TaskSchedulerError m0 : 24|1@1+ (1,0) [0|0] "" Vector__XXX
 SG_ VCBATT1_a081_VCFRONT1_MIA m1 : 24|1@1+ (1,0) [0|0] "" Vector__XXX
 SG_ VCBATT1_a441_TLVBMS_ResetNeededForNvmPackSwap m7 : 24|1@1+ (1,0) [0|0] "" Vector__XXX
 SG_ VCBATT1_a561_LVBMSEFuseOvertemperature m9 : 24|1@1+ (1,0) [0|0] "" Vector__XXX
 SG_ VCBATT1_a022_TaskInitError m0 : 25|1@1+ (1,0) [0|0] "" Vector__XXX
 SG_ VCBATT1_a082_VCFRONT2_MIA m1 : 25|1@1+ (1,0) [0|0] "" Vector__XXX
 SG_ VCBATT1_a442_TLVBMS_SocChange m7 : 25|1@1+ (1,0) [0|0] "" Vector__XXX
 SG_ VCBATT1_a502_TLVBMS_WeakShortImpedance m8 : 25|1@1+ (1,0) [0|0] "" Vector__XXX
 SG_ VCBATT1_a562_LVBMSModuleOvertemperature m9 : 25|1@1+ (1,0) [0|0] "" Vector__XXX
 SG_ VCBATT1_a443_TLVBMS_BmbDieOverTemperature m7 : 26|1@1+ (1,0) [0|0] "" Vector__XXX
 SG_ VCBATT1_a503_TLVBMS_BrickExtendedOvFault m8 : 26|1@1+ (1,0) [0|0] "" Vector__XXX
 SG_ VCBATT1_a144_EPAS3S_MIA m2 : 27|1@1+ (1,0) [0|0] "" Vector__XXX
 SG_ VCBATT1_a204_undervoltageLoadshedTriggered m3 : 27|1@1+ (1,0) [0|0] "" Vector__XXX
 SG_ VCBATT1_a205_overvoltageProtectionTriggered m3 : 28|1@1+ (1,0) [0|0] "" Vector__XXX
 SG_ VCBATT1_a086_VCBATT_MIA m1 : 29|1@1+ (1,0) [0|0] "" Vector__XXX
 SG_ VCBATT1_a446_LVBatteryUnrecoverableByAnyDevice m7 : 29|1@1+ (1,0) [0|0] "" Vector__XXX
 SG_ VCBATT1_a387_shortedCellInstc m6 : 30|1@1+ (1,0) [0|0] "" Vector__XXX
 SG_ VCBATT1_a028_UsageFault m0 : 31|1@1+ (1,0) [0|0] "" Vector__XXX
 SG_ VCBATT1_a388_shortedCell m6 : 31|1@1+ (1,0) [0|0] "" Vector__XXX
 SG_ VCBATT1_a508_TLVBMS_ImpedanceGrowth m8 : 31|1@1+ (1,0) [0|0] "" Vector__XXX
 SG_ VCBATT1_a628_TLVBMS_BmbThermistorFault m10 : 31|1@1+ (1,0) [0|0] "" Vector__XXX
 SG_ VCBATT1_a029_CoreDump m0 : 32|1@1+ (1,0) [0|0] "" Vector__XXX
 SG_ VCBATT1_a509_eFuseASICManagerStateMismatch m8 : 32|1@1+ (1,0) [0|0] "" Vector__XXX
 SG_ VCBATT1_a629_TLVBMS_PackTemperatureIrrational m10 : 32|1@1+ (1,0) [0|0] "" Vector__XXX
 SG_ VCBATT1_a030_ECULogUploadRequest m0 : 33|1@1+ (1,0) [0|0] "" Vector__XXX
 SG_ VCBATT1_a090_APS_MIA m1 : 33|1@1+ (1,0) [0|0] "" Vector__XXX
 SG_ VCBATT1_a510_LVBatteryRecoveryTimeout m8 : 33|1@1+ (1,0) [0|0] "" Vector__XXX
 SG_ VCBATT1_a031_UDSActive m0 : 34|1@1+ (1,0) [0|0] "" Vector__XXX
 SG_ VCBATT1_a091_CMPD_MIA m1 : 34|1@1+ (1,0) [0|0] "" Vector__XXX
 SG_ VCBATT1_a212_IBSOverTemp m3 : 35|1@1+ (1,0) [0|0] "" Vector__XXX
 SG_ VCBATT1_a392_TLVBMS_BmbHwUnderVoltageFault m6 : 35|1@1+ (1,0) [0|0] "" Vector__XXX
 SG_ VCBATT1_a512_LVBMSFault_MOS_Open_hardwareOC m8 : 35|1@1+ (1,0) [0|0] "" Vector__XXX
 SG_ VCBATT1_a213_LVOvercharge m3 : 36|1@1+ (1,0) [0|0] "" Vector__XXX
 SG_ VCBATT1_a513_LVBMSFault_MOS_Open_chgOC m8 : 36|1@1+ (1,0) [0|0] "" Vector__XXX
 SG_ VCBATT1_a573_radarEFuseTrip m9 : 36|1@1+ (1,0) [0|0] "" Vector__XXX
 SG_ VCBATT1_a514_LVBMSFault_MOS_Open_cellUV m8 : 37|1@1+ (1,0) [0|0] "" Vector__XXX
 SG_ VCBATT1_a215_selfTestOrchestratorDebug m3 : 38|1@1+ (1,0) [0|0] "" Vector__XXX
 SG_ VCBATT1_a275_TLVBMS_BmbCommunication m4 : 38|1@1+ (1,0) [0|0] "" Vector__XXX
 SG_ VCBATT1_a515_LVBMSFault_MOS_Open_cellOV m8 : 38|1@1+ (1,0) [0|0] "" Vector__XXX
 SG_ VCBATT1_a575_vbatFusedLoadShedEFuseTrip m9 : 38|1@1+ (1,0) [0|0] "" Vector__XXX
 SG_ VCBATT1_a036_UnknownIrq m0 : 39|1@1+ (1,0) [0|0] "" Vector__XXX
 SG_ VCBATT1_a096_OCS1P_MIA m1 : 39|1@1+ (1,0) [0|0] "" Vector__XXX
 SG_ VCBATT1_a216_powerCutoffImminent m3 : 39|1@1+ (1,0) [0|0] "" Vector__XXX
 SG_ VCBATT1_a276_TLVBMS_BmbDataIntegrityLoss m4 : 39|1@1+ (1,0) [0|0] "" Vector__XXX
 SG_ VCBATT1_a576_mcuLogicEFuseTrip m9 : 39|1@1+ (1,0) [0|0] "" Vector__XXX
 SG_ VCBATT1_a037_MemManageFault m0 : 40|1@1+ (1,0) [0|0] "" Vector__XXX
 SG_ VCBATT1_a217_LVProtectionSelfTestInvalid m3 : 40|1@1+ (1,0) [0|0] "" Vector__XXX
 SG_ VCBATT1_a277_TLVBMS_BmbStatusRegError m4 : 40|1@1+ (1,0) [0|0] "" Vector__XXX
 SG_ VCBATT1_a038_ProtFaultInfo m0 : 41|1@1+ (1,0) [0|0] "" Vector__XXX
 SG_ VCBATT1_a098_DIR_MIA m1 : 41|1@1+ (1,0) [0|0] "" Vector__XXX
 SG_ VCBATT1_a278_TLVBMS_BmbHwOverCurrentFault m4 : 41|1@1+ (1,0) [0|0] "" Vector__XXX
 SG_ VCBATT1_a518_LVBMSFault_MOS_Open_packOV m8 : 41|1@1+ (1,0) [0|0] "" Vector__XXX
 SG_ VCBATT1_a039_ProtFaultAddress m0 : 42|1@1+ (1,0) [0|0] "" Vector__XXX
 SG_ VCBATT1_a219_LVVoltFloorRchd m3 : 42|1@1+ (1,0) [0|0] "" Vector__XXX
 SG_ VCBATT1_a040_Backtrace m0 : 43|1@1+ (1,0) [0|0] "" Vector__XXX
 SG_ VCBATT1_a100_CANbus_MIA m1 : 43|1@1+ (1,0) [0|0] "" Vector__XXX
 SG_ VCBATT1_a220_LVUnhealthy m3 : 43|1@1+ (1,0) [0|0] "" Vector__XXX
 SG_ VCBATT1_a400_TLVBMS_BmbVrefBad m6 : 43|1@1+ (1,0) [0|0] "" Vector__XXX
 SG_ VCBATT1_a580_rightHeadlightEFuseTrip m9 : 43|1@1+ (1,0) [0|0] "" Vector__XXX
 SG_ VCBATT1_a041_HighCPULoad m0 : 44|1@1+ (1,0) [0|0] "" Vector__XXX
 SG_ VCBATT1_a221_reverseBatteryFault m3 : 44|1@1+ (1,0) [0|0] "" Vector__XXX
 SG_ VCBATT1_a401_deadLVMinimalAhDischarged m6 : 44|1@1+ (1,0) [0|0] "" Vector__XXX
 SG_ VCBATT1_a461_TLVBMS_SocHighAhError m7 : 44|1@1+ (1,0) [0|0] "" Vector__XXX
 SG_ VCBATT1_a521_vcleftEFuseLoadShed m8 : 44|1@1+ (1,0) [0|0] "" Vector__XXX
 SG_ VCBATT1_a581_harnessResistanceInfo m9 : 44|1@1+ (1,0) [0|0] "" Vector__XXX
 SG_ VCBATT1_a042_HighStackUsage m0 : 45|1@1+ (1,0) [0|0] "" Vector__XXX
 SG_ VCBATT1_a402_LVBatteryCannotSupportVehicle m6 : 45|1@1+ (1,0) [0|0] "" Vector__XXX
 SG_ VCBATT1_a462_LVBMSFault m7 : 45|1@1+ (1,0) [0|0] "" Vector__XXX
 SG_ VCBATT1_a582_goodForPCSPowerCycle m9 : 45|1@1+ (1,0) [0|0] "" Vector__XXX
 SG_ VCBATT1_a043_Task1msError m0 : 46|1@1+ (1,0) [0|0] "" Vector__XXX
 SG_ VCBATT1_a103_CP_MIA m1 : 46|1@1+ (1,0) [0|0] "" Vector__XXX
 SG_ VCBATT1_a223_bridgeOvervoltageSelfTestFailure m3 : 46|1@1+ (1,0) [0|0] "" Vector__XXX
 SG_ VCBATT1_a403_chargeExitHardCurrentLimit m6 : 46|1@1+ (1,0) [0|0] "" Vector__XXX
 SG_ VCBATT1_a044_Task10msError m0 : 47|1@1+ (1,0) [0|0] "" Vector__XXX
 SG_ VCBATT1_a104_DAS_MIA m1 : 47|1@1+ (1,0) [0|0] "" Vector__XXX
 SG_ VCBATT1_a164_eFuseLckoutMissing m2 : 47|1@1+ (1,0) [0|0] "" Vector__XXX
 SG_ VCBATT1_a224_overcurrentLoadshedTriggered m3 : 47|1@1+ (1,0) [0|0] "" Vector__XXX
 SG_ VCBATT1_a404_resistanceEstimationHardFailure m6 : 47|1@1+ (1,0) [0|0] "" Vector__XXX
 SG_ VCBATT1_a045_Task100msError m0 : 48|1@1+ (1,0) [0|0] "" Vector__XXX
 SG_ VCBATT1_a105_TAS_MIA m1 : 48|1@1+ (1,0) [0|0] "" Vector__XXX
 SG_ VCBATT1_a165_unxpctdEFuseLckout m2 : 48|1@1+ (1,0) [0|0] "" Vector__XXX
 SG_ VCBATT1_a225_overcurrentSelfTestFailure m3 : 48|1@1+ (1,0) [0|0] "" Vector__XXX
 SG_ VCBATT1_a405_dcrData1 m6 : 48|1@1+ (1,0) [0|0] "" Vector__XXX
 SG_ VCBATT1_a525_LVBatterySWMisconfiguration m8 : 48|1@1+ (1,0) [0|0] "" Vector__XXX
 SG_ VCBATT1_a046_Task1000msError m0 : 49|1@1+ (1,0) [0|0] "" Vector__XXX
 SG_ VCBATT1_a106_PCS_MIA m1 : 49|1@1+ (1,0) [0|0] "" Vector__XXX
 SG_ VCBATT1_a226_overcurrentSelfTestChannelFastDBG m3 : 49|1@1+ (1,0) [0|0] "" Vector__XXX
 SG_ VCBATT1_a406_dcrData2 m6 : 49|1@1+ (1,0) [0|0] "" Vector__XXX
 SG_ VCBATT1_a107_BMS_MIA m1 : 50|1@1+ (1,0) [0|0] "" Vector__XXX
 SG_ VCBATT1_a227_overcurrentSelfTestChannelMediumDBG m3 : 50|1@1+ (1,0) [0|0] "" Vector__XXX
 SG_ VCBATT1_a407_dcrMilliOhmsAboveThreshold m6 : 50|1@1+ (1,0) [0|0] "" Vector__XXX
 SG_ VCBATT1_a527_LVBatteryCellImbalance m8 : 50|1@1+ (1,0) [0|0] "" Vector__XXX
 SG_ VCBATT1_a587_externalLVPowerSupply m9 : 50|1@1+ (1,0) [0|0] "" Vector__XXX
 SG_ VCBATT1_a108_DIF_MIA m1 : 51|1@1+ (1,0) [0|0] "" Vector__XXX
 SG_ VCBATT1_a228_overcurrentSelfTestChannelSlowDBG m3 : 51|1@1+ (1,0) [0|0] "" Vector__XXX
 SG_ VCBATT1_a408_standbyChargeProfileHardExit m6 : 51|1@1+ (1,0) [0|0] "" Vector__XXX
 SG_ VCBATT1_a528_LVBatteryCommsDiscnctd m8 : 51|1@1+ (1,0) [0|0] "" Vector__XXX
 SG_ VCBATT1_a588_vcleftPwrRationalityCurve m9 : 51|1@1+ (1,0) [0|0] "" Vector__XXX
 SG_ VCBATT1_a229_LVHealthCompromised m3 : 52|1@1+ (1,0) [0|0] "" Vector__XXX
 SG_ VCBATT1_a529_discnctdBatteryStateUnknown m8 : 52|1@1+ (1,0) [0|0] "" Vector__XXX
 SG_ VCBATT1_a589_vcleftFastBlowDetection m9 : 52|1@1+ (1,0) [0|0] "" Vector__XXX
 SG_ VCBATT1_a110_GTW_MIA m1 : 53|1@1+ (1,0) [0|0] "" Vector__XXX
 SG_ VCBATT1_a230_ingoingOvercurrentSelfTestFailure m3 : 53|1@1+ (1,0) [0|0] "" Vector__XXX
 SG_ VCBATT1_a410_LVBatteryDataCollection1 m6 : 53|1@1+ (1,0) [0|0] "" Vector__XXX
 SG_ VCBATT1_a111_EPBR_MIA m1 : 54|1@1+ (1,0) [0|0] "" Vector__XXX
 SG_ VCBATT1_a411_LVBatteryDataCollection2 m6 : 54|1@1+ (1,0) [0|0] "" Vector__XXX
 SG_ VCBATT1_a112_EPBL_MIA m1 : 55|1@1+ (1,0) [0|0] "" Vector__XXX
 SG_ VCBATT1_a412_dcrData3 m6 : 55|1@1+ (1,0) [0|0] "" Vector__XXX
 SG_ VCBATT1_a592_vcleftCurvePowerCutoff m9 : 55|1@1+ (1,0) [0|0] "" Vector__XXX
 SG_ VCBATT1_a113_UI_MIA m1 : 56|1@1+ (1,0) [0|0] "" Vector__XXX
 SG_ VCBATT1_a413_TLVBMS_BmbVrefWarning m6 : 56|1@1+ (1,0) [0|0] "" Vector__XXX
 SG_ VCBATT1_a533_TLVBMS_MosfetOverTemperatureFault m8 : 56|1@1+ (1,0) [0|0] "" Vector__XXX
 SG_ VCBATT1_a593_vcleftFastBlowPowerCutoff m9 : 56|1@1+ (1,0) [0|0] "" Vector__XXX
 SG_ VCBATT1_a114_ESP_MIA m1 : 57|1@1+ (1,0) [0|0] "" Vector__XXX
 SG_ VCBATT1_a414_undervoltageSelfTestFailure m6 : 57|1@1+ (1,0) [0|0] "" Vector__XXX
 SG_ VCBATT1_a115_VCSEC_MIA m1 : 58|1@1+ (1,0) [0|0] "" Vector__XXX
 SG_ VCBATT1_a235_dualPowerLoadsSelfTestFailure m3 : 58|1@1+ (1,0) [0|0] "" Vector__XXX
 SG_ VCBATT1_a415_undervoltageSelfTestStuckOff m6 : 58|1@1+ (1,0) [0|0] "" Vector__XXX
 SG_ VCBATT1_a475_vnf1248Fault m7 : 58|1@1+ (1,0) [0|0] "" Vector__XXX
 SG_ VCBATT1_a595_voltageSensorMismatch m9 : 58|1@1+ (1,0) [0|0] "" Vector__XXX
 SG_ VCBATT1_a116_VCRIGHT_MIA m1 : 59|1@1+ (1,0) [0|0] "" Vector__XXX
 SG_ VCBATT1_a236_hvcDualPowerSelfTestDebug m3 : 59|1@1+ (1,0) [0|0] "" Vector__XXX
 SG_ VCBATT1_a416_TLVBMS_BrickOverDischarged m6 : 59|1@1+ (1,0) [0|0] "" Vector__XXX
 SG_ VCBATT1_a476_LVBMSMIA m7 : 59|1@1+ (1,0) [0|0] "" Vector__XXX
 SG_ VCBATT1_a117_VCLEFT_MIA m1 : 60|1@1+ (1,0) [0|0] "" Vector__XXX
 SG_ VCBATT1_a297_TLVBMS_BmbHwOverTemperatureFault m4 : 60|1@1+ (1,0) [0|0] "" Vector__XXX
 SG_ VCBATT1_a417_TLVBMS_BrickOverVoltageFault m6 : 60|1@1+ (1,0) [0|0] "" Vector__XXX
 SG_ VCBATT1_a477_LVBatteryUnrecoverableByVehicle m7 : 60|1@1+ (1,0) [0|0] "" Vector__XXX
 SG_ VCBATT1_a058_inputRHighSyncDebug m0 : 61|1@1+ (1,0) [0|0] "" Vector__XXX
 SG_ VCBATT1_a118_VCFRONT_MIA m1 : 61|1@1+ (1,0) [0|0] "" Vector__XXX
 SG_ VCBATT1_a418_TLVBMS_BrickOverVoltageWarning m6 : 61|1@1+ (1,0) [0|0] "" Vector__XXX
 SG_ VCBATT1_a478_LVBMS_MOSFET_Open m7 : 61|1@1+ (1,0) [0|0] "" Vector__XXX
 SG_ VCBATT1_a059_inputResistanceHigh m0 : 62|1@1+ (1,0) [0|0] "" Vector__XXX
 SG_ VCBATT1_a119_SCCM_MIA m1 : 62|1@1+ (1,0) [0|0] "" Vector__XXX
 SG_ VCBATT1_a359_postPORExcessiveAh m5 : 62|1@1+ (1,0) [0|0] "" Vector__XXX
 SG_ VCBATT1_a419_TLVBMS_BrickSocLow m6 : 62|1@1+ (1,0) [0|0] "" Vector__XXX
 SG_ VCBATT1_a479_LVBMS_ECPA_NotClosed m7 : 62|1@1+ (1,0) [0|0] "" Vector__XXX
 SG_ VCBATT1_a599_LVBatteryTypeUnsupported m9 : 62|1@1+ (1,0) [0|0] "" Vector__XXX
 SG_ VCBATT1_a060_engineeringBuild m0 : 63|1@1+ (1,0) [0|0] "" Vector__XXX
 SG_ VCBATT1_a120_DI_DRIVE_MIA m1 : 63|1@1+ (1,0) [0|0] "" Vector__XXX
 SG_ VCBATT1_a180_DCDCNotSupportingLVBus m2 : 63|1@1+ (1,0) [0|0] "" Vector__XXX
 SG_ VCBATT1_a420_LVBridgeRetryInDrive m6 : 63|1@1+ (1,0) [0|0] "" Vector__XXX
 SG_ VCBATT1_a600_currentSensorMismatch m9 : 63|1@1+ (1,0) [0|0] "" Vector__XXX

BO_ 975 VCBATT2_alertMatrix: 8 Vector__XXX
 SG_ VCBATT2_matrixIndex M : 0|4@1+ (1,0) [0|0] "" Vector__XXX
 SG_ VCBATT2_a001_WatchdogReset m0 : 4|1@1+ (1,0) [0|0] "" Vector__XXX
 SG_ VCBATT2_a061_XCPConnected m1 : 4|1@1+ (1,0) [0|0] "" Vector__XXX
 SG_ VCBATT2_a181_homelinkMIA m3 : 4|1@1+ (1,0) [0|0] "" Vector__XXX
 SG_ VCBATT2_a241_radFanMIA m4 : 4|1@1+ (1,0) [0|0] "" Vector__XXX
 SG_ VCBATT2_a361_washerFluidLowMomentary m6 : 4|1@1+ (1,0) [0|0] "" Vector__XXX
 SG_ VCBATT2_a002_PowerLossReset m0 : 5|1@1+ (1,0) [0|0] "" Vector__XXX
 SG_ VCBATT2_a062_XCPWasConnected m1 : 5|1@1+ (1,0) [0|0] "" Vector__XXX
 SG_ VCBATT2_a122_ICR_MIA m2 : 5|1@1+ (1,0) [0|0] "" Vector__XXX
 SG_ VCBATT2_a662_mculessRightHeadlampCurrentAlertDbg m11 : 5|1@1+ (1,0) [0|0] "" Vector__XXX
 SG_ VCBATT2_a003_SWAssertion m0 : 6|1@1+ (1,0) [0|0] "" Vector__XXX
 SG_ VCBATT2_a063_SwitchFault m1 : 6|1@1+ (1,0) [0|0] "" Vector__XXX
 SG_ VCBATT2_a123_VC_SECONDARY_LIGHTING_LEADER_MIA m2 : 6|1@1+ (1,0) [0|0] "" Vector__XXX
 SG_ VCBATT2_a303_frunkAccessPostActive m5 : 6|1@1+ (1,0) [0|0] "" Vector__XXX
 SG_ VCBATT2_a423_rtosSleepFailed m7 : 6|1@1+ (1,0) [0|0] "" Vector__XXX
 SG_ VCBATT2_a064_busSleepReqTimeout m1 : 7|1@1+ (1,0) [0|0] "" Vector__XXX
 SG_ VCBATT2_a124_BB_MIA m2 : 7|1@1+ (1,0) [0|0] "" Vector__XXX
 SG_ VCBATT2_a304_frunkReleaseFailed m5 : 7|1@1+ (1,0) [0|0] "" Vector__XXX
 SG_ VCBATT2_a364_heaterTypeEstimationChanged m6 : 7|1@1+ (1,0) [0|0] "" Vector__XXX
 SG_ VCBATT2_a664_rightHeadlampUartWaterMarkWarning m11 : 7|1@1+ (1,0) [0|0] "" Vector__XXX
 SG_ VCBATT2_a005_CANTXError m0 : 8|1@1+ (1,0) [0|0] "" Vector__XXX
 SG_ VCBATT2_a125_SCCM_MIA m2 : 8|1@1+ (1,0) [0|0] "" Vector__XXX
 SG_ VCBATT2_a185_washerFluidLow m3 : 8|1@1+ (1,0) [0|0] "" Vector__XXX
 SG_ VCBATT2_a305_frunkPriOverCurrent m5 : 8|1@1+ (1,0) [0|0] "" Vector__XXX
 SG_ VCBATT2_a485_mcuGamingEFuseFault m8 : 8|1@1+ (1,0) [0|0] "" Vector__XXX
 SG_ VCBATT2_a006_CANTX_cyclicError m0 : 9|1@1+ (1,0) [0|0] "" Vector__XXX
 SG_ VCBATT2_a126_EPAS3P_MIA m2 : 9|1@1+ (1,0) [0|0] "" Vector__XXX
 SG_ VCBATT2_a186_washerFluidLowFasciaAndRepeater m3 : 9|1@1+ (1,0) [0|0] "" Vector__XXX
 SG_ VCBATT2_a306_frunkPriUnderCurrent m5 : 9|1@1+ (1,0) [0|0] "" Vector__XXX
 SG_ VCBATT2_a486_sleepPowerDebug m8 : 9|1@1+ (1,0) [0|0] "" Vector__XXX
 SG_ VCBATT2_a666_rightHeadlampRetryInfo m11 : 9|1@1+ (1,0) [0|0] "" Vector__XXX
 SG_ VCBATT2_a187_washerFluidLowPassengerWiper m3 : 10|1@1+ (1,0) [0|0] "" Vector__XXX
 SG_ VCBATT2_a547_postCrashLoadShed m9 : 10|1@1+ (1,0) [0|0] "" Vector__XXX
 SG_ VCBATT2_a188_sleepFailed m3 : 11|1@1+ (1,0) [0|0] "" Vector__XXX
 SG_ VCBATT2_a548_HVFaultLoadShed m9 : 11|1@1+ (1,0) [0|0] "" Vector__XXX
 SG_ VCBATT2_a668_rightHeadlampRegionOrSideMismatch m11 : 11|1@1+ (1,0) [0|0] "" Vector__XXX
 SG_ VCBATT2_a309_frunkEmergencyReleasePressed m5 : 12|1@1+ (1,0) [0|0] "" Vector__XXX
 SG_ VCBATT2_a610_frunkOpenFailureMetricSet m10 : 13|1@1+ (1,0) [0|0] "" Vector__XXX
 SG_ VCBATT2_a131_PCSCOMMON_MIA m2 : 14|1@1+ (1,0) [0|0] "" Vector__XXX
 SG_ VCBATT2_a012_CPUReset m0 : 15|1@1+ (1,0) [0|0] "" Vector__XXX
 SG_ VCBATT2_a192_vehicleLoadShed m3 : 15|1@1+ (1,0) [0|0] "" Vector__XXX
 SG_ VCBATT2_a013_AlertManagerFault m0 : 16|1@1+ (1,0) [0|0] "" Vector__XXX
 SG_ VCBATT2_a133_BRAKE_MIA m2 : 16|1@1+ (1,0) [0|0] "" Vector__XXX
 SG_ VCBATT2_a015_NVMMError m0 : 18|1@1+ (1,0) [0|0] "" Vector__XXX
 SG_ VCBATT2_a016_NVMMRecordError m0 : 19|1@1+ (1,0) [0|0] "" Vector__XXX
 SG_ VCBATT2_a017_NVMMStatusDbg m0 : 20|1@1+ (1,0) [0|0] "" Vector__XXX
 SG_ VCBATT2_a077_VCBATT0_MIA m1 : 20|1@1+ (1,0) [0|0] "" Vector__XXX
 SG_ VCBATT2_a617_APP_MIA m10 : 20|1@1+ (1,0) [0|0] "" Vector__XXX
 SG_ VCBATT2_a018_HardFault m0 : 21|1@1+ (1,0) [0|0] "" Vector__XXX
 SG_ VCBATT2_a078_VCBATT1_MIA m1 : 21|1@1+ (1,0) [0|0] "" Vector__XXX
 SG_ VCBATT2_a558_rightHeadlampAimingDebug m9 : 21|1@1+ (1,0) [0|0] "" Vector__XXX
 SG_ VCBATT2_a019_BusFault m0 : 22|1@1+ (1,0) [0|0] "" Vector__XXX
 SG_ VCBATT2_a079_VCBATT2_MIA m1 : 22|1@1+ (1,0) [0|0] "" Vector__XXX
 SG_ VCBATT2_a619_frunkSwitchReleaseTimeDBG m10 : 22|1@1+ (1,0) [0|0] "" Vector__XXX
 SG_ VCBATT2_a080_VCFRONT0_MIA m1 : 23|1@1+ (1,0) [0|0] "" Vector__XXX
 SG_ VCBATT2_a021_TaskSchedulerError m0 : 24|1@1+ (1,0) [0|0] "" Vector__XXX
 SG_ VCBATT2_a081_VCFRONT1_MIA m1 : 24|1@1+ (1,0) [0|0] "" Vector__XXX
 SG_ VCBATT2_a022_TaskInitError m0 : 25|1@1+ (1,0) [0|0] "" Vector__XXX
 SG_ VCBATT2_a082_VCFRONT2_MIA m1 : 25|1@1+ (1,0) [0|0] "" Vector__XXX
 SG_ VCBATT2_a143_powerLossDuringSleep m2 : 26|1@1+ (1,0) [0|0] "" Vector__XXX
 SG_ VCBATT2_a144_EPAS3S_MIA m2 : 27|1@1+ (1,0) [0|0] "" Vector__XXX
 SG_ VCBATT2_a086_VCBATT_MIA m1 : 29|1@1+ (1,0) [0|0] "" Vector__XXX
 SG_ VCBATT2_a567_rightFrontTurnLightFault m9 : 30|1@1+ (1,0) [0|0] "" Vector__XXX
 SG_ VCBATT2_a028_UsageFault m0 : 31|1@1+ (1,0) [0|0] "" Vector__XXX
 SG_ VCBATT2_a208_brakeFluidLow m3 : 31|1@1+ (1,0) [0|0] "" Vector__XXX
 SG_ VCBATT2_a029_CoreDump m0 : 32|1@1+ (1,0) [0|0] "" Vector__XXX
 SG_ VCBATT2_a209_brakeFluidSNA m3 : 32|1@1+ (1,0) [0|0] "" Vector__XXX
 SG_ VCBATT2_a389_frunkInhibitingReleaseAtSpeed m6 : 32|1@1+ (1,0) [0|0] "" Vector__XXX
 SG_ VCBATT2_a569_rightDaytimeRunningLightFault m9 : 32|1@1+ (1,0) [0|0] "" Vector__XXX
 SG_ VCBATT2_a030_ECULogUploadRequest m0 : 33|1@1+ (1,0) [0|0] "" Vector__XXX
 SG_ VCBATT2_a090_APS_MIA m1 : 33|1@1+ (1,0) [0|0] "" Vector__XXX
 SG_ VCBATT2_a031_UDSActive m0 : 34|1@1+ (1,0) [0|0] "" Vector__XXX
 SG_ VCBATT2_a091_CMPD_MIA m1 : 34|1@1+ (1,0) [0|0] "" Vector__XXX
 SG_ VCBATT2_a211_I2CFault m3 : 34|1@1+ (1,0) [0|0] "" Vector__XXX
 SG_ VCBATT2_a391_frunkLatchSwitchFault m6 : 34|1@1+ (1,0) [0|0] "" Vector__XXX
 SG_ VCBATT2_a631_rightHeadlampFactoryFault m10 : 34|1@1+ (1,0) [0|0] "" Vector__XXX
 SG_ VCBATT2_a634_indeterminateSwitchTransitionDetectedDbg m10 : 37|1@1+ (1,0) [0|0] "" Vector__XXX
 SG_ VCBATT2_a575_frontOilPumpEFuseTrip m9 : 38|1@1+ (1,0) [0|0] "" Vector__XXX
 SG_ VCBATT2_a036_UnknownIrq m0 : 39|1@1+ (1,0) [0|0] "" Vector__XXX
 SG_ VCBATT2_a096_OCS1P_MIA m1 : 39|1@1+ (1,0) [0|0] "" Vector__XXX
 SG_ VCBATT2_a156_louverBlockage m2 : 39|1@1+ (1,0) [0|0] "" Vector__XXX
 SG_ VCBATT2_a516_hibernationActive m8 : 39|1@1+ (1,0) [0|0] "" Vector__XXX
 SG_ VCBATT2_a037_MemManageFault m0 : 40|1@1+ (1,0) [0|0] "" Vector__XXX
 SG_ VCBATT2_a157_louverBreakage m2 : 40|1@1+ (1,0) [0|0] "" Vector__XXX
 SG_ VCBATT2_a517_hibernationRecovery m8 : 40|1@1+ (1,0) [0|0] "" Vector__XXX
 SG_ VCBATT2_a038_ProtFaultInfo m0 : 41|1@1+ (1,0) [0|0] "" Vector__XXX
 SG_ VCBATT2_a098_DIR_MIA m1 : 41|1@1+ (1,0) [0|0] "" Vector__XXX
 SG_ VCBATT2_a158_louverDisconnected m2 : 41|1@1+ (1,0) [0|0] "" Vector__XXX
 SG_ VCBATT2_a578_vbattFusedLowCurrentFeedEFuseTrip m9 : 41|1@1+ (1,0) [0|0] "" Vector__XXX
 SG_ VCBATT2_a698_rightHeadlampNotAimed m11 : 41|1@1+ (1,0) [0|0] "" Vector__XXX
 SG_ VCBATT2_a039_ProtFaultAddress m0 : 42|1@1+ (1,0) [0|0] "" Vector__XXX
 SG_ VCBATT2_a399_frunkNeverReportedOpen m6 : 42|1@1+ (1,0) [0|0] "" Vector__XXX
 SG_ VCBATT2_a040_Backtrace m0 : 43|1@1+ (1,0) [0|0] "" Vector__XXX
 SG_ VCBATT2_a100_CANbus_MIA m1 : 43|1@1+ (1,0) [0|0] "" Vector__XXX
 SG_ VCBATT2_a041_HighCPULoad m0 : 44|1@1+ (1,0) [0|0] "" Vector__XXX
 SG_ VCBATT2_a042_HighStackUsage m0 : 45|1@1+ (1,0) [0|0] "" Vector__XXX
 SG_ VCBATT2_a522_hibernationActiveLogCapture m8 : 45|1@1+ (1,0) [0|0] "" Vector__XXX
 SG_ VCBATT2_a043_Task1msError m0 : 46|1@1+ (1,0) [0|0] "" Vector__XXX
 SG_ VCBATT2_a103_CP_MIA m1 : 46|1@1+ (1,0) [0|0] "" Vector__XXX
 SG_ VCBATT2_a463_frunkSensorService m7 : 46|1@1+ (1,0) [0|0] "" Vector__XXX
 SG_ VCBATT2_a583_frunkSwitchGroupDisagreementDebug m9 : 46|1@1+ (1,0) [0|0] "" Vector__XXX
 SG_ VCBATT2_a643_rightHeadlampUartCondition m10 : 46|1@1+ (1,0) [0|0] "" Vector__XXX
 SG_ VCBATT2_a044_Task10msError m0 : 47|1@1+ (1,0) [0|0] "" Vector__XXX
 SG_ VCBATT2_a104_DAS_MIA m1 : 47|1@1+ (1,0) [0|0] "" Vector__XXX
 SG_ VCBATT2_a524_rightHeadlampAimingFault m8 : 47|1@1+ (1,0) [0|0] "" Vector__XXX
 SG_ VCBATT2_a584_frunkSwitchGroupDebug m9 : 47|1@1+ (1,0) [0|0] "" Vector__XXX
 SG_ VCBATT2_a644_washPumpHealthCalculationDbg0 m10 : 47|1@1+ (1,0) [0|0] "" Vector__XXX
 SG_ VCBATT2_a045_Task100msError m0 : 48|1@1+ (1,0) [0|0] "" Vector__XXX
 SG_ VCBATT2_a105_TAS_MIA m1 : 48|1@1+ (1,0) [0|0] "" Vector__XXX
 SG_ VCBATT2_a645_washPumpHealthCalculationDbg1 m10 : 48|1@1+ (1,0) [0|0] "" Vector__XXX
 SG_ VCBATT2_a046_Task1000msError m0 : 49|1@1+ (1,0) [0|0] "" Vector__XXX
 SG_ VCBATT2_a106_PCS_MIA m1 : 49|1@1+ (1,0) [0|0] "" Vector__XXX
 SG_ VCBATT2_a166_rightHCMMIA m2 : 49|1@1+ (1,0) [0|0] "" Vector__XXX
 SG_ VCBATT2_a586_rightLowOrHighBeamLightCondition m9 : 49|1@1+ (1,0) [0|0] "" Vector__XXX
 SG_ VCBATT2_a646_washPumpHealthCalculationDbg2 m10 : 49|1@1+ (1,0) [0|0] "" Vector__XXX
 SG_ VCBATT2_a107_BMS_MIA m1 : 50|1@1+ (1,0) [0|0] "" Vector__XXX
 SG_ VCBATT2_a227_radFanCompromised m3 : 50|1@1+ (1,0) [0|0] "" Vector__XXX
 SG_ VCBATT2_a108_DIF_MIA m1 : 51|1@1+ (1,0) [0|0] "" Vector__XXX
 SG_ VCBATT2_a649_persistAccPortPowerReqOverridden m10 : 52|1@1+ (1,0) [0|0] "" Vector__XXX
 SG_ VCBATT2_a110_GTW_MIA m1 : 53|1@1+ (1,0) [0|0] "" Vector__XXX
 SG_ VCBATT2_a290_leftFogLightFault m4 : 53|1@1+ (1,0) [0|0] "" Vector__XXX
 SG_ VCBATT2_a111_EPBR_MIA m1 : 54|1@1+ (1,0) [0|0] "" Vector__XXX
 SG_ VCBATT2_a291_rightFogLightFault m4 : 54|1@1+ (1,0) [0|0] "" Vector__XXX
 SG_ VCBATT2_a471_emergencyFrunkButtonPressIgnored m7 : 54|1@1+ (1,0) [0|0] "" Vector__XXX
 SG_ VCBATT2_a112_EPBL_MIA m1 : 55|1@1+ (1,0) [0|0] "" Vector__XXX
 SG_ VCBATT2_a292_sideMarkerLightPipeFault m4 : 55|1@1+ (1,0) [0|0] "" Vector__XXX
 SG_ VCBATT2_a113_UI_MIA m1 : 56|1@1+ (1,0) [0|0] "" Vector__XXX
 SG_ VCBATT2_a353_wiperHeaterUndercurrent m5 : 56|1@1+ (1,0) [0|0] "" Vector__XXX
 SG_ VCBATT2_a114_ESP_MIA m1 : 57|1@1+ (1,0) [0|0] "" Vector__XXX
 SG_ VCBATT2_a354_windshieldCameraHeaterUndercurrent m5 : 57|1@1+ (1,0) [0|0] "" Vector__XXX
 SG_ VCBATT2_a115_VCSEC_MIA m1 : 58|1@1+ (1,0) [0|0] "" Vector__XXX
 SG_ VCBATT2_a295_rightSideRepeaterLightFault m4 : 58|1@1+ (1,0) [0|0] "" Vector__XXX
 SG_ VCBATT2_a475_rightHeadlampInternalError m7 : 58|1@1+ (1,0) [0|0] "" Vector__XXX
 SG_ VCBATT2_a116_VCRIGHT_MIA m1 : 59|1@1+ (1,0) [0|0] "" Vector__XXX
 SG_ VCBATT2_a117_VCLEFT_MIA m1 : 60|1@1+ (1,0) [0|0] "" Vector__XXX
 SG_ VCBATT2_a058_inputRHighSyncDebug m0 : 61|1@1+ (1,0) [0|0] "" Vector__XXX
 SG_ VCBATT2_a118_VCFRONT_MIA m1 : 61|1@1+ (1,0) [0|0] "" Vector__XXX
 SG_ VCBATT2_a059_inputResistanceHigh m0 : 62|1@1+ (1,0) [0|0] "" Vector__XXX
 SG_ VCBATT2_a119_SCCM_MIA m1 : 62|1@1+ (1,0) [0|0] "" Vector__XXX
 SG_ VCBATT2_a299_homelinkConfigurationFailed m4 : 62|1@1+ (1,0) [0|0] "" Vector__XXX
 SG_ VCBATT2_a060_engineeringBuild m0 : 63|1@1+ (1,0) [0|0] "" Vector__XXX
 SG_ VCBATT2_a120_DI_DRIVE_MIA m1 : 63|1@1+ (1,0) [0|0] "" Vector__XXX
 SG_ VCBATT2_a300_louverActuatorSwapDetected m4 : 63|1@1+ (1,0) [0|0] "" Vector__XXX

BO_ 978 BMS_kwhCounter: 8 Vector__XXX
 SG_ BMS_kwhDischargeTotal : 0|32@1+ (0.001,0) [0|0] "" Vector__XXX
 SG_ BMS_kwhChargeTotal : 32|32@1+ (0.001,0) [0|0] "" Vector__XXX

BO_ 979 VCRIGHT_crashStatus: 8 Vector__XXX
 SG_ VCRIGHT_crashDetectedType : 0|2@1+ (1,0) [0|0] "" Vector__XXX
 SG_ VCRIGHT_crashState : 4|2@1+ (1,0) [0|0] "" Vector__XXX
 SG_ VCRIGHT_crashNumSwitchesDisabled : 8|8@1+ (1,0) [0|0] "" Vector__XXX
 SG_ VCRIGHT_crashUnlockOverrideSet : 16|1@1+ (1,0) [0|0] "" Vector__XXX

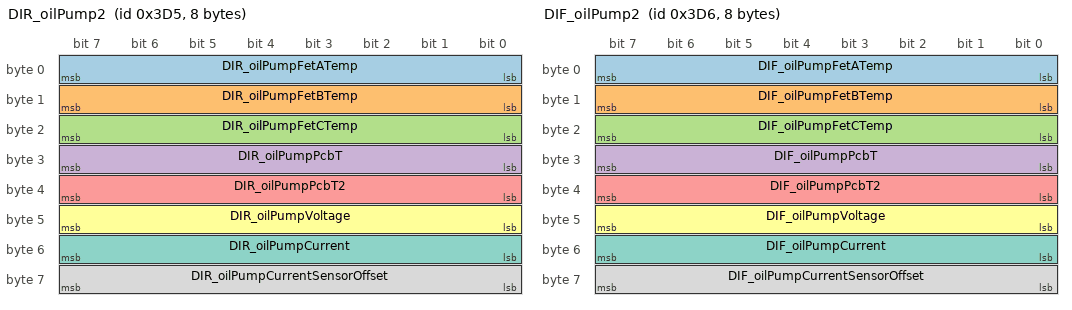
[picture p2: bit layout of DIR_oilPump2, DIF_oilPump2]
BO_ 981 DIR_oilPump2: 8 Vector__XXX
 SG_ DIR_oilPumpFetATemp : 0|8@1+ (1,-40) [0|0] "" Vector__XXX
 SG_ DIR_oilPumpFetBTemp : 8|8@1+ (1,-40) [0|0] "" Vector__XXX
 SG_ DIR_oilPumpFetCTemp : 16|8@1+ (1,-40) [0|0] "" Vector__XXX
 SG_ DIR_oilPumpPcbT : 24|8@1+ (1,-40) [0|0] "" Vector__XXX
 SG_ DIR_oilPumpPcbT2 : 32|8@1+ (1,-40) [0|0] "" Vector__XXX
 SG_ DIR_oilPumpVoltage : 40|8@1+ (0.3,0) [0|0] "" Vector__XXX
 SG_ DIR_oilPumpCurrent : 48|8@1+ (0.1,0) [0|0] "" Vector__XXX
 SG_ DIR_oilPumpCurrentSensorOffset : 56|8@1+ (0.005,0) [0|0] "" Vector__XXX

BO_ 982 DIF_oilPump2: 8 Vector__XXX
 SG_ DIF_oilPumpFetATemp : 0|8@1+ (1,-40) [0|0] "" Vector__XXX
 SG_ DIF_oilPumpFetBTemp : 8|8@1+ (1,-40) [0|0] "" Vector__XXX
 SG_ DIF_oilPumpFetCTemp : 16|8@1+ (1,-40) [0|0] "" Vector__XXX
 SG_ DIF_oilPumpPcbT : 24|8@1+ (1,-40) [0|0] "" Vector__XXX
 SG_ DIF_oilPumpPcbT2 : 32|8@1+ (1,-40) [0|0] "" Vector__XXX
 SG_ DIF_oilPumpVoltage : 40|8@1+ (0.3,0) [0|0] "" Vector__XXX
 SG_ DIF_oilPumpCurrent : 48|8@1+ (0.1,0) [0|0] "" Vector__XXX
 SG_ DIF_oilPumpCurrentSensorOffset : 56|8@1+ (0.005,0) [0|0] "" Vector__XXX

BO_ 984 UI_elevationStatus: 8 Vector__XXX
 SG_ UI_elevation : 0|14@1- (1,0) [0|0] "" Vector__XXX
 SG_ UI_navElevation : 16|14@1- (1,0) [0|0] "" Vector__XXX

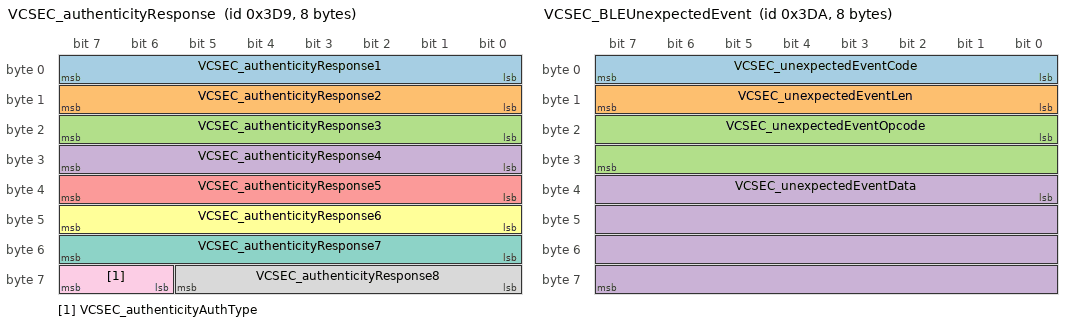
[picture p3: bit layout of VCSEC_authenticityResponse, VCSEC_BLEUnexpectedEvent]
BO_ 985 VCSEC_authenticityResponse: 8 Vector__XXX
 SG_ VCSEC_authenticityResponse1 : 0|8@1+ (1,0) [0|0] "" Vector__XXX
 SG_ VCSEC_authenticityResponse2 : 8|8@1+ (1,0) [0|0] "" Vector__XXX
 SG_ VCSEC_authenticityResponse3 : 16|8@1+ (1,0) [0|0] "" Vector__XXX
 SG_ VCSEC_authenticityResponse4 : 24|8@1+ (1,0) [0|0] "" Vector__XXX
 SG_ VCSEC_authenticityResponse5 : 32|8@1+ (1,0) [0|0] "" Vector__XXX
 SG_ VCSEC_authenticityResponse6 : 40|8@1+ (1,0) [0|0] "" Vector__XXX
 SG_ VCSEC_authenticityResponse7 : 48|8@1+ (1,0) [0|0] "" Vector__XXX
 SG_ VCSEC_authenticityResponse8 : 56|6@1+ (1,0) [0|0] "" Vector__XXX
 SG_ VCSEC_authenticityAuthType : 62|2@1+ (1,0) [0|0] "" Vector__XXX

BO_ 986 VCSEC_BLEUnexpectedEvent: 8 Vector__XXX
 SG_ VCSEC_unexpectedEventCode : 0|8@1+ (1,0) [0|0] "" Vector__XXX
 SG_ VCSEC_unexpectedEventLen : 8|8@1+ (1,0) [0|0] "" Vector__XXX
 SG_ VCSEC_unexpectedEventOpcode : 16|16@1+ (1,0) [0|0] "" Vector__XXX
 SG_ VCSEC_unexpectedEventData : 32|32@1+ (1,0) [0|0] "" Vector__XXX

BO_ 987 VCSEC_endpointTemp: 8 Vector__XXX
 SG_ VCSEC_endpointDataIndex M : 0|4@1+ (1,0) [0|0] "" Vector__XXX
 SG_ VCSEC_leftBLEDrift m0 : 4|2@1+ (1,0) [0|0] "" Vector__XXX
 SG_ VCSEC_requestSleepBitfield m3 : 4|30@1+ (1,0) [0|0] "" Vector__XXX
 SG_ VCSEC_sleepFlagNFCFieldControl m7 : 4|2@1+ (1,0) [0|0] "" Vector__XXX
 SG_ VCSEC_rightBLEDrift m0 : 6|2@1+ (1,0) [0|0] "" Vector__XXX
 SG_ VCSEC_sleepFlagGATTServer m7 : 6|2@1+ (1,0) [0|0] "" Vector__XXX
 SG_ VCSEC_centerEndpointTemp m10 : 8|8@1- (1,0) [0|0] "" Vector__XXX
 SG_ VCSEC_centerLeftRSSI m2 : 8|8@1- (1,0) [0|0] "" Vector__XXX
 SG_ VCSEC_frontEndpointTemp m9 : 8|8@1- (1,0) [0|0] "" Vector__XXX
 SG_ VCSEC_heapWatermark m11 : 8|16@1+ (1,0) [0|0] "" Vector__XXX
 SG_ VCSEC_rearBLEDrift m0 : 8|2@1+ (1,0) [0|0] "" Vector__XXX
 SG_ VCSEC_rightLeftRSSI m1 : 8|8@1- (1,0) [0|0] "" Vector__XXX
 SG_ VCSEC_silentWakeCountFront m5 : 8|14@1+ (1,0) [0|0] "" Vector__XXX
 SG_ VCSEC_silentWakeCountLeft m8 : 8|14@1+ (1,0) [0|0] "" Vector__XXX
 SG_ VCSEC_silentWakeCountNFCCradle m4 : 8|14@1+ (1,0) [0|0] "" Vector__XXX
 SG_ VCSEC_sleepCountDelta m6 : 8|16@1+ (1,0) [0|0] "" Vector__XXX
 SG_ VCSEC_sleepFlagNFC m7 : 8|2@1+ (1,0) [0|0] "" Vector__XXX
 SG_ VCSEC_frontBLEDrift m0 : 10|2@1+ (1,0) [0|0] "" Vector__XXX
 SG_ VCSEC_sleepFlagBLEEndpointReset m7 : 10|2@1+ (1,0) [0|0] "" Vector__XXX
 SG_ VCSEC_rearLeftBLEDrift m0 : 12|2@1+ (1,0) [0|0] "" Vector__XXX
 SG_ VCSEC_sleepFlagOvertTemperatureMonitor m7 : 12|2@1+ (1,0) [0|0] "" Vector__XXX
 SG_ VCSEC_rearRightBLEDrift m0 : 14|2@1+ (1,0) [0|0] "" Vector__XXX
 SG_ VCSEC_sleepFlagAdvScanner m7 : 14|2@1+ (1,0) [0|0] "" Vector__XXX
 SG_ VCSEC_centerRightRSSI m2 : 16|8@1- (1,0) [0|0] "" Vector__XXX
 SG_ VCSEC_frontLeftBLEDrift m0 : 16|2@1+ (1,0) [0|0] "" Vector__XXX
 SG_ VCSEC_leftEndpointTemp m10 : 16|8@1- (1,0) [0|0] "" Vector__XXX
 SG_ VCSEC_rightRearRSSI m1 : 16|8@1- (1,0) [0|0] "" Vector__XXX
 SG_ VCSEC_secondaryEndpointTemp m9 : 16|8@1- (1,0) [0|0] "" Vector__XXX
 SG_ VCSEC_sleepFlagBLEConnections m7 : 16|2@1+ (1,0) [0|0] "" Vector__XXX
 SG_ VCSEC_frontRightBLEDrift m0 : 18|2@1+ (1,0) [0|0] "" Vector__XXX
 SG_ VCSEC_sleepFlagConnectionMonitor m7 : 18|2@1+ (1,0) [0|0] "" Vector__XXX
 SG_ VCSEC_secondaryBLEDrift m0 : 20|2@1+ (1,0) [0|0] "" Vector__XXX
 SG_ VCSEC_sleepFlagAlarm m7 : 20|2@1+ (1,0) [0|0] "" Vector__XXX
 SG_ VCSEC_NFCCradleBLEDrift m0 : 22|2@1+ (1,0) [0|0] "" Vector__XXX
 SG_ VCSEC_silentWakeCountRight m8 : 22|14@1+ (1,0) [0|0] "" Vector__XXX
 SG_ VCSEC_silentWakeCountSecondary m5 : 22|14@1+ (1,0) [0|0] "" Vector__XXX
 SG_ VCSEC_sleepFlagKeyfobConnector m7 : 22|2@1+ (1,0) [0|0] "" Vector__XXX
 SG_ VCSEC_NFCCradleEndpointTemp m9 : 24|8@1- (1,0) [0|0] "" Vector__XXX
 SG_ VCSEC_centerRearRSSI m2 : 24|8@1- (1,0) [0|0] "" Vector__XXX
 SG_ VCSEC_heapCurrentSize m11 : 24|16@1+ (1,0) [0|0] "" Vector__XXX
 SG_ VCSEC_rearCenterRSSI m1 : 24|8@1- (1,0) [0|0] "" Vector__XXX
 SG_ VCSEC_rightEndpointTemp m10 : 24|8@1- (1,0) [0|0] "" Vector__XXX
 SG_ VCSEC_silentAwakeTimeSeconds m6 : 24|21@1+ (1,0) [0|0] "" Vector__XXX
 SG_ VCSEC_sleepFlagGap m7 : 24|2@1+ (1,0) [0|0] "" Vector__XXX
 SG_ VCSEC_timeFromWakeToLoggingAvailable m4 : 24|16@1+ (1,0) [0|0] "" Vector__XXX
 SG_ VCSEC_sleepFlgBLEEndpointSleepControl m7 : 26|2@1+ (1,0) [0|0] "" Vector__XXX
 SG_ VCSEC_sleepFlagNFCCardPresent m7 : 28|2@1+ (1,0) [0|0] "" Vector__XXX
 SG_ VCSEC_sleepFlagNVMWriteFailed m7 : 30|2@1+ (1,0) [0|0] "" Vector__XXX
 SG_ VCSEC_leftCenterRSSI m2 : 32|8@1- (1,0) [0|0] "" Vector__XXX
 SG_ VCSEC_leftRearEndpointTemp m9 : 32|8@1- (1,0) [0|0] "" Vector__XXX
 SG_ VCSEC_rearEndpointTemp m10 : 32|8@1- (1,0) [0|0] "" Vector__XXX
 SG_ VCSEC_rearLeftRSSI m1 : 32|8@1- (1,0) [0|0] "" Vector__XXX
 SG_ VCSEC_sleepFlagTireId m7 : 32|2@1+ (1,0) [0|0] "" Vector__XXX
 SG_ VCSEC_readyToSleepBitfield m3 : 34|30@1+ (1,0) [0|0] "" Vector__XXX
 SG_ VCSEC_sleepFlagUWBUpdater m7 : 34|2@1+ (1,0) [0|0] "" Vector__XXX
 SG_ VCSEC_silentWakeCountLeftRear m5 : 36|14@1+ (1,0) [0|0] "" Vector__XXX
 SG_ VCSEC_silentWakeCountRear m8 : 36|14@1+ (1,0) [0|0] "" Vector__XXX
 SG_ VCSEC_wokeFromSleep m7 : 36|1@1+ (1,0) [0|0] "" Vector__XXX
 SG_ VCSEC_sleepFlagECULogUpload m7 : 37|2@1+ (1,0) [0|0] "" Vector__XXX
 SG_ VCSEC_infotainmentPairingStatus m11 : 40|2@1+ (1,0) [0|0] "" Vector__XXX
 SG_ VCSEC_leftRightRSSI m2 : 40|8@1- (1,0) [0|0] "" Vector__XXX
 SG_ VCSEC_rearRightRSSI m1 : 40|8@1- (1,0) [0|0] "" Vector__XXX
 SG_ VCSEC_rightRearEndpointTemp m9 : 40|8@1- (1,0) [0|0] "" Vector__XXX
 SG_ VCSEC_silentPresentTime m6 : 45|18@1+ (1,0) [0|0] "" Vector__XXX
 SG_ VCSEC_leftFrontEndpointTemp m9 : 48|8@1- (1,0) [0|0] "" Vector__XXX
 SG_ VCSEC_leftRearRSSI m2 : 48|8@1- (1,0) [0|0] "" Vector__XXX
 SG_ VCSEC_silentWakeCountCenter m8 : 50|14@1+ (1,0) [0|0] "" Vector__XXX
 SG_ VCSEC_silentWakeCountRightRear m5 : 50|14@1+ (1,0) [0|0] "" Vector__XXX
 SG_ VCSEC_rightCenterRSSI m2 : 56|8@1- (1,0) [0|0] "" Vector__XXX
 SG_ VCSEC_rightFrontEndpointTemp m9 : 56|8@1- (1,0) [0|0] "" Vector__XXX

BO_ 989 CP_loggingSlow: 8 Vector__XXX
 SG_ CP_loggingSlowSelect M : 0|4@1+ (1,0) [0|0] "" Vector__XXX
 SG_ CP_5vSwV m4 : 4|8@1+ (0.027450980392156862,0) [0|0] "" Vector__XXX
 SG_ CP_UHF_chipState m3 : 4|3@1+ (1,0) [0|0] "" Vector__XXX
 SG_ CP_backCoverCounts m1 : 4|12@1+ (0.025,0) [0|0] "" Vector__XXX
 SG_ CP_cpuUtilization_intervalMax10s m7 : 4|7@1+ (0.7874015748031497,0) [0|0] "" Vector__XXX
 SG_ CP_nvm_dataValid m5 : 4|1@1+ (1,0) [0|0] "" Vector__XXX
 SG_ CP_pilotLowValue_intervalMax10s m2 : 4|12@1- (0.01,0) [0|0] "" Vector__XXX
 SG_ CP_proximityV_intervalMax10s m0 : 4|16@1+ (0.0001,0) [0|0] "" Vector__XXX
 SG_ CP_nvm_doorOpenCycles m5 : 5|16@1+ (1,0) [0|0] "" Vector__XXX
 SG_ CP_UHF_rssi m3 : 8|8@1+ (1,0) [0|0] "" Vector__XXX
 SG_ CP_tlsMemoryUsage_intervalMax10s m6 : 8|7@1+ (0.7874015748031497,0) [0|0] "" Vector__XXX
 SG_ CP_cpuUtilization_intervalMin10s m7 : 11|7@1+ (0.7874015748031497,0) [0|0] "" Vector__XXX
 SG_ CP_boardTemperature m4 : 12|8@1+ (1.29411764706,-50) [0|0] "" Vector__XXX
 SG_ CP_UHF_rxOverflow m3 : 16|1@1+ (1,0) [0|0] "" Vector__XXX
 SG_ CP_backCover2Counts m1 : 16|12@1+ (0.025,0) [0|0] "" Vector__XXX
 SG_ CP_pilotLowValue_intervalMin10s m2 : 16|12@1- (0.01,0) [0|0] "" Vector__XXX
 SG_ CP_tlsMemoryUsage_intervalMin10s m6 : 16|7@1+ (0.7874015748031497,0) [0|0] "" Vector__XXX
 SG_ CP_UHF_rxNumBytes m3 : 17|8@1+ (1,0) [0|0] "" Vector__XXX
 SG_ CP_doorButtonPressDurationMs m7 : 18|10@1+ (1,0) [0|0] "" Vector__XXX
 SG_ CP_proximityV_intervalMin10s m0 : 20|16@1+ (0.0001,0) [0|0] "" Vector__XXX
 SG_ CP_refVoltage m4 : 20|8@1+ (0.0070588235,0) [0|0] "" Vector__XXX
 SG_ CP_nvm_doorCloseCycles m5 : 21|16@1+ (1,0) [0|0] "" Vector__XXX
 SG_ CP_acRetryTimeoutS m6 : 23|15@1+ (1,0) [0|0] "" Vector__XXX
 SG_ CP_UHF_selfTestRssi m3 : 25|8@1+ (1,0) [0|0] "" Vector__XXX
 SG_ CP_doorId_intervalMin10s m4 : 28|8@1+ (0.0196078431372549,0) [0|0] "" Vector__XXX
 SG_ CP_inductiveSensorBaseline m7 : 28|28@1+ (0.08083879947662354,0) [0|0] "" Vector__XXX
 SG_ CP_ivledState m1 : 28|2@1+ (1,0) [0|0] "" Vector__XXX
 SG_ CP_pilotHighValue_intervalMax10s m2 : 28|12@1- (0.01,0) [0|0] "" Vector__XXX
 SG_ CP_ivledV m1 : 32|8@1+ (0.01968504,0) [0|0] "" Vector__XXX
 SG_ CP_latchI m3 : 33|12@1+ (0.0025,0) [0|0] "" Vector__XXX
 SG_ CP_doorId_intervalMax10s m4 : 36|8@1+ (0.0196078431372549,0) [0|0] "" Vector__XXX
 SG_ CP_inlet1HarnessV m0 : 36|14@1+ (0.001,0) [0|0] "" Vector__XXX
 SG_ CP_nvm_doorOpen m5 : 37|1@1+ (1,0) [0|0] "" Vector__XXX
 SG_ CP_acNextRetryTimeoutS m6 : 38|15@1+ (1,0) [0|0] "" Vector__XXX
 SG_ CP_nvm_doorPresent m5 : 38|1@1+ (1,0) [0|0] "" Vector__XXX
 SG_ CP_nvm_doorPresentValid m5 : 39|1@1+ (1,0) [0|0] "" Vector__XXX
 SG_ CP_nvm_badPilotDiodeDetected m5 : 40|1@1+ (1,0) [0|0] "" Vector__XXX
 SG_ CP_pilotHighValue_intervalMin10s m2 : 40|12@1- (0.01,0) [0|0] "" Vector__XXX
 SG_ CP_plcV m1 : 40|8@1+ (0.01294118,0) [0|0] "" Vector__XXX
 SG_ CP_nvm_pilotDiodeFaultCount m5 : 41|3@1+ (1,0) [0|0] "" Vector__XXX
 SG_ CP_doorOpenLimiterMaxCount m5 : 44|4@1+ (1,0) [0|0] "" Vector__XXX
 SG_ CP_inlet1HarnessIdState m3 : 45|2@1+ (1,0) [0|0] "" Vector__XXX
 SG_ CP_inlet1HarnessIdValue m3 : 47|3@1+ (1,0) [0|0] "" Vector__XXX
 SG_ CP_doorOpenLimiterMaxRequestType m5 : 48|4@1+ (1,0) [0|0] "" Vector__XXX
 SG_ CP_sensorExtV m1 : 48|8@1+ (0.01968504,0) [0|0] "" Vector__XXX
 SG_ CP_inlet2HarnessIdState m3 : 50|2@1+ (1,0) [0|0] "" Vector__XXX
 SG_ CP_inlet2HarnessV m0 : 50|14@1+ (0.001,0) [0|0] "" Vector__XXX
 SG_ CP_doorCloseLimiterMaxCount m5 : 52|4@1+ (1,0) [0|0] "" Vector__XXX
 SG_ CP_faultLineV m2 : 52|10@1+ (0.004550576735092864,0) [0|0] "" Vector__XXX
 SG_ CP_inlet2HarnessIdValue m3 : 52|3@1+ (1,0) [0|0] "" Vector__XXX
 SG_ CP_acNumRetries m6 : 53|8@1+ (1,0) [0|0] "" Vector__XXX
 SG_ CP_inletHeaterState m3 : 55|2@1+ (1,0) [0|0] "" Vector__XXX
 SG_ CP_backCoverState m1 : 56|3@1+ (1,0) [0|0] "" Vector__XXX
 SG_ CP_doorCloseLimiterMaxRequestType m5 : 56|5@1+ (1,0) [0|0] "" Vector__XXX
 SG_ CP_uhfDoorRequestCounts m7 : 56|5@1+ (1,0) [0|0] "" Vector__XXX
 SG_ CP_inletHeaterDuty m3 : 57|7@1+ (1,0) [0|0] "" Vector__XXX
 SG_ CP_backCover2State m1 : 59|3@1+ (1,0) [0|0] "" Vector__XXX
 SG_ CP_wakeOnPushCounter m4 : 60|3@1+ (1,0) [0|0] "" Vector__XXX
 SG_ CP_pilotWakeCounter m6 : 61|3@1+ (1,0) [0|0] "" Vector__XXX
 SG_ CP_proximityWakeCounter m5 : 61|3@1+ (1,0) [0|0] "" Vector__XXX
 SG_ CP_faultLineSetByCP m2 : 62|1@1+ (1,0) [0|0] "" Vector__XXX
 SG_ CP_doorPushLockoutActive m4 : 63|1@1+ (1,0) [0|0] "" Vector__XXX

BO_ 990 FC_alertMatrix6: 8 Vector__XXX
 SG_ FC_a321_FCAlertPlaceholder : 0|1@1+ (1,0) [0|0] "" Vector__XXX

BO_ 991 UI_status2: 8 Vector__XXX
 SG_ UI_mobileAppStepCount : 0|16@1+ (1,0) [0|0] "" Vector__XXX
 SG_ UI_userRequestSnapshot : 16|1@1+ (1,0) [0|0] "" Vector__XXX
 SG_ UI_touchDetected : 17|1@1+ (1,0) [0|0] "" Vector__XXX
 SG_ UI_validDeviceForEUSummon : 18|1@1+ (1,0) [0|0] "" Vector__XXX
 SG_ UI_locatedAtHome : 19|1@1+ (1,0) [0|0] "" Vector__XXX
 SG_ UI_locatedAtWork : 20|1@1+ (1,0) [0|0] "" Vector__XXX
 SG_ UI_locatedAtFavorite : 21|1@1+ (1,0) [0|0] "" Vector__XXX
 SG_ UI_displayInDarkMode : 22|1@1+ (1,0) [0|0] "" Vector__XXX
 SG_ UI_userActivity : 23|1@1+ (1,0) [0|0] "" Vector__XXX
 SG_ UI_activeTouchPoints : 24|8@1+ (1,0) [0|0] "" Vector__XXX
 SG_ UI_linkState : 32|2@1+ (1,0) [0|0] "" Vector__XXX
 SG_ UI_sentryModeState : 34|3@1+ (1,0) [0|0] "" Vector__XXX
 SG_ UI_autopilotSentryRequest : 37|1@1+ (1,0) [0|0] "" Vector__XXX
 SG_ UI_mobileAppConnected : 38|1@1+ (1,0) [0|0] "" Vector__XXX
 SG_ UI_phoneLeftInCabin : 39|1@1+ (1,0) [0|0] "" Vector__XXX
 SG_ UI_autoshiftDRState : 40|3@1+ (1,0) [0|0] "" Vector__XXX
 SG_ UI_wifiBtModuleType : 43|3@1+ (1,0) [0|0] "" Vector__XXX
 SG_ UI_sohHealthStatus : 46|2@1+ (1,0) [0|0] "" Vector__XXX
 SG_ UI_selfParkState : 48|8@1+ (1,0) [0|0] "" Vector__XXX
 SG_ UI_summonDeviceIndex : 56|2@1+ (1,0) [0|0] "" Vector__XXX
 SG_ UI_fullScreenMode : 58|1@1+ (1,0) [0|0] "" Vector__XXX
 SG_ UI_sentryModeCameraDetection : 59|1@1+ (1,0) [0|0] "" Vector__XXX
 SG_ UI_wakeOnIPActive : 60|1@1+ (1,0) [0|0] "" Vector__XXX
 SG_ UI_sapActive : 61|1@1+ (1,0) [0|0] "" Vector__XXX
 SG_ UI_sapClients : 62|1@1+ (1,0) [0|0] "" Vector__XXX
 SG_ UI_connectivityStandbyActive : 63|1@1+ (1,0) [0|0] "" Vector__XXX

BO_ 994 VCLEFT_lightStatus: 8 Vector__XXX
 SG_ VCLEFT_brakeLightStatus : 0|2@1+ (1,0) [0|0] "" Vector__XXX
 SG_ VCLEFT_tailLightStatus : 2|2@1+ (1,0) [0|0] "" Vector__XXX
 SG_ VCLEFT_turnSignalStatus : 4|2@1+ (1,0) [0|0] "" Vector__XXX
 SG_ VCLEFT_FLMapLightStatus : 6|2@1+ (1,0) [0|0] "" Vector__XXX
 SG_ VCLEFT_FRMapLightStatus : 8|2@1+ (1,0) [0|0] "" Vector__XXX
 SG_ VCLEFT_RLMapLightStatus : 10|2@1+ (1,0) [0|0] "" Vector__XXX
 SG_ VCLEFT_RRMapLightStatus : 12|2@1+ (1,0) [0|0] "" Vector__XXX
 SG_ VCLEFT_FLMapLightSwitchPressed : 14|1@1+ (1,0) [0|0] "" Vector__XXX
 SG_ VCLEFT_FRMapLightSwitchPressed : 15|1@1+ (1,0) [0|0] "" Vector__XXX
 SG_ VCLEFT_RLMapLightSwitchPressed : 16|1@1+ (1,0) [0|0] "" Vector__XXX
 SG_ VCLEFT_RRMapLightSwitchPressed : 17|1@1+ (1,0) [0|0] "" Vector__XXX
 SG_ VCLEFT_leftTurnTrailerLightStatus : 18|2@1+ (1,0) [0|0] "" Vector__XXX
 SG_ VCLEFT_rightTrnTrailerLightStatus : 20|2@1+ (1,0) [0|0] "" Vector__XXX
 SG_ VCLEFT_brakeTrailerLightStatus : 22|2@1+ (1,0) [0|0] "" Vector__XXX
 SG_ VCLEFT_tailTrailerLightStatus : 24|2@1+ (1,0) [0|0] "" Vector__XXX
 SG_ VCLEFT_fogTrailerLightStatus : 26|2@1+ (1,0) [0|0] "" Vector__XXX
 SG_ VCLEFT_frontRideHeight : 28|8@1- (1,0) [0|0] "" Vector__XXX
 SG_ VCLEFT_rearRideHeight : 36|8@1- (1,0) [0|0] "" Vector__XXX
 SG_ VCLEFT_trailerDetected : 46|2@1+ (1,0) [0|0] "" Vector__XXX
 SG_ VCLEFT_rideHeightSensorFault : 48|1@1+ (1,0) [0|0] "" Vector__XXX
 SG_ VCLEFT_reverseTrailerLightStatus : 49|2@1+ (1,0) [0|0] "" Vector__XXX
 SG_ VCLEFT_tailLightOutageStatus : 51|1@1+ (1,0) [0|0] "" Vector__XXX

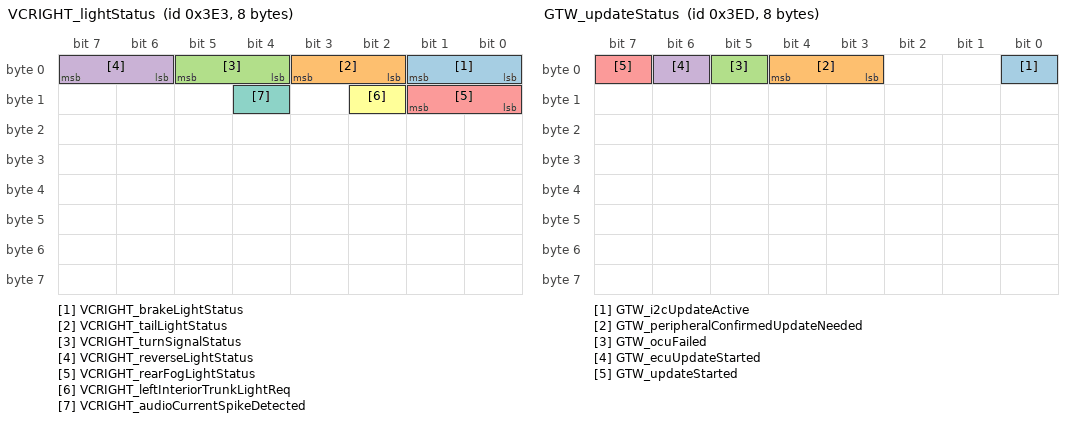
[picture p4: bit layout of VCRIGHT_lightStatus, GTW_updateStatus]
BO_ 995 VCRIGHT_lightStatus: 8 Vector__XXX
 SG_ VCRIGHT_brakeLightStatus : 0|2@1+ (1,0) [0|0] "" Vector__XXX
 SG_ VCRIGHT_tailLightStatus : 2|2@1+ (1,0) [0|0] "" Vector__XXX
 SG_ VCRIGHT_turnSignalStatus : 4|2@1+ (1,0) [0|0] "" Vector__XXX
 SG_ VCRIGHT_reverseLightStatus : 6|2@1+ (1,0) [0|0] "" Vector__XXX
 SG_ VCRIGHT_rearFogLightStatus : 8|2@1+ (1,0) [0|0] "" Vector__XXX
 SG_ VCRIGHT_leftInteriorTrunkLightReq : 10|1@1+ (1,0) [0|0] "" Vector__XXX
 SG_ VCRIGHT_audioCurrentSpikeDetected : 12|1@1+ (1,0) [0|0] "" Vector__XXX

BO_ 996 PCS2_alertMatrix: 8 Vector__XXX
 SG_ PCS2_matrixIndex M : 0|4@1+ (1,0) [0|0] "" Vector__XXX
 SG_ PCS2_a001_watchdogAlarmed m0 : 4|1@1+ (1,0) [0|0] "" Vector__XXX
 SG_ PCS2_a061_cycloBFaulted m1 : 4|1@1+ (1,0) [0|0] "" Vector__XXX
 SG_ PCS2_a121_insufficientCoolingDetected m2 : 4|1@1+ (1,0) [0|0] "" Vector__XXX
 SG_ PCS2_d181_dcdcConverterVoltSensorAFault m3 : 4|1@1+ (1,0) [0|0] "" Vector__XXX
 SG_ PCS2_a002_canRationality m0 : 5|1@1+ (1,0) [0|0] "" Vector__XXX
 SG_ PCS2_a062_acVoltageNotPresent m1 : 5|1@1+ (1,0) [0|0] "" Vector__XXX
 SG_ PCS2_a122_dcacLifetimekVAhRecordError m2 : 5|1@1+ (1,0) [0|0] "" Vector__XXX
 SG_ PCS2_a003_softwareAssertion m0 : 6|1@1+ (1,0) [0|0] "" Vector__XXX
 SG_ PCS2_a063_chgUnknownGridConfig m1 : 6|1@1+ (1,0) [0|0] "" Vector__XXX
 SG_ PCS2_a123_DcdcBHvOverTemp m2 : 6|1@1+ (1,0) [0|0] "" Vector__XXX
 SG_ PCS2_a004_acL1NOverVoltage m0 : 7|1@1+ (1,0) [0|0] "" Vector__XXX
 SG_ PCS2_a064_dcdcATankParametersOutOfSpec m1 : 7|1@1+ (1,0) [0|0] "" Vector__XXX
 SG_ PCS2_a124_dcacItankSoftwareOC m2 : 7|1@1+ (1,0) [0|0] "" Vector__XXX
 SG_ PCS2_a005_acL1OverCurrent m0 : 8|1@1+ (1,0) [0|0] "" Vector__XXX
 SG_ PCS2_a065_dcdcBTankParametersOutOfSpec m1 : 8|1@1+ (1,0) [0|0] "" Vector__XXX
 SG_ PCS2_a125_cycloIdleShortingNeutral m2 : 8|1@1+ (1,0) [0|0] "" Vector__XXX
 SG_ PCS2_a006_acL2NOverVoltage m0 : 9|1@1+ (1,0) [0|0] "" Vector__XXX
 SG_ PCS2_a066_cycloATankParametersOutOfSpec m1 : 9|1@1+ (1,0) [0|0] "" Vector__XXX
 SG_ PCS2_a126_ipcSuccessiveLockGrabFailure m2 : 9|1@1+ (1,0) [0|0] "" Vector__XXX
 SG_ PCS2_a007_acL2OverCurrent m0 : 10|1@1+ (1,0) [0|0] "" Vector__XXX
 SG_ PCS2_a067_cycloBTankParametersOutOfSpec m1 : 10|1@1+ (1,0) [0|0] "" Vector__XXX
 SG_ PCS2_a127_cycloAgdpsHealthCheckFailed m2 : 10|1@1+ (1,0) [0|0] "" Vector__XXX
 SG_ PCS2_a008_acL3NOverVoltage m0 : 11|1@1+ (1,0) [0|0] "" Vector__XXX
 SG_ PCS2_a068_nvmSubsystemStalled m1 : 11|1@1+ (1,0) [0|0] "" Vector__XXX
 SG_ PCS2_a128_cycloBgdpsHealthCheckFailed m2 : 11|1@1+ (1,0) [0|0] "" Vector__XXX
 SG_ PCS2_a009_acL3OverCurrent m0 : 12|1@1+ (1,0) [0|0] "" Vector__XXX
 SG_ PCS2_a069_dcdcAlifetimeEnergyRecordFaulty m1 : 12|1@1+ (1,0) [0|0] "" Vector__XXX
 SG_ PCS2_a129_lossOfZcdEventControl m2 : 12|1@1+ (1,0) [0|0] "" Vector__XXX
 SG_ PCS2_a010_acLNOverCurrent m0 : 13|1@1+ (1,0) [0|0] "" Vector__XXX
 SG_ PCS2_a070_dcdcBlifetimeEnergyRecordFaulty m1 : 13|1@1+ (1,0) [0|0] "" Vector__XXX
 SG_ PCS2_a130_IONVMMServerRetryEvent m2 : 13|1@1+ (1,0) [0|0] "" Vector__XXX
 SG_ PCS2_a011_hvdcOverCurrent m0 : 14|1@1+ (1,0) [0|0] "" Vector__XXX
 SG_ PCS2_a071_hvBattBotSensorIrrational m1 : 14|1@1+ (1,0) [0|0] "" Vector__XXX
 SG_ PCS2_a131_microgridHeartbeatDetected m2 : 14|1@1+ (1,0) [0|0] "" Vector__XXX
 SG_ PCS2_a012_cycloATankOverCurrent m0 : 15|1@1+ (1,0) [0|0] "" Vector__XXX
 SG_ PCS2_a072_hvBattTopSensorIrrational m1 : 15|1@1+ (1,0) [0|0] "" Vector__XXX
 SG_ PCS2_a132_microgridDroopDetected m2 : 15|1@1+ (1,0) [0|0] "" Vector__XXX
 SG_ PCS2_a013_DcdcALv2OverTemp m0 : 16|1@1+ (1,0) [0|0] "" Vector__XXX
 SG_ PCS2_a073_hvBusBotSensorIrrational m1 : 16|1@1+ (1,0) [0|0] "" Vector__XXX
 SG_ PCS2_a133_unused m2 : 16|1@1+ (1,0) [0|0] "" Vector__XXX
 SG_ PCS2_a014_cycloBTankOverCurrent m0 : 17|1@1+ (1,0) [0|0] "" Vector__XXX
 SG_ PCS2_a074_hvBusTopSensorIrrational m1 : 17|1@1+ (1,0) [0|0] "" Vector__XXX
 SG_ PCS2_a134_unused m2 : 17|1@1+ (1,0) [0|0] "" Vector__XXX
 SG_ PCS2_a015_DcdcAHvOverTemp m0 : 18|1@1+ (1,0) [0|0] "" Vector__XXX
 SG_ PCS2_a075_hvBattFullSensorIrrational m1 : 18|1@1+ (1,0) [0|0] "" Vector__XXX
 SG_ PCS2_a135_backgroundTaskOverRun m2 : 18|1@1+ (1,0) [0|0] "" Vector__XXX
 SG_ PCS2_a016_dcdcATankOverCurrent m0 : 19|1@1+ (1,0) [0|0] "" Vector__XXX
 SG_ PCS2_a076_hvBusFullSensorIrrational m1 : 19|1@1+ (1,0) [0|0] "" Vector__XXX
 SG_ PCS2_a136_cycloAMosfetHealthCheckFailed m2 : 19|1@1+ (1,0) [0|0] "" Vector__XXX
 SG_ PCS2_a017_DcdcBLv2OverTemp m0 : 20|1@1+ (1,0) [0|0] "" Vector__XXX
 SG_ PCS2_a077_lvBusVoltSensorIrrational m1 : 20|1@1+ (1,0) [0|0] "" Vector__XXX
 SG_ PCS2_a137_cycloBMosfetHealthCheckFailed m2 : 20|1@1+ (1,0) [0|0] "" Vector__XXX
 SG_ PCS2_a018_dcdcBTankOverCurrent m0 : 21|1@1+ (1,0) [0|0] "" Vector__XXX
 SG_ PCS2_a078_acL1NVoltageOffsetIrrational m1 : 21|1@1+ (1,0) [0|0] "" Vector__XXX
 SG_ PCS2_a138_unused m2 : 21|1@1+ (1,0) [0|0] "" Vector__XXX
 SG_ PCS2_a019_DcacADcTempTooHigh m0 : 22|1@1+ (1,0) [0|0] "" Vector__XXX
 SG_ PCS2_a079_acL2NVoltageOffsetIrrational m1 : 22|1@1+ (1,0) [0|0] "" Vector__XXX
 SG_ PCS2_a139_unused m2 : 22|1@1+ (1,0) [0|0] "" Vector__XXX
 SG_ PCS2_a020_DcacBDcTempTooHigh m0 : 23|1@1+ (1,0) [0|0] "" Vector__XXX
 SG_ PCS2_a080_acL3NVoltageOffsetIrrational m1 : 23|1@1+ (1,0) [0|0] "" Vector__XXX
 SG_ PCS2_a140_dcdcHalfBusBalancerSaturated m2 : 23|1@1+ (1,0) [0|0] "" Vector__XXX
 SG_ PCS2_a021_powerRailUnderVoltage m0 : 24|1@1+ (1,0) [0|0] "" Vector__XXX
 SG_ PCS2_a081_acL1CurrentOffsetIrrational m1 : 24|1@1+ (1,0) [0|0] "" Vector__XXX
 SG_ PCS2_a141_boostOverCurrent m2 : 24|1@1+ (1,0) [0|0] "" Vector__XXX
 SG_ PCS2_a022_dcacEnableFunctionalityDisabled m0 : 25|1@1+ (1,0) [0|0] "" Vector__XXX
 SG_ PCS2_a082_acL2CurrentOffsetIrrational m1 : 25|1@1+ (1,0) [0|0] "" Vector__XXX
 SG_ PCS2_a142_AcLineGdpsUncalibrated m2 : 25|1@1+ (1,0) [0|0] "" Vector__XXX
 SG_ PCS2_a023_dcdcEnableFunctionalityDisabled m0 : 26|1@1+ (1,0) [0|0] "" Vector__XXX
 SG_ PCS2_a083_acL3CurrentOffsetIrrational m1 : 26|1@1+ (1,0) [0|0] "" Vector__XXX
 SG_ PCS2_a143_AcTankGdpsUncalibrated m2 : 26|1@1+ (1,0) [0|0] "" Vector__XXX
 SG_ PCS2_a024_DcacATxTempTooHigh m0 : 27|1@1+ (1,0) [0|0] "" Vector__XXX
 SG_ PCS2_a084_acNCurrentOffsetIrrational m1 : 27|1@1+ (1,0) [0|0] "" Vector__XXX
 SG_ PCS2_a144_DcTankGdpsUncalibrated m2 : 27|1@1+ (1,0) [0|0] "" Vector__XXX
 SG_ PCS2_a025_DcacBTxTempTooHigh m0 : 28|1@1+ (1,0) [0|0] "" Vector__XXX
 SG_ PCS2_a085_dcacEnableLineDeasserted m1 : 28|1@1+ (1,0) [0|0] "" Vector__XXX
 SG_ PCS2_a145_DcdcHvdcGdpsUncalibrated m2 : 28|1@1+ (1,0) [0|0] "" Vector__XXX
 SG_ PCS2_a026_AcConnectorTempTooHigh m0 : 29|1@1+ (1,0) [0|0] "" Vector__XXX
 SG_ PCS2_a086_dcacLVUnderVoltage m1 : 29|1@1+ (1,0) [0|0] "" Vector__XXX
 SG_ PCS2_a146_acLineSharedCurrentConnectionIssue m2 : 29|1@1+ (1,0) [0|0] "" Vector__XXX
 SG_ PCS2_a027_AmbientTempTooHigh m0 : 30|1@1+ (1,0) [0|0] "" Vector__XXX
 SG_ PCS2_a087_dcacLVOverVoltage m1 : 30|1@1+ (1,0) [0|0] "" Vector__XXX
 SG_ PCS2_a147_powerRailOverVoltage m2 : 30|1@1+ (1,0) [0|0] "" Vector__XXX
 SG_ PCS2_a028_CoolantTempTooHigh m0 : 31|1@1+ (1,0) [0|0] "" Vector__XXX
 SG_ PCS2_a088_chgInputVDropHigh m1 : 31|1@1+ (1,0) [0|0] "" Vector__XXX
 SG_ PCS2_a148_acRelayVoltageIrrational m2 : 31|1@1+ (1,0) [0|0] "" Vector__XXX
 SG_ PCS2_a029_DcacAAc1TempTooHigh m0 : 32|1@1+ (1,0) [0|0] "" Vector__XXX
 SG_ PCS2_a089_EndOfLineModeActivated m1 : 32|1@1+ (1,0) [0|0] "" Vector__XXX
 SG_ PCS2_a149_buckBoostFault m2 : 32|1@1+ (1,0) [0|0] "" Vector__XXX
 SG_ PCS2_a030_DcacAAc2TempTooHigh m0 : 33|1@1+ (1,0) [0|0] "" Vector__XXX
 SG_ PCS2_a090_DcdcLvMosfetTempTooHigh m1 : 33|1@1+ (1,0) [0|0] "" Vector__XXX
 SG_ PCS2_a150_dcdcBurstTimingNotMet m2 : 33|1@1+ (1,0) [0|0] "" Vector__XXX
 SG_ PCS2_a031_DcacBAc1TempTooHigh m0 : 34|1@1+ (1,0) [0|0] "" Vector__XXX
 SG_ PCS2_a091_DcdcTxWindingTempTooHigh m1 : 34|1@1+ (1,0) [0|0] "" Vector__XXX
 SG_ PCS2_a151_DcdcBLv1OverTemp m2 : 34|1@1+ (1,0) [0|0] "" Vector__XXX
 SG_ PCS2_a032_DcacBAc2TempTooHigh m0 : 35|1@1+ (1,0) [0|0] "" Vector__XXX
 SG_ PCS2_a092_dcdc_itankZcdIrrational m1 : 35|1@1+ (1,0) [0|0] "" Vector__XXX
 SG_ PCS2_a152_DcdcBLv3OverTemp m2 : 35|1@1+ (1,0) [0|0] "" Vector__XXX
 SG_ PCS2_a033_swCoreExcessiveUsage m0 : 36|1@1+ (1,0) [0|0] "" Vector__XXX
 SG_ PCS2_a093_cycloPwmsNotInterleaved m1 : 36|1@1+ (1,0) [0|0] "" Vector__XXX
 SG_ PCS2_a153_cyclo_itankZcdIrrational m2 : 36|1@1+ (1,0) [0|0] "" Vector__XXX
 SG_ PCS2_a034_lvBusOverVoltage m0 : 37|1@1+ (1,0) [0|0] "" Vector__XXX
 SG_ PCS2_a094_acChargingUnavailable m1 : 37|1@1+ (1,0) [0|0] "" Vector__XXX
 SG_ PCS2_a154_adcReferenceUncalibrated m2 : 37|1@1+ (1,0) [0|0] "" Vector__XXX
 SG_ PCS2_a035_lvBusUnderVoltage m0 : 38|1@1+ (1,0) [0|0] "" Vector__XXX
 SG_ PCS2_a095_powershareUnavailable m1 : 38|1@1+ (1,0) [0|0] "" Vector__XXX
 SG_ PCS2_a155_vcbatteryMia m2 : 38|1@1+ (1,0) [0|0] "" Vector__XXX
 SG_ PCS2_a036_hvBusOverVoltage m0 : 39|1@1+ (1,0) [0|0] "" Vector__XXX
 SG_ PCS2_a096_vcsuperMia m1 : 39|1@1+ (1,0) [0|0] "" Vector__XXX
 SG_ PCS2_a156_vcfrontMia m2 : 39|1@1+ (1,0) [0|0] "" Vector__XXX
 SG_ PCS2_a037_hvBusUnderVoltage m0 : 40|1@1+ (1,0) [0|0] "" Vector__XXX
 SG_ PCS2_a097_gtwMia m1 : 40|1@1+ (1,0) [0|0] "" Vector__XXX
 SG_ PCS2_a157_VC_pcsManagementMia m2 : 40|1@1+ (1,0) [0|0] "" Vector__XXX
 SG_ PCS2_a038_hvBusTopOverVoltage m0 : 41|1@1+ (1,0) [0|0] "" Vector__XXX
 SG_ PCS2_a098_eggright3Mia m1 : 41|1@1+ (1,0) [0|0] "" Vector__XXX
 SG_ PCS2_a158_DcdcHvMosfetTempTooHigh m2 : 41|1@1+ (1,0) [0|0] "" Vector__XXX
 SG_ PCS2_a039_hvBusTopUnderVoltage m0 : 42|1@1+ (1,0) [0|0] "" Vector__XXX
 SG_ PCS2_a099_LineChassisRmsOV m1 : 42|1@1+ (1,0) [0|0] "" Vector__XXX
 SG_ PCS2_a159_dcdcGdpsHealthCheckFailed m2 : 42|1@1+ (1,0) [0|0] "" Vector__XXX
 SG_ PCS2_a040_hvBusBotOverVoltage m0 : 43|1@1+ (1,0) [0|0] "" Vector__XXX
 SG_ PCS2_a100_LineToLineRmsOV m1 : 43|1@1+ (1,0) [0|0] "" Vector__XXX
 SG_ PCS2_a160_vcleftMia m2 : 43|1@1+ (1,0) [0|0] "" Vector__XXX
 SG_ PCS2_a041_hvBusBotUnderVoltage m0 : 44|1@1+ (1,0) [0|0] "" Vector__XXX
 SG_ PCS2_a101_LineChassisInstantaneousOV m1 : 44|1@1+ (1,0) [0|0] "" Vector__XXX
 SG_ PCS2_a161_vcrearMia m2 : 44|1@1+ (1,0) [0|0] "" Vector__XXX
 SG_ PCS2_a042_hvBattOverVoltage m0 : 45|1@1+ (1,0) [0|0] "" Vector__XXX
 SG_ PCS2_a102_LineToLineInstantaneousOV m1 : 45|1@1+ (1,0) [0|0] "" Vector__XXX
 SG_ PCS2_a162_cycloARoutineTankInductanceMeasurement m2 : 45|1@1+ (1,0) [0|0] "" Vector__XXX
 SG_ PCS2_a043_hvBattUnderVoltage m0 : 46|1@1+ (1,0) [0|0] "" Vector__XXX
 SG_ PCS2_a103_IsoTempSensorIrrational m1 : 46|1@1+ (1,0) [0|0] "" Vector__XXX
 SG_ PCS2_a163_cycloBRoutineTankInductanceMeasurement m2 : 46|1@1+ (1,0) [0|0] "" Vector__XXX
 SG_ PCS2_a044_hvBattTopOverVoltage m0 : 47|1@1+ (1,0) [0|0] "" Vector__XXX
 SG_ PCS2_a104_LineChassisRmsUV m1 : 47|1@1+ (1,0) [0|0] "" Vector__XXX
 SG_ PCS2_a164_dcdc_hwZcdFault1 m2 : 47|1@1+ (1,0) [0|0] "" Vector__XXX
 SG_ PCS2_a045_hvBattTopUnderVoltage m0 : 48|1@1+ (1,0) [0|0] "" Vector__XXX
 SG_ PCS2_a105_LineToLineRmsUV m1 : 48|1@1+ (1,0) [0|0] "" Vector__XXX
 SG_ PCS2_a165_dcdc_hwZcdFault2 m2 : 48|1@1+ (1,0) [0|0] "" Vector__XXX
 SG_ PCS2_a046_hvBattBotOverVoltage m0 : 49|1@1+ (1,0) [0|0] "" Vector__XXX
 SG_ PCS2_a106_systemNeutralChassisRmsOV m1 : 49|1@1+ (1,0) [0|0] "" Vector__XXX
 SG_ PCS2_a166_dcdcEnableLinePWMTripMisconfigured m2 : 49|1@1+ (1,0) [0|0] "" Vector__XXX
 SG_ PCS2_a047_hvBattBotUnderVoltage m0 : 50|1@1+ (1,0) [0|0] "" Vector__XXX
 SG_ PCS2_a107_cycloLostCurrentControl m1 : 50|1@1+ (1,0) [0|0] "" Vector__XXX
 SG_ PCS2_a167_unused m2 : 50|1@1+ (1,0) [0|0] "" Vector__XXX
 SG_ PCS2_a048_dcacOverVoltage m0 : 51|1@1+ (1,0) [0|0] "" Vector__XXX
 SG_ PCS2_a108_FunctionalTestModeActivated m1 : 51|1@1+ (1,0) [0|0] "" Vector__XXX
 SG_ PCS2_a168_gridFormVoltageDropped m2 : 51|1@1+ (1,0) [0|0] "" Vector__XXX
 SG_ PCS2_a049_dcacUnderVoltage m0 : 52|1@1+ (1,0) [0|0] "" Vector__XXX
 SG_ PCS2_a109_ACSurgeProtectionTriggered m1 : 52|1@1+ (1,0) [0|0] "" Vector__XXX
 SG_ PCS2_a169_cycloMosfetHealthCheckMeasuredHalfPrdAsymmetric m2 : 52|1@1+ (1,0) [0|0] "" Vector__XXX
 SG_ PCS2_a050_vcPcsDCDCInterfaceMia m0 : 53|1@1+ (1,0) [0|0] "" Vector__XXX
 SG_ PCS2_a110_acCurrentIsLimited m1 : 53|1@1+ (1,0) [0|0] "" Vector__XXX
 SG_ PCS2_a170_acChargePowerIsLimited m2 : 53|1@1+ (1,0) [0|0] "" Vector__XXX
 SG_ PCS2_a051_bmsMia m0 : 54|1@1+ (1,0) [0|0] "" Vector__XXX
 SG_ PCS2_a111_unused m1 : 54|1@1+ (1,0) [0|0] "" Vector__XXX
 SG_ PCS2_a171_unused m2 : 54|1@1+ (1,0) [0|0] "" Vector__XXX
 SG_ PCS2_a052_cpMia m0 : 55|1@1+ (1,0) [0|0] "" Vector__XXX
 SG_ PCS2_a112_chgInputVDropTooHigh m1 : 55|1@1+ (1,0) [0|0] "" Vector__XXX
 SG_ PCS2_a172_llcDcdcLvBusContention m2 : 55|1@1+ (1,0) [0|0] "" Vector__XXX
 SG_ PCS2_a053_hvDcdcControlMIA m0 : 56|1@1+ (1,0) [0|0] "" Vector__XXX
 SG_ PCS2_a113_dcdcTransientCapabilityImpacted m1 : 56|1@1+ (1,0) [0|0] "" Vector__XXX
 SG_ PCS2_a173_DcdcALv1OverTemp m2 : 56|1@1+ (1,0) [0|0] "" Vector__XXX
 SG_ PCS2_a054_uiMia m0 : 57|1@1+ (1,0) [0|0] "" Vector__XXX
 SG_ PCS2_a114_hvBusEstimatedImpedanceLow m1 : 57|1@1+ (1,0) [0|0] "" Vector__XXX
 SG_ PCS2_a174_unused m2 : 57|1@1+ (1,0) [0|0] "" Vector__XXX
 SG_ PCS2_a055_dcdcATankUncalibrated m0 : 58|1@1+ (1,0) [0|0] "" Vector__XXX
 SG_ PCS2_a115_chgWallPowerRemoval m1 : 58|1@1+ (1,0) [0|0] "" Vector__XXX
 SG_ PCS2_a175_LVUVSurgePowerEvent m2 : 58|1@1+ (1,0) [0|0] "" Vector__XXX
 SG_ PCS2_a056_dcdcBTankUncalibrated m0 : 59|1@1+ (1,0) [0|0] "" Vector__XXX
 SG_ PCS2_a116_chgPersistentFault m1 : 59|1@1+ (1,0) [0|0] "" Vector__XXX
 SG_ PCS2_a176_unused m2 : 59|1@1+ (1,0) [0|0] "" Vector__XXX
 SG_ PCS2_a057_cycloATankUncalibrated m0 : 60|1@1+ (1,0) [0|0] "" Vector__XXX
 SG_ PCS2_a117_vcrightMia m1 : 60|1@1+ (1,0) [0|0] "" Vector__XXX
 SG_ PCS2_a177_unused m2 : 60|1@1+ (1,0) [0|0] "" Vector__XXX
 SG_ PCS2_a058_cycloBTankUncalibrated m0 : 61|1@1+ (1,0) [0|0] "" Vector__XXX
 SG_ PCS2_a118_dcdcFailedToPrechargeToTarget m1 : 61|1@1+ (1,0) [0|0] "" Vector__XXX
 SG_ PCS2_a178_eculogAborted m2 : 61|1@1+ (1,0) [0|0] "" Vector__XXX
 SG_ PCS2_a059_dcdcEnableLineDeasserted m0 : 62|1@1+ (1,0) [0|0] "" Vector__XXX
 SG_ PCS2_a119_useMaxCapForHvImpedanceEstimation m1 : 62|1@1+ (1,0) [0|0] "" Vector__XXX
 SG_ PCS2_a060_cycloAFaulted m0 : 63|1@1+ (1,0) [0|0] "" Vector__XXX
 SG_ PCS2_a120_triggerOdin m1 : 63|1@1+ (1,0) [0|0] "" Vector__XXX

BO_ 997 DIR_alertMatrix4: 8 Vector__XXX
 SG_ DIR_a202_excessHeatUnavailable : 9|1@1+ (1,0) [0|0] "" Vector__XXX
 SG_ DIR_a225_tmpEstPlausibility : 32|1@1+ (1,0) [0|0] "" Vector__XXX
 SG_ DIR_a229_busVsensorOverCAN : 36|1@1+ (1,0) [0|0] "" Vector__XXX
 SG_ DIR_a233_diMsgMissed : 40|1@1+ (1,0) [0|0] "" Vector__XXX
 SG_ DIR_a234_pcsMIA : 41|1@1+ (1,0) [0|0] "" Vector__XXX
 SG_ DIR_a236_tasMIA : 43|1@1+ (1,0) [0|0] "" Vector__XXX
 SG_ DIR_a240_clearFusesRoutine : 47|1@1+ (1,0) [0|0] "" Vector__XXX
 SG_ DIR_a241_systemThermallyLimited : 48|1@1+ (1,0) [0|0] "" Vector__XXX
 SG_ DIR_a242_spinDownLearning : 49|1@1+ (1,0) [0|0] "" Vector__XXX
 SG_ DIR_a243_ecuLogAvailable : 50|1@1+ (1,0) [0|0] "" Vector__XXX
 SG_ DIR_a244_mechSafeStateApplied : 51|1@1+ (1,0) [0|0] "" Vector__XXX
 SG_ DIR_a245_mechSafeStatePreWarn : 52|1@1+ (1,0) [0|0] "" Vector__XXX
 SG_ DIR_a246_recoveryAtSpeedError : 53|1@1+ (1,0) [0|0] "" Vector__XXX
 SG_ DIR_a247_rotorOffsetError : 54|1@1+ (1,0) [0|0] "" Vector__XXX
 SG_ DIR_a248_vehicleSpeedLimited : 55|1@1+ (1,0) [0|0] "" Vector__XXX
 SG_ DIR_a249_highStatorTempFromResist : 56|1@1+ (1,0) [0|0] "" Vector__XXX
 SG_ DIR_a250_preregulatorRail : 57|1@1+ (1,0) [0|0] "" Vector__XXX
 SG_ DIR_a251_oilPumpService : 58|1@1+ (1,0) [0|0] "" Vector__XXX
 SG_ DIR_a252_currentCoreFallback : 59|1@1+ (1,0) [0|0] "" Vector__XXX
 SG_ DIR_a253_lvBoostedRail : 60|1@1+ (1,0) [0|0] "" Vector__XXX
 SG_ DIR_a254_activeDischargeRail : 61|1@1+ (1,0) [0|0] "" Vector__XXX
 SG_ DIR_a255_currentGainFallback : 62|1@1+ (1,0) [0|0] "" Vector__XXX

BO_ 1000 EPBR_alertMatrix: 8 Vector__XXX
 SG_ EPBR_matrixIndex M : 0|4@1+ (1,0) [0|0] "" Vector__XXX
 SG_ EPBR_a001_WatchdogReset m0 : 4|1@1+ (1,0) [0|0] "" Vector__XXX
 SG_ EPBR_a061_XCPConnected m1 : 4|1@1+ (1,0) [0|0] "" Vector__XXX
 SG_ EPBR_a121_nDriveFault m2 : 4|1@1+ (1,0) [0|0] "" Vector__XXX
 SG_ EPBR_a181_TooSteepGradeToPark m3 : 4|1@1+ (1,0) [0|0] "" Vector__XXX
 SG_ EPBR_a241_diOutputLocked m4 : 4|1@1+ (1,0) [0|0] "" Vector__XXX
 SG_ EPBR_a301_oocSpeedViolation m5 : 4|1@1+ (1,0) [0|0] "" Vector__XXX
 SG_ EPBR_a361_espBrakeSwitchInvalid m6 : 4|1@1+ (1,0) [0|0] "" Vector__XXX
 SG_ EPBR_a002_PowerLossReset m0 : 5|1@1+ (1,0) [0|0] "" Vector__XXX
 SG_ EPBR_a062_XCPWasConnected m1 : 5|1@1+ (1,0) [0|0] "" Vector__XXX
 SG_ EPBR_a122_Oc m2 : 5|1@1+ (1,0) [0|0] "" Vector__XXX
 SG_ EPBR_a182_OneEPBAppliedUnsecEnv m3 : 5|1@1+ (1,0) [0|0] "" Vector__XXX
 SG_ EPBR_a242_hvOutputLocked m4 : 5|1@1+ (1,0) [0|0] "" Vector__XXX
 SG_ EPBR_a302_csmLongRelease m5 : 5|1@1+ (1,0) [0|0] "" Vector__XXX
 SG_ EPBR_a362_ibstPressedEspNotPressedMismatch m6 : 5|1@1+ (1,0) [0|0] "" Vector__XXX
 SG_ EPBR_a003_SWAssertion m0 : 6|1@1+ (1,0) [0|0] "" Vector__XXX
 SG_ EPBR_a063_SwitchFault m1 : 6|1@1+ (1,0) [0|0] "" Vector__XXX
 SG_ EPBR_a123_Uc m2 : 6|1@1+ (1,0) [0|0] "" Vector__XXX
 SG_ EPBR_a183_cdpNotAvailable m3 : 6|1@1+ (1,0) [0|0] "" Vector__XXX
 SG_ EPBR_a243_bdwUnavailable m4 : 6|1@1+ (1,0) [0|0] "" Vector__XXX
 SG_ EPBR_a303_clampingOccuredEarly m5 : 6|1@1+ (1,0) [0|0] "" Vector__XXX
 SG_ EPBR_a363_ibstNotPressedEspPressedMismatch m6 : 6|1@1+ (1,0) [0|0] "" Vector__XXX
 SG_ EPBR_a064_busSleepReqTimeout m1 : 7|1@1+ (1,0) [0|0] "" Vector__XXX
 SG_ EPBR_a124_calOutOfBounds m2 : 7|1@1+ (1,0) [0|0] "" Vector__XXX
 SG_ EPBR_a184_dynamicParkAbort m3 : 7|1@1+ (1,0) [0|0] "" Vector__XXX
 SG_ EPBR_a244_WinchModeActive m4 : 7|1@1+ (1,0) [0|0] "" Vector__XXX
 SG_ EPBR_a304_rearSeatControllerEFuseTrip m5 : 7|1@1+ (1,0) [0|0] "" Vector__XXX
 SG_ EPBR_a364_espMasterCylCompOverThreshold m6 : 7|1@1+ (1,0) [0|0] "" Vector__XXX
 SG_ EPBR_a005_CANTXError m0 : 8|1@1+ (1,0) [0|0] "" Vector__XXX
 SG_ EPBR_a125_IdleVMismatch m2 : 8|1@1+ (1,0) [0|0] "" Vector__XXX
 SG_ EPBR_a185_summonAborted m3 : 8|1@1+ (1,0) [0|0] "" Vector__XXX
 SG_ EPBR_a245_serviceModeActive m4 : 8|1@1+ (1,0) [0|0] "" Vector__XXX
 SG_ EPBR_a305_premiumAmpEFuseTrip m5 : 8|1@1+ (1,0) [0|0] "" Vector__XXX
 SG_ EPBR_a365_TooSteepToParkWithTrailerWarning m6 : 8|1@1+ (1,0) [0|0] "" Vector__XXX
 SG_ EPBR_a006_CANTX_cyclicError m0 : 9|1@1+ (1,0) [0|0] "" Vector__XXX
 SG_ EPBR_a126_MotorNVoltLow m2 : 9|1@1+ (1,0) [0|0] "" Vector__XXX
 SG_ EPBR_a186_externalParkAbort m3 : 9|1@1+ (1,0) [0|0] "" Vector__XXX
 SG_ EPBR_a246_idleFaultApply m4 : 9|1@1+ (1,0) [0|0] "" Vector__XXX
 SG_ EPBR_a366_TooSteepToParkWithTrailerUnSecEnv m6 : 9|1@1+ (1,0) [0|0] "" Vector__XXX
 SG_ EPBR_a127_MotorNVoltHigh m2 : 10|1@1+ (1,0) [0|0] "" Vector__XXX
 SG_ EPBR_a187_cdpDynamic m3 : 10|1@1+ (1,0) [0|0] "" Vector__XXX
 SG_ EPBR_a247_csmDynamicApplyRetry m4 : 10|1@1+ (1,0) [0|0] "" Vector__XXX
 SG_ EPBR_a128_MotorPVoltHigh m2 : 11|1@1+ (1,0) [0|0] "" Vector__XXX
 SG_ EPBR_a188_epbDynamic m3 : 11|1@1+ (1,0) [0|0] "" Vector__XXX
 SG_ EPBR_a248_csmDynamicApplyFailed m4 : 11|1@1+ (1,0) [0|0] "" Vector__XXX
 SG_ EPBR_a129_ICR_MIA m2 : 12|1@1+ (1,0) [0|0] "" Vector__XXX
 SG_ EPBR_a189_epbDynamicParkCanceled m3 : 12|1@1+ (1,0) [0|0] "" Vector__XXX
 SG_ EPBR_a249_idleFaultRelease m4 : 12|1@1+ (1,0) [0|0] "" Vector__XXX
 SG_ EPBR_a190_csmApplyDegraded m3 : 13|1@1+ (1,0) [0|0] "" Vector__XXX
 SG_ EPBR_a250_WinchModeCanceled m4 : 13|1@1+ (1,0) [0|0] "" Vector__XXX
 SG_ EPBR_a370_imposterDetected m6 : 13|1@1+ (1,0) [0|0] "" Vector__XXX
 SG_ EPBR_a191_csmReleaseDegraded m3 : 14|1@1+ (1,0) [0|0] "" Vector__XXX
 SG_ EPBR_a251_currentVarianceHigh m4 : 14|1@1+ (1,0) [0|0] "" Vector__XXX
 SG_ EPBR_a012_CPUReset m0 : 15|1@1+ (1,0) [0|0] "" Vector__XXX
 SG_ EPBR_a252_winchModePending m4 : 15|1@1+ (1,0) [0|0] "" Vector__XXX
 SG_ EPBR_a013_AlertManagerFault m0 : 16|1@1+ (1,0) [0|0] "" Vector__XXX
 SG_ EPBR_a253_esmReleaseBlocked m4 : 16|1@1+ (1,0) [0|0] "" Vector__XXX
 SG_ EPBR_a134_NvOv m2 : 17|1@1+ (1,0) [0|0] "" Vector__XXX
 SG_ EPBR_a254_showStalkParkButtonFaultOnUi m4 : 17|1@1+ (1,0) [0|0] "" Vector__XXX
 SG_ EPBR_a015_NVMMError m0 : 18|1@1+ (1,0) [0|0] "" Vector__XXX
 SG_ EPBR_a135_NvUv m2 : 18|1@1+ (1,0) [0|0] "" Vector__XXX
 SG_ EPBR_a195_parkForDriverIsLeaving m3 : 18|1@1+ (1,0) [0|0] "" Vector__XXX
 SG_ EPBR_a016_NVMMRecordError m0 : 19|1@1+ (1,0) [0|0] "" Vector__XXX
 SG_ EPBR_a136_PvOv m2 : 19|1@1+ (1,0) [0|0] "" Vector__XXX
 SG_ EPBR_a196_freeRollModeActive m3 : 19|1@1+ (1,0) [0|0] "" Vector__XXX
 SG_ EPBR_a256_epbSystemApply m4 : 19|1@1+ (1,0) [0|0] "" Vector__XXX
 SG_ EPBR_a137_PvUv m2 : 20|1@1+ (1,0) [0|0] "" Vector__XXX
 SG_ EPBR_a197_freeRollModeAtSpeed m3 : 20|1@1+ (1,0) [0|0] "" Vector__XXX
 SG_ EPBR_a138_NvmDualFailure m2 : 21|1@1+ (1,0) [0|0] "" Vector__XXX
 SG_ EPBR_a198_holdClampComplete m3 : 21|1@1+ (1,0) [0|0] "" Vector__XXX
 SG_ EPBR_a139_NvmRedundancyLoss m2 : 22|1@1+ (1,0) [0|0] "" Vector__XXX
 SG_ EPBR_a140_NvmSlowWrite m2 : 23|1@1+ (1,0) [0|0] "" Vector__XXX
 SG_ EPBR_a200_PmUnparkNotAllowed m3 : 23|1@1+ (1,0) [0|0] "" Vector__XXX
 SG_ EPBR_a021_TaskSchedulerError m0 : 24|1@1+ (1,0) [0|0] "" Vector__XXX
 SG_ EPBR_a081_APP_MIA m1 : 24|1@1+ (1,0) [0|0] "" Vector__XXX
 SG_ EPBR_a141_invalidState m2 : 24|1@1+ (1,0) [0|0] "" Vector__XXX
 SG_ EPBR_a261_winchModeWithoutSteering m4 : 24|1@1+ (1,0) [0|0] "" Vector__XXX
 SG_ EPBR_a022_TaskInitError m0 : 25|1@1+ (1,0) [0|0] "" Vector__XXX
 SG_ EPBR_a082_VCRIGHT_IPC_MIA m1 : 25|1@1+ (1,0) [0|0] "" Vector__XXX
 SG_ EPBR_a202_remoteEpbConfigIncompatible m3 : 25|1@1+ (1,0) [0|0] "" Vector__XXX
 SG_ EPBR_a262_cannotPrepareWinchMode m4 : 25|1@1+ (1,0) [0|0] "" Vector__XXX
 SG_ EPBR_a083_VCLEFT_IPC_MIA m1 : 26|1@1+ (1,0) [0|0] "" Vector__XXX
 SG_ EPBR_a203_hwBrakeTypeMismatch m3 : 26|1@1+ (1,0) [0|0] "" Vector__XXX
 SG_ EPBR_a263_epbRecoveryPark m4 : 26|1@1+ (1,0) [0|0] "" Vector__XXX
 SG_ EPBR_a084_TPMS_MIA m1 : 27|1@1+ (1,0) [0|0] "" Vector__XXX
 SG_ EPBR_a264_winchModeDeactivated m4 : 27|1@1+ (1,0) [0|0] "" Vector__XXX
 SG_ EPBR_a085_CCCM_MIA m1 : 28|1@1+ (1,0) [0|0] "" Vector__XXX
 SG_ EPBR_a086_VCBATT_MIA m1 : 29|1@1+ (1,0) [0|0] "" Vector__XXX
 SG_ EPBR_a087_DIREL_MIA m1 : 30|1@1+ (1,0) [0|0] "" Vector__XXX
 SG_ EPBR_a088_DIRER_MIA m1 : 31|1@1+ (1,0) [0|0] "" Vector__XXX
 SG_ EPBR_a029_CoreDump m0 : 32|1@1+ (1,0) [0|0] "" Vector__XXX
 SG_ EPBR_a089_IBST_MIA m1 : 32|1@1+ (1,0) [0|0] "" Vector__XXX
 SG_ EPBR_a030_ECULogUploadRequest m0 : 33|1@1+ (1,0) [0|0] "" Vector__XXX
 SG_ EPBR_a090_APS_MIA m1 : 33|1@1+ (1,0) [0|0] "" Vector__XXX
 SG_ EPBR_a210_parkForDriverIsLeavingDebug m3 : 33|1@1+ (1,0) [0|0] "" Vector__XXX
 SG_ EPBR_a330_parkForApIsLeaving m5 : 33|1@1+ (1,0) [0|0] "" Vector__XXX
 SG_ EPBR_a031_UDSActive m0 : 34|1@1+ (1,0) [0|0] "" Vector__XXX
 SG_ EPBR_a091_CMPD_MIA m1 : 34|1@1+ (1,0) [0|0] "" Vector__XXX
 SG_ EPBR_a092_VCSEATD_MIA m1 : 35|1@1+ (1,0) [0|0] "" Vector__XXX
 SG_ EPBR_a272_vhclPwrStateMsmtch m4 : 35|1@1+ (1,0) [0|0] "" Vector__XXX
 SG_ EPBR_a093_VCSEATP_MIA m1 : 36|1@1+ (1,0) [0|0] "" Vector__XXX
 SG_ EPBR_a094_EPAS3P_MIA m1 : 37|1@1+ (1,0) [0|0] "" Vector__XXX
 SG_ EPBR_a095_CHG_MIA m1 : 38|1@1+ (1,0) [0|0] "" Vector__XXX
 SG_ EPBR_a096_OCS1P_MIA m1 : 39|1@1+ (1,0) [0|0] "" Vector__XXX
 SG_ EPBR_a216_SPI_MIA_debugData1 m3 : 39|1@1+ (1,0) [0|0] "" Vector__XXX
 SG_ EPBR_a097_CMP_MIA m1 : 40|1@1+ (1,0) [0|0] "" Vector__XXX
 SG_ EPBR_a217_SPI_MIA_debugData2 m3 : 40|1@1+ (1,0) [0|0] "" Vector__XXX
 SG_ EPBR_a098_DIR_MIA m1 : 41|1@1+ (1,0) [0|0] "" Vector__XXX
 SG_ EPBR_a099_PARK_MIA m1 : 42|1@1+ (1,0) [0|0] "" Vector__XXX
 SG_ EPBR_a100_CANbus_MIA m1 : 43|1@1+ (1,0) [0|0] "" Vector__XXX
 SG_ EPBR_a041_HighCPULoad m0 : 44|1@1+ (1,0) [0|0] "" Vector__XXX
 SG_ EPBR_a101_PM_MIA m1 : 44|1@1+ (1,0) [0|0] "" Vector__XXX
 SG_ EPBR_a042_HighStackUsage m0 : 45|1@1+ (1,0) [0|0] "" Vector__XXX
 SG_ EPBR_a102_PTC_MIA m1 : 45|1@1+ (1,0) [0|0] "" Vector__XXX
 SG_ EPBR_a043_Task1msError m0 : 46|1@1+ (1,0) [0|0] "" Vector__XXX
 SG_ EPBR_a103_CP_MIA m1 : 46|1@1+ (1,0) [0|0] "" Vector__XXX
 SG_ EPBR_a044_Task10msError m0 : 47|1@1+ (1,0) [0|0] "" Vector__XXX
 SG_ EPBR_a104_DAS_MIA m1 : 47|1@1+ (1,0) [0|0] "" Vector__XXX
 SG_ EPBR_a045_Task100msError m0 : 48|1@1+ (1,0) [0|0] "" Vector__XXX
 SG_ EPBR_a105_TAS_MIA m1 : 48|1@1+ (1,0) [0|0] "" Vector__XXX
 SG_ EPBR_a225_epbActiveDecel m3 : 48|1@1+ (1,0) [0|0] "" Vector__XXX
 SG_ EPBR_a046_Task1000msError m0 : 49|1@1+ (1,0) [0|0] "" Vector__XXX
 SG_ EPBR_a106_PCS_MIA m1 : 49|1@1+ (1,0) [0|0] "" Vector__XXX
 SG_ EPBR_a107_BMS_MIA m1 : 50|1@1+ (1,0) [0|0] "" Vector__XXX
 SG_ EPBR_a108_DIF_MIA m1 : 51|1@1+ (1,0) [0|0] "" Vector__XXX
 SG_ EPBR_a109_RCM_MIA m1 : 52|1@1+ (1,0) [0|0] "" Vector__XXX
 SG_ EPBR_a110_GTW_MIA m1 : 53|1@1+ (1,0) [0|0] "" Vector__XXX
 SG_ EPBR_a170_12vOv m2 : 53|1@1+ (1,0) [0|0] "" Vector__XXX
 SG_ EPBR_a350_ensOutOfRange m5 : 53|1@1+ (1,0) [0|0] "" Vector__XXX
 SG_ EPBR_a111_EPBR_MIA m1 : 54|1@1+ (1,0) [0|0] "" Vector__XXX
 SG_ EPBR_a171_12vUv m2 : 54|1@1+ (1,0) [0|0] "" Vector__XXX
 SG_ EPBR_a112_EPBL_MIA m1 : 55|1@1+ (1,0) [0|0] "" Vector__XXX
 SG_ EPBR_a172_SPI_MIA m2 : 55|1@1+ (1,0) [0|0] "" Vector__XXX
 SG_ EPBR_a352_audioCurrentSpikeData m5 : 55|1@1+ (1,0) [0|0] "" Vector__XXX
 SG_ EPBR_a113_UI_MIA m1 : 56|1@1+ (1,0) [0|0] "" Vector__XXX
 SG_ EPBR_a173_hiCurrentMissing m2 : 56|1@1+ (1,0) [0|0] "" Vector__XXX
 SG_ EPBR_a353_missingSpeedUnableToPark m5 : 56|1@1+ (1,0) [0|0] "" Vector__XXX
 SG_ EPBR_a114_ESP_MIA m1 : 57|1@1+ (1,0) [0|0] "" Vector__XXX
 SG_ EPBR_a174_csmReleaseFailed m2 : 57|1@1+ (1,0) [0|0] "" Vector__XXX
 SG_ EPBR_a354_parkedForLowBrakeFluidMode m5 : 57|1@1+ (1,0) [0|0] "" Vector__XXX
 SG_ EPBR_a115_VCSEC_MIA m1 : 58|1@1+ (1,0) [0|0] "" Vector__XXX
 SG_ EPBR_a175_csmReleaseRetry m2 : 58|1@1+ (1,0) [0|0] "" Vector__XXX
 SG_ EPBR_a355_brakeHwAndEpbHwMismatch m5 : 58|1@1+ (1,0) [0|0] "" Vector__XXX
 SG_ EPBR_a116_VCRIGHT_MIA m1 : 59|1@1+ (1,0) [0|0] "" Vector__XXX
 SG_ EPBR_a176_csmApplyFailed m2 : 59|1@1+ (1,0) [0|0] "" Vector__XXX
 SG_ EPBR_a356_parkingForStationaryDetect m5 : 59|1@1+ (1,0) [0|0] "" Vector__XXX
 SG_ EPBR_a057_HVP_MIA m0 : 60|1@1+ (1,0) [0|0] "" Vector__XXX
 SG_ EPBR_a117_VCLEFT_MIA m1 : 60|1@1+ (1,0) [0|0] "" Vector__XXX
 SG_ EPBR_a177_csmApplyRetry m2 : 60|1@1+ (1,0) [0|0] "" Vector__XXX
 SG_ EPBR_a357_brakesTooHotForSlope m5 : 60|1@1+ (1,0) [0|0] "" Vector__XXX
 SG_ EPBR_a058_inputRHighSyncDebug m0 : 61|1@1+ (1,0) [0|0] "" Vector__XXX
 SG_ EPBR_a118_VCFRONT_MIA m1 : 61|1@1+ (1,0) [0|0] "" Vector__XXX
 SG_ EPBR_a178_caliperStateUnknown m2 : 61|1@1+ (1,0) [0|0] "" Vector__XXX
 SG_ EPBR_a358_brakesTooHotForSlopeWithOnlyOneEpb m5 : 61|1@1+ (1,0) [0|0] "" Vector__XXX
 SG_ EPBR_a059_inputResistanceHigh m0 : 62|1@1+ (1,0) [0|0] "" Vector__XXX
 SG_ EPBR_a119_SCCM_MIA m1 : 62|1@1+ (1,0) [0|0] "" Vector__XXX
 SG_ EPBR_a179_epbProblem m2 : 62|1@1+ (1,0) [0|0] "" Vector__XXX
 SG_ EPBR_a060_engineeringBuild m0 : 63|1@1+ (1,0) [0|0] "" Vector__XXX
 SG_ EPBR_a120_DI_DRIVE_MIA m1 : 63|1@1+ (1,0) [0|0] "" Vector__XXX
 SG_ EPBR_a180_dynamicActive m2 : 63|1@1+ (1,0) [0|0] "" Vector__XXX
 SG_ EPBR_a300_leftRightConfusion m4 : 63|1@1+ (1,0) [0|0] "" Vector__XXX
 SG_ EPBR_a360_ibstBrakeSwitchInvalid m5 : 63|1@1+ (1,0) [0|0] "" Vector__XXX

BO_ 1001 DAS_bodyControls: 8 Vector__XXX
 SG_ DAS_headlightRequest : 0|2@1+ (1,0) [0|0] "" Vector__XXX
 SG_ DAS_hazardLightRequest : 2|2@1+ (1,0) [0|0] "" Vector__XXX
 SG_ DAS_wiperSpeed : 4|4@1+ (1,0) [0|0] "" Vector__XXX
 SG_ DAS_turnIndicatorRequest : 8|3@1+ (1,0) [0|0] "" Vector__XXX
 SG_ DAS_highLowBeamDecision : 11|2@1+ (1,0) [0|0] "" Vector__XXX
 SG_ DAS_heaterRequest : 13|2@1+ (1,0) [0|0] "" Vector__XXX
 SG_ DAS_highLowBeamOffReason : 15|3@1+ (1,0) [0|0] "" Vector__XXX
 SG_ DAS_forwardCamHeaterDutyCycle : 18|4@1+ (0.06666666666666667,0) [0|0] "" Vector__XXX
 SG_ DAS_dynamicBrakeLightRequest : 22|1@1+ (1,0) [0|0] "" Vector__XXX
 SG_ DAS_radarHeaterRequest : 23|1@1+ (1,0) [0|0] "" Vector__XXX
 SG_ DAS_ahlbOverride : 24|1@1+ (1,0) [0|0] "" Vector__XXX
 SG_ DAS_mirrorFoldRequest : 25|2@1+ (1,0) [0|0] "" Vector__XXX
 SG_ DAS_wiperWashRequest : 27|1@1+ (1,0) [0|0] "" Vector__XXX
 SG_ DAS_ulcConfirmationRequestActive : 28|1@1+ (1,0) [0|0] "" Vector__XXX
 SG_ DAS_overrideWiperSetting : 29|1@1+ (1,0) [0|0] "" Vector__XXX
 SG_ DAS_autoWiperState : 30|3@1+ (1,0) [0|0] "" Vector__XXX
 SG_ DAS_turnIndicatorRequestReason : 33|5@1+ (1,0) [0|0] "" Vector__XXX
 SG_ DAS_forwardRadarPowerRequest : 38|1@1+ (1,0) [0|0] "" Vector__XXX
 SG_ DAS_driverDomeLightRequest : 39|1@1+ (1,0) [0|0] "" Vector__XXX
 SG_ DAS_drivePowerStateRequest : 43|1@1+ (1,0) [0|0] "" Vector__XXX
 SG_ DAS_enableIcrDataCollection : 44|1@1+ (1,0) [0|0] "" Vector__XXX
 SG_ DAS_rPillarCamHeaterDutyCycle : 45|4@1+ (0.06666666666666667,0) [0|0] "" Vector__XXX
 SG_ DAS_adaptiveHighBeamIsFaulted : 49|1@1+ (1,0) [0|0] "" Vector__XXX
 SG_ DAS_restrictDoorReleaseLeft : 50|1@1+ (1,0) [0|0] "" Vector__XXX
 SG_ DAS_restrictDoorReleaseRight : 51|1@1+ (1,0) [0|0] "" Vector__XXX
 SG_ DAS_bodyControlsCounter : 52|4@1+ (1,0) [0|0] "" Vector__XXX
 SG_ DAS_bodyControlsChecksum : 56|8@1+ (1,0) [0|0] "" Vector__XXX

BO_ 1005 GTW_updateStatus: 8 Vector__XXX
 SG_ GTW_i2cUpdateActive : 0|1@0+ (1,0) [0|0] "" Vector__XXX
 SG_ GTW_peripheralConfirmedUpdateNeeded : 4|2@0+ (1,0) [0|0] "" Vector__XXX
 SG_ GTW_ocuFailed : 5|1@1+ (1,0) [0|0] "" Vector__XXX
 SG_ GTW_ecuUpdateStarted : 6|1@1+ (1,0) [0|0] "" Vector__XXX
 SG_ GTW_updateStarted : 7|1@0+ (1,0) [0|0] "" Vector__XXX

VAL_ 946 BMS_log2MuxId 0 "CAC1" 1 "CAC2" 2 "FLOOD_PORT" 3 "VSH_TEST" 4 "CHARGING" 5 "AHR_COUNTER" 6 "1HZ_TASK_STATS" 7 "10HZ_TASK_STATS" 8 "100HZ_1KHZ_TASK_STATS" 9 "CTR_RESISTANCE" 10 "POS_CTR_HEALTH_1" 11 "POS_CTR_HEALTH_2" 12 "POS_CTR_HEALTH_3" 13 "POS_CTR_HEALTH_4" 14 "NEG_CTR_HEALTH_1" 15 "NEG_CTR_HEALTH_2" 16 "NEG_CTR_HEALTH_3" 17 "NEG_CTR_HEALTH_4" 18 "HV_CHAIN_MODEL" 19 "ENERGY_RESERVE" 20 "FC_LINK_LEAKAGE_TEST" 21 "ENERGY_AND_REST_DATA" 22 "CAC3" 23 "BRICK_VOLTAGE_CHANGE" 24 "SOC_BY_OCV_CORRECTION" 25 "VSH_RES_1" 26 "VSH_RES_2" 27 "VSH_RES_3" 28 "HISTOGRAMS_0" 29 "HISTOGRAMS_1" 30 "HISTOGRAMS_2" 31 "HISTOGRAMS_3" 32 "HISTOGRAMS_4" 33 "ALPHA_1" 34 "BRICK_BALANCE_1" 35 "BRICK_BALANCE_2" 36 "BRICK_BALANCE_3" 37 "BRICK_BALANCE_4" 38 "LIFE_MODEL" 39 "BRICK_BLEED_TIMES_1" 40 "BRICK_BLEED_TIMES_2" 41 "BRICK_BLEED_TIMES_3" ;
VAL_ 946 BMS_idealEnergyFloor 1023 "SNA" ;
VAL_ 946 BMS_dynamicEnergyBuffer 1023 "SNA" ;
VAL_ 947 UI_trunkRequest 0 "NONE" 1 "MOVE" 2 "STOP" 3 "SNA" ;
VAL_ 947 UI_lightSwitch 0 "AUTO" 1 "ON" 2 "PARKING" 3 "OFF" 4 "SNA" ;
VAL_ 947 UI_summonState 0 "SNA" 1 "IDLE" 2 "PRE_PRIMED" 3 "ACTIVE" ;
VAL_ 947 UI_autopilotPowerStateRequest 0 "NOMINAL" 1 "SENTRY" 2 "SUSPEND" ;
VAL_ 947 UI_shorted12VCellTestMode 0 "DISABLED" 1 "SHADOW" 2 "ACTIVE" ;
VAL_ 947 UI_dcr12VThreshold 0 "OFF" 1 "40_MILLIOHMS" 2 "35_MILLIOHMS" 3 "30_MILLIOHMS" 4 "27_MILLIOHMS" 5 "24_MILLIOHMS" 6 "22_MILLIOHMS" 7 "20_MILLIOHMS" ;
VAL_ 950 DI_odometer 4294967295 "SNA" ;
VAL_ 957 VCFRONT_energyLossIndex 0 "STATUS" 1 "SINCE_LAST_DRIVE" 2 "SINCE_LAST_DRIVE2" 3 "SINCE_LAST_CHARGE" 4 "SINCE_LAST_CHARGE2" ;
VAL_ 960 VCRIGHT_matrixIndex 0 "AlertMatrix0" 1 "AlertMatrix1" 2 "AlertMatrix2" 3 "AlertMatrix3" 4 "AlertMatrix4" 5 "AlertMatrix5" 6 "AlertMatrix6" 7 "AlertMatrix7" 8 "AlertMatrix8" 9 "AlertMatrix9" ;
VAL_ 962 VCLEFT_switchStatusIndex 0 "0" 1 "1" ;
VAL_ 962 VCLEFT_swcLeftTiltRight 0 "SNA" 1 "OFF" 2 "ON" 3 "FAULT" ;
VAL_ 962 VCLEFT_rightMirrorTilt 0 "STOP" 1 "DOWN" 2 "UP" 3 "RIGHT" 4 "LEFT" ;
VAL_ 962 VCLEFT_swcLeftPressed 0 "SNA" 1 "OFF" 2 "ON" 3 "FAULT" ;
VAL_ 962 VCLEFT_frontSeatTrackBack 0 "SNA" 1 "OFF" 2 "ON" 3 "FAULT" ;
VAL_ 962 VCLEFT_swcRightTiltLeft 0 "SNA" 1 "OFF" 2 "ON" 3 "FAULT" ;
VAL_ 962 VCLEFT_frontSeatTrackForward 0 "SNA" 1 "OFF" 2 "ON" 3 "FAULT" ;
VAL_ 962 VCLEFT_swcRightTiltRight 0 "SNA" 1 "OFF" 2 "ON" 3 "FAULT" ;
VAL_ 962 VCLEFT_frontSeatTiltDown 0 "SNA" 1 "OFF" 2 "ON" 3 "FAULT" ;
VAL_ 962 VCLEFT_swcRightPressed 0 "SNA" 1 "OFF" 2 "ON" 3 "FAULT" ;
VAL_ 962 VCLEFT_frontSeatTiltUp 0 "SNA" 1 "OFF" 2 "ON" 3 "FAULT" ;
VAL_ 962 VCLEFT_swcLeftTiltLeft 0 "SNA" 1 "OFF" 2 "ON" 3 "FAULT" ;
VAL_ 962 VCLEFT_frontSeatLiftDown 0 "SNA" 1 "OFF" 2 "ON" 3 "FAULT" ;
VAL_ 962 VCLEFT_frontSeatLiftUp 0 "SNA" 1 "OFF" 2 "ON" 3 "FAULT" ;
VAL_ 962 VCLEFT_frontSeatBackrestBack 0 "SNA" 1 "OFF" 2 "ON" 3 "FAULT" ;
VAL_ 962 VCLEFT_frontSeatBackrestForward 0 "SNA" 1 "OFF" 2 "ON" 3 "FAULT" ;
VAL_ 962 VCLEFT_frontSeatLumbarDown 0 "SNA" 1 "OFF" 2 "ON" 3 "FAULT" ;
VAL_ 962 VCLEFT_frontSeatLumbarUp 0 "SNA" 1 "OFF" 2 "ON" 3 "FAULT" ;
VAL_ 962 VCLEFT_frontSeatLumbarIn 0 "SNA" 1 "OFF" 2 "ON" 3 "FAULT" ;
VAL_ 962 VCLEFT_frontSeatLumbarOut 0 "SNA" 1 "OFF" 2 "ON" 3 "FAULT" ;
VAL_ 962 VCLEFT_frontBuckleSwitch 0 "SNA" 1 "OFF" 2 "ON" 3 "FAULT" ;
VAL_ 962 VCLEFT_frontOccupancySwitch 0 "SNA" 1 "OFF" 2 "ON" 3 "FAULT" ;
VAL_ 962 VCLEFT_rearLeftBuckleSwitch 0 "SNA" 1 "OFF" 2 "ON" 3 "FAULT" ;
VAL_ 962 VCLEFT_rearCenterOccupancySwitch 0 "SNA" 1 "OFF" 2 "ON" 3 "FAULT" ;
VAL_ 962 VCLEFT_rearLeftOccupancySwitch 0 "SNA" 1 "OFF" 2 "ON" 3 "FAULT" ;
VAL_ 962 VCLEFT_rearRightOccupancySwitch 0 "SNA" 1 "OFF" 2 "ON" 3 "FAULT" ;
VAL_ 962 VCLEFT_rearCenterBuckleSwitch 0 "SNA" 1 "OFF" 2 "ON" 3 "FAULT" ;
VAL_ 963 VCRIGHT_switchStatusIndex 0 "0" 1 "1" 2 "INVALID" ;
VAL_ 963 VCRIGHT_frontSeatTrackBack 0 "SNA" 1 "OFF" 2 "ON" 3 "FAULT" ;
VAL_ 963 VCRIGHT_frontSeatTrackForward 0 "SNA" 1 "OFF" 2 "ON" 3 "FAULT" ;
VAL_ 963 VCRIGHT_frontSeatTiltDown 0 "SNA" 1 "OFF" 2 "ON" 3 "FAULT" ;
VAL_ 963 VCRIGHT_frontSeatTiltUp 0 "SNA" 1 "OFF" 2 "ON" 3 "FAULT" ;
VAL_ 963 VCRIGHT_frontSeatLiftDown 0 "SNA" 1 "OFF" 2 "ON" 3 "FAULT" ;
VAL_ 963 VCRIGHT_frontSeatLiftUp 0 "SNA" 1 "OFF" 2 "ON" 3 "FAULT" ;
VAL_ 963 VCRIGHT_frontSeatBackrestBack 0 "SNA" 1 "OFF" 2 "ON" 3 "FAULT" ;
VAL_ 963 VCRIGHT_frontSeatBackrestForward 0 "SNA" 1 "OFF" 2 "ON" 3 "FAULT" ;
VAL_ 963 VCRIGHT_frontSeatLumbarDown 0 "SNA" 1 "OFF" 2 "ON" 3 "FAULT" ;
VAL_ 963 VCRIGHT_frontSeatLumbarUp 0 "SNA" 1 "OFF" 2 "ON" 3 "FAULT" ;
VAL_ 963 VCRIGHT_frontSeatLumbarIn 0 "SNA" 1 "OFF" 2 "ON" 3 "FAULT" ;
VAL_ 963 VCRIGHT_frontSeatLumbarOut 0 "SNA" 1 "OFF" 2 "ON" 3 "FAULT" ;
VAL_ 963 VCRIGHT_frontBuckleSwitch 0 "SNA" 1 "OFF" 2 "ON" 3 "FAULT" ;
VAL_ 963 VCRIGHT_frontOccupancySwitch 0 "SNA" 1 "OFF" 2 "ON" 3 "FAULT" ;
VAL_ 963 VCRIGHT_rearCenterBuckleSwitch 0 "SNA" 1 "OFF" 2 "ON" 3 "FAULT" ;
VAL_ 963 VCRIGHT_rearRightOccupancySwitch 0 "SNA" 1 "OFF" 2 "ON" 3 "FAULT" ;
VAL_ 964 PCS_infoIndex 0 "DEPRECATED_0" 1 "DEPRECATED_1" 2 "DEPRECATED_2" 3 "DEPRECATED_3" 4 "DEPRECATED_4" 5 "DEPRECATED_5" 6 "DEPRECATED_6" 7 "DEPRECATED_7" 8 "DEPRECATED_8" 9 "DEPRECATED_9" 10 "BUILD_HWID_COMPONENTID" 11 "PCBAID_ASSYID_USAGEID" 13 "APP_CRC" 14 "BOOTLOADER_SVN" 15 "BOOTLOADER_CRC" 16 "SUBCOMPONENT" 17 "APP_GITHASH" 18 "BOOTLOADER_GITHASH" 19 "VERSION_DEPRECATED" 20 "UDS_PROTOCOL_BOOTCRC" 22 "VARIANTCRC" 25 "PACKAGE_PN_1_7" 26 "PACKAGE_PN_8_14" 27 "PACKAGE_PN_15_20" 29 "PACKAGE_SN_1_7" 30 "PACKAGE_SN_8_14" 31 "SUBCOMPONENT_GITHASH" 255 "END" ;
VAL_ 964 PCS_buildType 0 "UNKNOWN_BUILD" 1 "PLATFORM_BUILD" 2 "LOCAL_BUILD" 3 "TRACEABLE_CI_BUILD" 4 "MFG_BUILD" ;
VAL_ 964 PCS_platformType 0 "UNKNOWN" 3 "MODEL3" 255 "END" ;
VAL_ 964 PCS_hardwareId 252 "CONFIGURABLE_HWID_PLACEHOLDER" ;
VAL_ 968 EPBL_matrixIndex 0 "AlertMatrix0" 1 "AlertMatrix1" 2 "AlertMatrix2" 3 "AlertMatrix3" 4 "AlertMatrix4" 5 "AlertMatrix5" ;
VAL_ 969 VCSEC_BLEEndpointInfoIndex 0 "BLELeftInfo" 1 "BLERightInfo" 2 "BLERearInfo" 3 "BLECenterInfo" 4 "BLELeftAppGithash" 5 "BLERightAppGithash" 6 "BLERearAppGithash" 7 "BLECenterAppGithash" 8 "BLEFrontInfo" 9 "BLESecondaryInfo" 10 "BLENFCCradleInfo" 11 "BLELeftRearInfo" 12 "BLERightRearInfo" 13 "BLEFrontAppGithash" 14 "BLESecondaryAppGithash" 15 "BLENFCCradleAppGithash" 16 "BLELeftRearAppGithash" 17 "BLERightRearAppGithash" 18 "UWBLeftInfo" 19 "UWBRightInfo" 20 "UWBRearLeftInfo" 21 "UWBRearRightInfo" 22 "UWBFrontInfo" 23 "UWBLeftAppGithash" 24 "UWBRightAppGithash" 25 "UWBRearLeftAppGithash" 26 "UWBRearRightAppGithash" 27 "UWBFrontAppGithash" ;
VAL_ 972 APS_appStatusMonitorState 0 "STATE_UNKNOWN" 1 "STATE_PWR_OFF" 2 "STATE_INIT" 3 "STATE_NOMINAL" 4 "STATE_CRITICAL" 5 "STATE_SHUTTING_DOWN" 6 "STATE_RECOVERY" 7 "NUM_STATES" ;
VAL_ 972 APS_vehBehaviorState 0 "STATE_UNKNOWN" 1 "STATE_APS_AVAILABLE" 2 "STATE_APS_CONTROL" 3 "STATE_APS_BRIDGE_APP" 4 "STATE_APS_BRIDGE_APB" 5 "STATE_APS_FAIL_SAFE" 6 "STATE_APS_OVERRIDE" 7 "STATE_SYSTEM_FAULT" 8 "NUM_STATES" ;
VAL_ 972 APS_canMaster 0 "APS" 1 "APP" 2 "APB" 3 "SNA" ;
VAL_ 972 APS_appGpioState 0 "PWR_DOWN_REBOOT" 1 "DISABLED" 2 "CRITICAL" 3 "HEALTHY" ;
VAL_ 972 APS_eacInternalState 0 "STATE_INIT" 1 "STATE_MOMENTARY" 2 "STATE_CONTINUOUS" 3 "STATE_AUTOPARK" 4 "STATE_INHIBIT" 5 "STATE_OVERRIDE" 6 "STATE_LSS" 7 "NUM_STATES" ;
VAL_ 972 APS_apbStatusMonitorState 0 "STATE_UNKNOWN" 1 "STATE_PWR_OFF" 2 "STATE_INIT" 3 "STATE_NOMINAL" 4 "STATE_CRITICAL" 5 "STATE_SHUTTING_DOWN" 6 "STATE_RECOVERY" 7 "NUM_STATES" ;
VAL_ 972 APS_apbGpioState 0 "PWR_DOWN_REBOOT" 1 "DISABLED" 2 "CRITICAL" 3 "HEALTHY" ;
VAL_ 972 APS_locLimitReason 0 "NOMINAL_DEFAULT" 1 "NOT_IN_DRIVE" 2 "ACC_AND_AEB_UNAVAILABLE" 3 "PRIMARY_AP_NOT_HEALTHY" 4 "RADAR_NOT_HEALTHY" 5 "NO_RADAR_TARGET" 6 "LOC_MONITOR_UNAVAILABLE" 7 "LOC_LIMITS_EXTENDED" ;
VAL_ 972 APS_appPowerStateRequest 0 "NOMINAL" 1 "SENTRY" 2 "SUSPEND" 3 "SLEEP" ;
VAL_ 972 APS_appPowerStateReason 0 "UI_POWER_STATE_REQUEST" 1 "AP_WDOG_UNHEALTHY" 2 "AP_NM_REASON_SET" 3 "AP_NOT_IN_PARK" 4 "GTW_GOTO_FULL_POWER" 5 "AP_POWER_REQUEST_HYSTERESIS" 6 "AP_POWER_REQUEST_OVERHEATING" 7 "AP_POWER_REQUEST_OVERRIDE" 8 "VC_POWER_REQUEST" 9 "LOADSHED_POWER_REQUEST_PENDING" ;
VAL_ 972 APS_apbPowerStateRequest 0 "NOMINAL" 1 "SENTRY" 2 "SUSPEND" 3 "SLEEP" ;
VAL_ 972 APS_apbPowerStateReason 0 "UI_POWER_STATE_REQUEST" 1 "AP_WDOG_UNHEALTHY" 2 "AP_NM_REASON_SET" 3 "AP_NOT_IN_PARK" 4 "GTW_GOTO_FULL_POWER" 5 "AP_POWER_REQUEST_HYSTERESIS" 6 "AP_POWER_REQUEST_OVERHEATING" 7 "AP_POWER_REQUEST_OVERRIDE" 8 "VC_POWER_REQUEST" 9 "LOADSHED_POWER_REQUEST_PENDING" ;
VAL_ 972 APS_heaterStateDebug 0 "OFF" 1 "ON_HEATING" 2 "ON_NOT_HEATING" 3 "FAULT_OPEN" 4 "FAULT_SHORT" 7 "SNA" ;
VAL_ 972 APS_arbState 0 "INIT" 1 "IDLE" 2 "PRIMARY" 3 "SECONDARY" 4 "FAULT" 5 "MIA" 6 "UNKNOWN" 7 "COUNT" ;
VAL_ 973 VCBATT0_matrixIndex 0 "AlertMatrix0" 1 "AlertMatrix1" 2 "AlertMatrix2" ;
VAL_ 974 VCBATT1_matrixIndex 0 "AlertMatrix0" 1 "AlertMatrix1" 2 "AlertMatrix2" ;
VAL_ 975 VCBATT2_matrixIndex 0 "AlertMatrix0" 1 "AlertMatrix1" 2 "AlertMatrix2" ;
VAL_ 979 VCRIGHT_crashDetectedType 0 "NONE" 1 "MINOR_1" 2 "MINOR_2" 3 "SEVERE" ;
VAL_ 979 VCRIGHT_crashState 0 "IDLE" 1 "MINOR_1" 2 "MINOR_2" 3 "SEVERE" ;
VAL_ 984 UI_elevation 8191 "SNA" ;
VAL_ 989 CP_loggingSlowSelect 0 "0" 1 "1" 2 "2" 3 "3" 4 "4" 5 "5" ;
VAL_ 989 CP_inlet1HarnessIdState 0 "UNKNOWN_SNA" 1 "INVALID" 2 "VALID" ;
VAL_ 989 CP_inlet2HarnessIdState 0 "UNKNOWN_SNA" 1 "INVALID" 2 "VALID" ;
VAL_ 989 CP_inletHeaterState 0 "DISABLED" 1 "ENABLED_HIGHTEMP" 2 "ENABLED_LOWTEMP" 3 "FAULTED" ;
VAL_ 991 UI_linkState 0 "NONE" 1 "CELL" 2 "WIFI" ;
VAL_ 991 UI_sentryModeState 0 "OFF" 1 "IDLE" 2 "ARMED" 3 "AWARE" 4 "PANIC" 5 "QUIET" 6 "SNA" ;
VAL_ 994 VCLEFT_brakeLightStatus 0 "OFF" 1 "ON" 2 "FAULT" 3 "SNA" ;
VAL_ 994 VCLEFT_tailLightStatus 0 "OFF" 1 "ON" 2 "FAULT" 3 "SNA" ;
VAL_ 994 VCLEFT_turnSignalStatus 0 "OFF" 1 "ON" 2 "FAULT" 3 "SNA" ;
VAL_ 994 VCLEFT_FLMapLightStatus 0 "OFF" 1 "ON" 2 "FAULT" 3 "SNA" ;
VAL_ 994 VCLEFT_FRMapLightStatus 0 "OFF" 1 "ON" 2 "FAULT" 3 "SNA" ;
VAL_ 994 VCLEFT_RLMapLightStatus 0 "OFF" 1 "ON" 2 "FAULT" 3 "SNA" ;
VAL_ 994 VCLEFT_RRMapLightStatus 0 "OFF" 1 "ON" 2 "FAULT" 3 "SNA" ;
VAL_ 994 VCLEFT_leftTurnTrailerLightStatus 0 "OFF" 1 "ON" 2 "FAULT" 3 "SNA" ;
VAL_ 994 VCLEFT_rightTrnTrailerLightStatus 0 "OFF" 1 "ON" 2 "FAULT" 3 "SNA" ;
VAL_ 994 VCLEFT_brakeTrailerLightStatus 0 "OFF" 1 "ON" 2 "FAULT" 3 "SNA" ;
VAL_ 994 VCLEFT_tailTrailerLightStatus 0 "OFF" 1 "ON" 2 "FAULT" 3 "SNA" ;
VAL_ 994 VCLEFT_fogTrailerLightStatus 0 "OFF" 1 "ON" 2 "FAULT" 3 "SNA" ;
VAL_ 994 VCLEFT_frontRideHeight 4294967168 "SNA" ;
VAL_ 994 VCLEFT_rearRideHeight 4294967168 "SNA" ;
VAL_ 994 VCLEFT_trailerDetected 0 "SNA" 1 "FAULT" 2 "DETECTED" 3 "NOT_DETECTED" ;
VAL_ 994 VCLEFT_reverseTrailerLightStatus 0 "OFF" 1 "ON" 2 "FAULT" 3 "SNA" ;
VAL_ 995 VCRIGHT_brakeLightStatus 0 "OFF" 1 "ON" 2 "FAULT" 3 "SNA" ;
VAL_ 995 VCRIGHT_tailLightStatus 0 "OFF" 1 "ON" 2 "FAULT" 3 "SNA" ;
VAL_ 995 VCRIGHT_turnSignalStatus 0 "OFF" 1 "ON" 2 "FAULT" 3 "SNA" ;
VAL_ 995 VCRIGHT_reverseLightStatus 0 "OFF" 1 "ON" 2 "FAULT" 3 "SNA" ;
VAL_ 995 VCRIGHT_rearFogLightStatus 0 "OFF" 1 "ON" 2 "FAULT" 3 "SNA" ;
VAL_ 996 PCS2_matrixIndex 0 "AlertMatrix0" 1 "AlertMatrix1" 2 "AlertMatrix2" ;
VAL_ 1000 EPBR_matrixIndex 0 "AlertMatrix0" 1 "AlertMatrix1" 2 "AlertMatrix2" 3 "AlertMatrix3" 4 "AlertMatrix4" 5 "AlertMatrix5" ;
VAL_ 1001 DAS_headlightRequest 0 "OFF" 1 "ON" 3 "INVALID" ;
VAL_ 1001 DAS_hazardLightRequest 0 "OFF" 1 "ON" 2 "UNUSED" 3 "SNA" ;
VAL_ 1001 DAS_wiperSpeed 0 "OFF" 1 "1" 2 "2" 3 "3" 4 "4" 5 "5" 6 "6" 7 "7" 8 "8" 9 "9" 10 "10" 11 "11" 12 "12" 13 "13" 14 "14" 15 "INVALID" ;
VAL_ 1001 DAS_turnIndicatorRequest 0 "NONE" 1 "LEFT" 2 "RIGHT" 3 "CANCEL" 4 "DEFER" ;
VAL_ 1001 DAS_highLowBeamDecision 0 "UNDECIDED" 1 "OFF" 2 "ON" 3 "SNA" ;
VAL_ 1001 DAS_heaterRequest 0 "SNA" 1 "OFF" 2 "ON" ;
VAL_ 1001 DAS_highLowBeamOffReason 0 "ON" 1 "OFF_REASON_MOVING_VISION_TARGET" 2 "OFF_REASON_MOVING_RADAR_TARGET" 3 "OFF_REASON_AMBIENT_LIGHT" 4 "OFF_REASON_HEAD_LIGHT" 5 "OFF_REASON_SNA" ;
VAL_ 1001 DAS_mirrorFoldRequest 0 "NONE" 1 "FOLD" 2 "UNFOLD" 3 "SNA" ;
VAL_ 1001 DAS_autoWiperState 0 "OFF" 1 "SLOW_INTERMITTENT" 2 "FAST_INTERMITTENT" 3 "SLOW_CONTINUOUS" 4 "FAST_CONTINUOUS" 5 "SNA" ;
VAL_ 1001 DAS_turnIndicatorRequestReason 0 "NONE" 1 "ACTIVE_NAV_LANE_CHANGE" 2 "ACTIVE_SPEED_LANE_CHANGE" 3 "ACTIVE_FORK" 4 "CANCEL_LANE_CHANGE" 5 "CANCEL_FORK" 6 "ACTIVE_MERGE" 7 "CANCEL_MERGE" 8 "ACTIVE_COMMANDED_LANE_CHANGE" 9 "ACTIVE_INTERSECTION" 10 "CANCEL_INTERSECTION" 11 "ACTIVE_SUMMMON" 12 "CANCEL_SUMMMON" 13 "ACTIVE_AUTO_PARK" 14 "CANCEL_AUTO_PARK" 15 "CANCEL_MANUAL_BLINKER" 17 "ACTIVE_STATIC_OBJECT_LANE_CHANGE" 18 "ACTIVE_INCORRECT_ROAD_SIDE_LANE_CHANGE" 19 "ACTIVE_EXIT_PASSING_LANE_LANE_CHANGE" 20 "ACTIVE_EXIT_RIGHT_LANE_LANE_CHANGE" 21 "ACTIVE_AWAY_FROM_MERGE_LANE_CHANGE" 22 "ACTIVE_STAY_OUT_OF_RIGHTMOST_LANE_LANE_CHANGE" 23 "ACTIVE_INFEASIBLE_KINEMATICS_LANE_CHANGE" ;
